VERSION ""

NS_ :

BS_:

BU_: EHR_Spare FEHR_3 PTO_SpeedSelector Dummy_Node_Ch2 FEHR_2 TrailerBrake OffBoardDiagnosticTool1_Ch2 PowerTakeOff_Ch2 Transmission1_Ch2 FEHR_1 REHR_5 REHR_4 REHR_3 REHR_2 REHR_1 InstrumentCluster_Ch2 ManagementComputer_Ch2 GWAY_OnBoardDiagnosticUnit_Ch2 GWAY_OffBoardDiagTool1_VB1_Ch2 GWAY_Engine1_Ch2 GWAY_CabDisplay1_Ch2 AuxiliaryValveControl_Ch2
VAL_TABLE_ _________Vt_StatusFlag5 1 "On" 0 "Off" ;

BO_ 3221225472 VECTOR__INDEPENDENT_SIG_MSG: 0 Vector__XXX
 SG_ TrailerParkBrakeRequest : 0|2@1+ (1,0) [0|3] "" Vector__XXX
 SG_ SteeringBrakeDirection : 0|2@1+ (1,0) [0|3] "" Vector__XXX
 SG_ SecondaryBrakeSwitch : 0|2@1+ (1,0) [0|3] "" Vector__XXX
 SG_ PGN_RQST_F9_4C : 0|24@1+ (1,0) [0|16777200] "" Vector__XXX
 SG_ V5_Ref1 : 0|8@1+ (0.05,0) [0|12.75] "V" Vector__XXX
 SG_ V5_Ref2 : 0|8@1+ (0.05,0) [0|12.75] "V" Vector__XXX
 SG_ SensSupplyV_2Sts : 0|2@1+ (1,0) [0|3] "" Vector__XXX
 SG_ SensSupplyV_1 : 0|12@1+ (0.01,0) [0|40.15] "V" Vector__XXX
 SG_ V_12_VH1 : 0|12@1+ (0.01,0) [0|40.15] "V" Vector__XXX
 SG_ V_12_VF1 : 0|12@1+ (0.01,0) [0|40.15] "V" Vector__XXX
 SG_ CalibrOpMode : 0|4@1+ (1,0) [0|15] "" Vector__XXX
 SG_ CalibrVal : 0|10@1+ (1,0) [0|1000] "" Vector__XXX
 SG_ CalibrErrCod : 0|5@1+ (1,0) [0|31] "" Vector__XXX
 SG_ PrsSwSts : 0|2@1+ (1,0) [0|3] "" Vector__XXX
 SG_ CalibrPnt : 0|4@1+ (1,0) [0|15] "" Vector__XXX
 SG_ XPD_MsgCnt : 0|4@1+ (1,0) [0|15] "" Vector__XXX
 SG_ XPD_MsgChksum : 0|4@1+ (1,0) [0|15] "" Vector__XXX
 SG_ PBrakeActvReq : 0|2@1+ (1,0) [0|3] "" Vector__XXX
 SG_ AuxEquipSupplyPrs : 0|8@1+ (8,0) [0|2000] "kPa" Vector__XXX
 SG_ AirSuspnsnSupplyPrs : 0|8@1+ (8,0) [0|2000] "kPa" Vector__XXX
 SG_ AirComprSts : 0|2@1+ (1,0) [0|3] "" Vector__XXX
 SG_ PwtCircAirSupplyPrs : 0|8@1+ (8,0) [0|2000] "kPa" Vector__XXX
 SG_ EngIdleIncSw : 0|2@1+ (1,0) [0|3] "" Vector__XXX
 SG_ EngIdleDecrSw : 0|2@1+ (1,0) [0|3] "" Vector__XXX
 SG_ EngTestModeSw : 0|2@1+ (1,0) [0|3] "" Vector__XXX
 SG_ EngShutdnOverrideSw : 0|2@1+ (1,0) [0|3] "" Vector__XXX
 SG_ EHR_EvNumParamMux_F1 : 0|8@1+ (1,0) [0|255] "" Vector__XXX
 SG_ EHR_EvNumParamMux_F2 : 0|8@1+ (1,0) [0|255] "" Vector__XXX
 SG_ EHR_EvNumParamMux_F3 : 0|8@1+ (1,0) [0|255] "" Vector__XXX
 SG_ EHR_EvNumParamMux_F4 : 0|8@1+ (1,0) [0|255] "" Vector__XXX
 SG_ BrakeSw : 0|2@1+ (1,0) [0|3] "" Vector__XXX
 SG_ CC_AccelSw : 0|2@1+ (1,0) [0|3] "" Vector__XXX
 SG_ CC_Actv : 0|2@1+ (1,0) [0|3] "" Vector__XXX
 SG_ MsgChksum_2 : 0|4@1+ (1,0) [0|15] "count" Vector__XXX
 SG_ CC_CoastDecelSw : 0|2@1+ (1,0) [0|3] "" Vector__XXX
 SG_ CC_EnaSw : 0|2@1+ (1,0) [0|3] "" Vector__XXX
 SG_ CC_PauseSw : 0|2@1+ (1,0) [0|3] "" Vector__XXX
 SG_ CC_ResumSw : 0|2@1+ (1,0) [0|3] "" Vector__XXX
 SG_ CC_SetSpd : 0|8@1+ (1,0) [0|250] "km/h" Vector__XXX
 SG_ CC_SetSw : 0|2@1+ (1,0) [0|3] "" Vector__XXX
 SG_ CC_Sts : 0|3@1+ (1,0) [0|7] "" Vector__XXX
 SG_ CltchSw : 0|2@1+ (1,0) [0|3] "" Vector__XXX
 SG_ N2SpdAxSw : 0|2@1+ (1,0) [0|3] "" Vector__XXX
 SG_ PBrakeRleasInhReq : 0|2@1+ (1,0) [0|3] "" Vector__XXX
 SG_ PBrakeSw : 0|2@1+ (1,0) [0|3] "" Vector__XXX
 SG_ PTO_GovSts : 0|5@1+ (1,0) [0|31] "" Vector__XXX

BO_ 2565350026 ACKM_8A_22: 8 FEHR_2
 SG_ AddrAccssDeny m2 : 32|8@1+ (1,0) [0|255] ""  AuxiliaryValveControl_Ch2
 SG_ AddrAck m0 : 32|8@1+ (1,0) [0|255] ""  AuxiliaryValveControl_Ch2
 SG_ AddrBusy m3 : 32|8@1+ (1,0) [0|255] ""  AuxiliaryValveControl_Ch2
 SG_ AddrNegAck m1 : 32|8@1+ (1,0) [0|255] ""  AuxiliaryValveControl_Ch2
 SG_ CByteAckm M : 0|8@1+ (1,0) [0|255] ""  AuxiliaryValveControl_Ch2
 SG_ GrpFunctValAck m0 : 8|8@1+ (1,0) [0|255] ""  AuxiliaryValveControl_Ch2
 SG_ GrpFunctValNAck m1 : 8|8@1+ (1,0) [0|255] ""  AuxiliaryValveControl_Ch2
 SG_ GrpFunctValNAckAd m2 : 8|8@1+ (1,0) [0|255] ""  AuxiliaryValveControl_Ch2
 SG_ GrpFunctValNAckBusy m3 : 8|8@1+ (1,0) [0|255] ""  AuxiliaryValveControl_Ch2
 SG_ PGN_Ack m0 : 40|24@1+ (1,0) [0|16777200] ""  AuxiliaryValveControl_Ch2
 SG_ PGN_NAck m1 : 40|24@1+ (1,0) [0|16777200] ""  AuxiliaryValveControl_Ch2
 SG_ PGN_NAckAd m2 : 40|24@1+ (1,0) [0|16777200] ""  AuxiliaryValveControl_Ch2
 SG_ PGN_NAckBusy m3 : 40|24@1+ (1,0) [0|16777200] ""  AuxiliaryValveControl_Ch2

BO_ 2566835082 DM2_8A: 18 FEHR_2
 SG_ AmbrWarnLmp : 2|2@1+ (1,0) [0|3] ""  AuxiliaryValveControl_Ch2
 SG_ DTC_01 : 16|32@1+ (1,0) [0|4294970000] ""  AuxiliaryValveControl_Ch2
 SG_ DTC_02 : 48|32@1+ (1,0) [0|4294970000] ""  AuxiliaryValveControl_Ch2
 SG_ DTC_03 : 80|32@1+ (1,0) [0|4294970000] ""  AuxiliaryValveControl_Ch2
 SG_ DTC_04 : 112|32@1+ (1,0) [0|4294970000] ""  AuxiliaryValveControl_Ch2
 SG_ FlashAmbrWarnLmpAWL : 10|2@1+ (1,0) [0|3] ""  AuxiliaryValveControl_Ch2
 SG_ FlashMIL : 14|2@1+ (1,0) [0|3] ""  AuxiliaryValveControl_Ch2
 SG_ FlashProtLmp : 8|2@1+ (1,0) [0|3] ""  AuxiliaryValveControl_Ch2
 SG_ FlashRedStopLmpRSL : 12|2@1+ (1,0) [0|3] ""  AuxiliaryValveControl_Ch2
 SG_ MIL : 6|2@1+ (1,0) [0|3] ""  AuxiliaryValveControl_Ch2
 SG_ ProtLmp : 0|2@1+ (1,0) [0|3] ""  AuxiliaryValveControl_Ch2
 SG_ RedStopLmp : 4|2@1+ (1,0) [0|3] ""  AuxiliaryValveControl_Ch2

BO_ 2566838922 SOFT_8A: 89 FEHR_2
 SG_ Appl_Id_Byte_24 : 552|8@1+ (1,0) [0|255] ""  AuxiliaryValveControl_Ch2
 SG_ Appl_Id_Byte_25 : 560|8@1+ (1,0) [0|255] ""  AuxiliaryValveControl_Ch2
 SG_ Appl_Id_Byte_26 : 568|8@1+ (1,0) [0|255] ""  AuxiliaryValveControl_Ch2
 SG_ Appl_Id_Byte_27 : 576|8@1+ (1,0) [0|255] ""  AuxiliaryValveControl_Ch2
 SG_ Appl_Id_Byte_28 : 584|8@1+ (1,0) [0|255] ""  AuxiliaryValveControl_Ch2
 SG_ Appl_Id_Byte_29 : 592|8@1+ (1,0) [0|255] ""  AuxiliaryValveControl_Ch2
 SG_ Appl_Id_Byte_30 : 600|8@1+ (1,0) [0|255] ""  AuxiliaryValveControl_Ch2
 SG_ Appl_Id_Byte_31 : 608|8@1+ (1,0) [0|255] ""  AuxiliaryValveControl_Ch2
 SG_ Appl_Id_Byte_32 : 616|8@1+ (1,0) [0|255] ""  AuxiliaryValveControl_Ch2
 SG_ Appl_Id_Byte_33 : 624|8@1+ (1,0) [0|255] ""  AuxiliaryValveControl_Ch2
 SG_ Appl_Id_Byte_34 : 632|8@1+ (1,0) [0|255] ""  AuxiliaryValveControl_Ch2
 SG_ Appl_Id_Byte_35 : 640|8@1+ (1,0) [0|255] ""  AuxiliaryValveControl_Ch2
 SG_ Appl_Id_Byte_36 : 648|8@1+ (1,0) [0|255] ""  AuxiliaryValveControl_Ch2
 SG_ Appl_Id_Byte_37 : 656|8@1+ (1,0) [0|255] ""  AuxiliaryValveControl_Ch2
 SG_ Appl_Id_Byte_38 : 664|8@1+ (1,0) [0|255] ""  AuxiliaryValveControl_Ch2
 SG_ Appl_Id_Byte_39 : 672|8@1+ (1,0) [0|255] ""  AuxiliaryValveControl_Ch2
 SG_ Appl_Id_Enum : 680|24@1+ (1,0) [0|16777215] ""  AuxiliaryValveControl_Ch2
 SG_ Bootloader_Id : 360|8@1+ (1,0) [0|255] ""  AuxiliaryValveControl_Ch2
 SG_ Bootloader_Id_Byte_01 : 16|8@1+ (1,0) [0|255] ""  AuxiliaryValveControl_Ch2
 SG_ Bootloader_Id_Byte_02 : 24|8@1+ (1,0) [0|255] ""  AuxiliaryValveControl_Ch2
 SG_ Bootloader_Id_Byte_03 : 32|8@1+ (1,0) [0|255] ""  AuxiliaryValveControl_Ch2
 SG_ Bootloader_Id_Byte_04 : 40|8@1+ (1,0) [0|255] ""  AuxiliaryValveControl_Ch2
 SG_ Bootloader_Id_Byte_05 : 48|8@1+ (1,0) [0|255] ""  AuxiliaryValveControl_Ch2
 SG_ Bootloader_Id_Byte_06 : 56|8@1+ (1,0) [0|255] ""  AuxiliaryValveControl_Ch2
 SG_ Bootloader_Id_Byte_07 : 64|8@1+ (1,0) [0|255] ""  AuxiliaryValveControl_Ch2
 SG_ Bootloader_Id_Byte_08 : 72|8@1+ (1,0) [0|255] ""  AuxiliaryValveControl_Ch2
 SG_ Bootloader_Id_Byte_09 : 80|8@1+ (1,0) [0|255] ""  AuxiliaryValveControl_Ch2
 SG_ Bootloader_Id_Byte_10 : 88|8@1+ (1,0) [0|255] ""  AuxiliaryValveControl_Ch2
 SG_ Bootloader_Id_Byte_11 : 96|8@1+ (1,0) [0|255] ""  AuxiliaryValveControl_Ch2
 SG_ Bootloader_Id_Byte_12 : 104|8@1+ (1,0) [0|255] ""  AuxiliaryValveControl_Ch2
 SG_ Bootloader_Id_Byte_13 : 112|8@1+ (1,0) [0|255] ""  AuxiliaryValveControl_Ch2
 SG_ Bootloader_Id_Byte_14 : 120|8@1+ (1,0) [0|255] ""  AuxiliaryValveControl_Ch2
 SG_ Bootloader_Id_Byte_15 : 128|8@1+ (1,0) [0|255] ""  AuxiliaryValveControl_Ch2
 SG_ Bootloader_Id_Byte_16 : 136|8@1+ (1,0) [0|255] ""  AuxiliaryValveControl_Ch2
 SG_ Bootloader_Id_Byte_17 : 144|8@1+ (1,0) [0|255] ""  AuxiliaryValveControl_Ch2
 SG_ Bootloader_Id_Byte_18 : 152|8@1+ (1,0) [0|255] ""  AuxiliaryValveControl_Ch2
 SG_ Bootloader_Id_Byte_19 : 160|8@1+ (1,0) [0|255] ""  AuxiliaryValveControl_Ch2
 SG_ Bootloader_Id_Byte_20 : 168|8@1+ (1,0) [0|255] ""  AuxiliaryValveControl_Ch2
 SG_ Bootloader_Id_Byte_21 : 176|8@1+ (1,0) [0|255] ""  AuxiliaryValveControl_Ch2
 SG_ Bootloader_Id_Byte_22 : 184|8@1+ (1,0) [0|255] ""  AuxiliaryValveControl_Ch2
 SG_ Bootloader_Id_Byte_23 : 192|8@1+ (1,0) [0|255] ""  AuxiliaryValveControl_Ch2
 SG_ Bootloader_Id_Byte_24 : 200|8@1+ (1,0) [0|255] ""  AuxiliaryValveControl_Ch2
 SG_ Bootloader_Id_Byte_25 : 208|8@1+ (1,0) [0|255] ""  AuxiliaryValveControl_Ch2
 SG_ Bootloader_Id_Byte_26 : 216|8@1+ (1,0) [0|255] ""  AuxiliaryValveControl_Ch2
 SG_ Bootloader_Id_Byte_27 : 224|8@1+ (1,0) [0|255] ""  AuxiliaryValveControl_Ch2
 SG_ Bootloader_Id_Byte_28 : 232|8@1+ (1,0) [0|255] ""  AuxiliaryValveControl_Ch2
 SG_ Bootloader_Id_Byte_29 : 240|8@1+ (1,0) [0|255] ""  AuxiliaryValveControl_Ch2
 SG_ Bootloader_Id_Byte_30 : 248|8@1+ (1,0) [0|255] ""  AuxiliaryValveControl_Ch2
 SG_ Bootloader_Id_Byte_31 : 256|8@1+ (1,0) [0|255] ""  AuxiliaryValveControl_Ch2
 SG_ Bootloader_Id_Byte_32 : 264|8@1+ (1,0) [0|255] ""  AuxiliaryValveControl_Ch2
 SG_ Bootloader_Id_Byte_33 : 272|8@1+ (1,0) [0|255] ""  AuxiliaryValveControl_Ch2
 SG_ Bootloader_Id_Byte_34 : 280|8@1+ (1,0) [0|255] ""  AuxiliaryValveControl_Ch2
 SG_ Bootloader_Id_Byte_35 : 288|8@1+ (1,0) [0|255] ""  AuxiliaryValveControl_Ch2
 SG_ Bootloader_Id_Byte_36 : 296|8@1+ (1,0) [0|255] ""  AuxiliaryValveControl_Ch2
 SG_ Bootloader_Id_Byte_37 : 304|8@1+ (1,0) [0|255] ""  AuxiliaryValveControl_Ch2
 SG_ Bootloader_Id_Byte_38 : 312|8@1+ (1,0) [0|255] ""  AuxiliaryValveControl_Ch2
 SG_ Bootloader_Id_Byte_39 : 320|8@1+ (1,0) [0|255] ""  AuxiliaryValveControl_Ch2
 SG_ Bootloader_Id_Enum : 328|24@1+ (1,0) [0|16777215] ""  AuxiliaryValveControl_Ch2
 SG_ EndStrng_00 : 352|8@1+ (1,0) [0|255] "per byte"  AuxiliaryValveControl_Ch2
 SG_ EndStrng_01 : 704|8@1+ (1,0) [0|255] "per byte"  AuxiliaryValveControl_Ch2
 SG_ NumSW_IdField : 0|8@1+ (1,0) [0|250] "step"  AuxiliaryValveControl_Ch2
 SG_ Appl_Id : 8|8@1+ (1,0) [0|255] ""  AuxiliaryValveControl_Ch2
 SG_ Appl_Id_Byte_01 : 368|8@1+ (1,0) [0|255] ""  AuxiliaryValveControl_Ch2
 SG_ Appl_Id_Byte_02 : 376|8@1+ (1,0) [0|255] ""  AuxiliaryValveControl_Ch2
 SG_ Appl_Id_Byte_03 : 384|8@1+ (1,0) [0|255] ""  AuxiliaryValveControl_Ch2
 SG_ Appl_Id_Byte_04 : 392|8@1+ (1,0) [0|255] ""  AuxiliaryValveControl_Ch2
 SG_ Appl_Id_Byte_05 : 400|8@1+ (1,0) [0|255] ""  AuxiliaryValveControl_Ch2
 SG_ Appl_Id_Byte_06 : 408|8@1+ (1,0) [0|255] ""  AuxiliaryValveControl_Ch2
 SG_ Appl_Id_Byte_07 : 416|8@1+ (1,0) [0|255] ""  AuxiliaryValveControl_Ch2
 SG_ Appl_Id_Byte_08 : 424|8@1+ (1,0) [0|255] ""  AuxiliaryValveControl_Ch2
 SG_ Appl_Id_Byte_09 : 432|8@1+ (1,0) [0|255] ""  AuxiliaryValveControl_Ch2
 SG_ Appl_Id_Byte_10 : 440|8@1+ (1,0) [0|255] ""  AuxiliaryValveControl_Ch2
 SG_ Appl_Id_Byte_11 : 448|8@1+ (1,0) [0|255] ""  AuxiliaryValveControl_Ch2
 SG_ Appl_Id_Byte_12 : 456|8@1+ (1,0) [0|255] ""  AuxiliaryValveControl_Ch2
 SG_ Appl_Id_Byte_13 : 464|8@1+ (1,0) [0|255] ""  AuxiliaryValveControl_Ch2
 SG_ Appl_Id_Byte_14 : 472|8@1+ (1,0) [0|255] ""  AuxiliaryValveControl_Ch2
 SG_ Appl_Id_Byte_15 : 480|8@1+ (1,0) [0|255] ""  AuxiliaryValveControl_Ch2
 SG_ Appl_Id_Byte_16 : 488|8@1+ (1,0) [0|255] ""  AuxiliaryValveControl_Ch2
 SG_ Appl_Id_Byte_17 : 496|8@1+ (1,0) [0|255] ""  AuxiliaryValveControl_Ch2
 SG_ Appl_Id_Byte_18 : 504|8@1+ (1,0) [0|255] ""  AuxiliaryValveControl_Ch2
 SG_ Appl_Id_Byte_19 : 512|8@1+ (1,0) [0|255] ""  AuxiliaryValveControl_Ch2
 SG_ Appl_Id_Byte_20 : 520|8@1+ (1,0) [0|255] ""  AuxiliaryValveControl_Ch2
 SG_ Appl_Id_Byte_21 : 528|8@1+ (1,0) [0|255] ""  AuxiliaryValveControl_Ch2
 SG_ Appl_Id_Byte_22 : 536|8@1+ (1,0) [0|255] ""  AuxiliaryValveControl_Ch2
 SG_ Appl_Id_Byte_23 : 544|8@1+ (1,0) [0|255] ""  AuxiliaryValveControl_Ch2

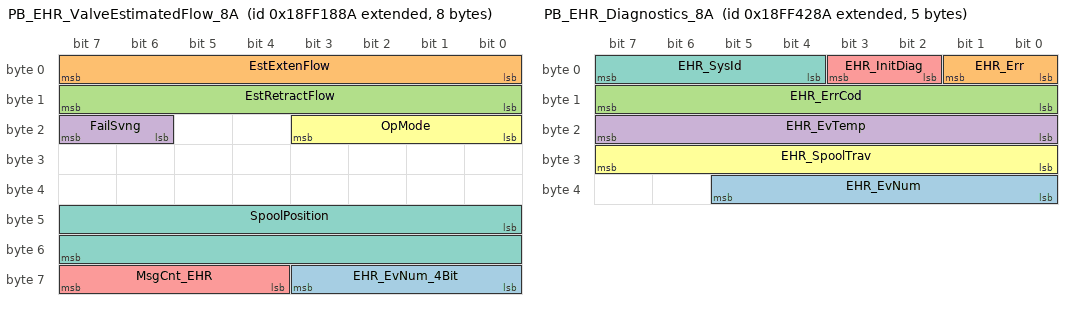
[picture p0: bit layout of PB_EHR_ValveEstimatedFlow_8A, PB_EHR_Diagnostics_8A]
BO_ 2566854794 PB_EHR_ValveEstimatedFlow_8A: 8 FEHR_2
 SG_ EHR_EvNum_4Bit : 56|4@1+ (1,0) [0|15] ""  AuxiliaryValveControl_Ch2
 SG_ EstExtenFlow : 0|8@1+ (0.8,-102.4) [0|100] "%"  AuxiliaryValveControl_Ch2
 SG_ EstRetractFlow : 8|8@1+ (0.8,-102.4) [0|100] "%"  AuxiliaryValveControl_Ch2
 SG_ FailSvng : 22|2@1+ (1,0) [0|3] ""  AuxiliaryValveControl_Ch2
 SG_ MsgCnt_EHR : 60|4@1+ (1,0) [0|12] "count"  AuxiliaryValveControl_Ch2
 SG_ OpMode : 16|4@1+ (1,0) [0|15] ""  AuxiliaryValveControl_Ch2
 SG_ SpoolPosition : 40|16@1+ (1,0) [0|1023] ""  AuxiliaryValveControl_Ch2

BO_ 2566866058 PB_EHR_ParameterStatus_8A: 8 FEHR_2
 SG_ EHR_EvNumParamMux_12 : 24|8@1+ (1,0) [0|255] ""  AuxiliaryValveControl_Ch2
 SG_ EHR_ParamByte_1 : 0|8@1+ (1,0) [0|255] ""  AuxiliaryValveControl_Ch2
 SG_ EHR_ParamStsByte_2 : 8|8@1+ (1,0) [0|255] ""  AuxiliaryValveControl_Ch2
 SG_ EHR_ParamStsByte_3 M : 16|8@1+ (1,0) [0|255] ""  AuxiliaryValveControl_Ch2
 SG_ EHR_RmpRndng m103 : 32|8@1+ (1,0) [0|255] ""  AuxiliaryValveControl_Ch2
 SG_ EHR_ChksumSW m80 : 40|8@1+ (1,0) [0|255] ""  AuxiliaryValveControl_Ch2
 SG_ EHR_ChksumStor m80 : 32|8@1+ (1,0) [0|255] ""  AuxiliaryValveControl_Ch2

BO_ 2566865546 PB_EHR_Diagnostics_8A: 5 FEHR_2
 SG_ EHR_EvNum : 32|6@1+ (1,0) [0|63] ""  AuxiliaryValveControl_Ch2
 SG_ EHR_Err : 0|2@1+ (1,0) [0|3] ""  AuxiliaryValveControl_Ch2
 SG_ EHR_ErrCod : 8|8@1+ (1,0) [0|254] ""  AuxiliaryValveControl_Ch2
 SG_ EHR_EvTemp : 16|8@1+ (1,-80) [-40|120] "Deg C"  AuxiliaryValveControl_Ch2
 SG_ EHR_InitDiag : 2|2@1+ (1,0) [0|3] ""  AuxiliaryValveControl_Ch2
 SG_ EHR_SpoolTrav : 24|8@1+ (1,0) [0|254] ""  AuxiliaryValveControl_Ch2
 SG_ EHR_SysId : 4|4@1+ (1,0) [0|15] ""  AuxiliaryValveControl_Ch2

BO_ 2564487562 ISO15765_Phys_8A_F9: 8 FEHR_2
 SG_ ProtocCntrlInfo M : 4|4@1+ (1,0) [0|3] ""  OffBoardDiagnosticTool1_Ch2
 SG_ SingFrameDataLen m0 : 0|4@1+ (1,0) [0|7] "Byte" Vector__XXX
 SG_ N1FrameDataLen m1 : 3|12@0+ (1,0) [0|4095] "Byte" Vector__XXX
 SG_ FlowSts m3 : 0|4@1+ (1,0) [0|3] "" Vector__XXX
 SG_ BlkSize m3 : 8|8@1+ (1,0) [0|255] "" Vector__XXX
 SG_ SepTime m3 : 16|8@1+ (1,0) [0|255] "ms" Vector__XXX
 SG_ SN m2 : 0|4@1+ (1,0) [0|15] "" Vector__XXX

BO_ 2566843274 CI_8A: 38 FEHR_2
 SG_ UnitNumPwrUnit : 208|8@1+ (1,0) [0|255] "ASCII"  Dummy_Node_Ch2
 SG_ SN_2_Byte_15 : 200|8@1+ (1,0) [0|255] "per byte"  Dummy_Node_Ch2
 SG_ SN_2_Byte_14 : 192|8@1+ (1,0) [0|255] "per byte"  Dummy_Node_Ch2
 SG_ SN_2_Byte_13 : 184|8@1+ (1,0) [0|255] "per byte"  Dummy_Node_Ch2
 SG_ SN_2_Byte_12 : 176|8@1+ (1,0) [0|255] "per byte"  Dummy_Node_Ch2
 SG_ SN_2_Byte_11 : 168|8@1+ (1,0) [0|255] "per byte"  Dummy_Node_Ch2
 SG_ SN_2_Byte_10 : 160|8@1+ (1,0) [0|255] "per byte"  Dummy_Node_Ch2
 SG_ SN_2_Byte_09 : 152|8@1+ (1,0) [0|255] "per byte"  Dummy_Node_Ch2
 SG_ SN_2_Byte_08 : 144|8@1+ (1,0) [0|255] "per byte"  Dummy_Node_Ch2
 SG_ SN_2_Byte_07 : 136|8@1+ (1,0) [0|255] "per byte"  Dummy_Node_Ch2
 SG_ SN_2_Byte_06 : 128|8@1+ (1,0) [0|255] "per byte"  Dummy_Node_Ch2
 SG_ SN_2_Byte_05 : 120|8@1+ (1,0) [0|255] "per byte"  Dummy_Node_Ch2
 SG_ SN_2_Byte_04 : 112|8@1+ (1,0) [0|255] "per byte"  Dummy_Node_Ch2
 SG_ SN_2_Byte_03 : 104|8@1+ (1,0) [0|255] "per byte"  Dummy_Node_Ch2
 SG_ SN_2_Byte_02 : 96|8@1+ (1,0) [0|255] "per byte"  Dummy_Node_Ch2
 SG_ SN_2_Byte_01 : 88|8@1+ (1,0) [0|255] "per byte"  Dummy_Node_Ch2
 SG_ SN_2 : 80|8@1+ (1,0) [0|255] "ASCII"  Dummy_Node_Ch2
 SG_ Mdl_Byte_08 : 72|8@1+ (1,0) [0|255] "ASCII"  Dummy_Node_Ch2
 SG_ Mdl_Byte_07 : 64|8@1+ (1,0) [0|255] "ASCII"  Dummy_Node_Ch2
 SG_ Mdl_Byte_06 : 56|8@1+ (1,0) [0|255] "ASCII"  Dummy_Node_Ch2
 SG_ Mdl_Byte_05 : 48|8@1+ (1,0) [0|255] "ASCII"  Dummy_Node_Ch2
 SG_ Mdl_Byte_04 : 40|8@1+ (1,0) [0|255] "ASCII"  Dummy_Node_Ch2
 SG_ Mdl_Byte_03 : 32|8@1+ (1,0) [0|255] "ASCII"  Dummy_Node_Ch2
 SG_ Mdl_Byte_02 : 24|8@1+ (1,0) [0|255] "ASCII"  Dummy_Node_Ch2
 SG_ Mdl_Byte_01 : 16|8@1+ (1,0) [0|255] "ASCII"  Dummy_Node_Ch2
 SG_ Make : 0|8@1+ (1,0) [0|255] "ASCII"  Dummy_Node_Ch2
 SG_ Mdl : 8|8@1+ (1,0) [0|255] "ASCII"  Dummy_Node_Ch2

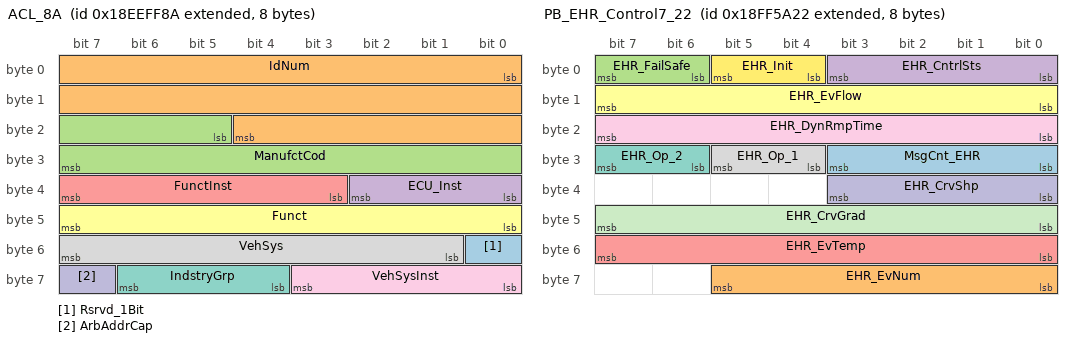
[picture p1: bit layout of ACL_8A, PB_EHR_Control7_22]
BO_ 2565799818 ACL_8A: 8 FEHR_2
 SG_ Rsrvd_1Bit : 48|1@1+ (1,0) [0|1] ""  OffBoardDiagnosticTool1_Ch2,AuxiliaryValveControl_Ch2
 SG_ IdNum : 0|21@1+ (1,0) [0|2097151] ""  OffBoardDiagnosticTool1_Ch2,AuxiliaryValveControl_Ch2
 SG_ ManufctCod : 21|11@1+ (1,0) [0|2047] ""  OffBoardDiagnosticTool1_Ch2,AuxiliaryValveControl_Ch2
 SG_ ECU_Inst : 32|3@1+ (1,0) [0|7] ""  OffBoardDiagnosticTool1_Ch2,AuxiliaryValveControl_Ch2
 SG_ FunctInst : 35|5@1+ (1,0) [0|31] ""  OffBoardDiagnosticTool1_Ch2,AuxiliaryValveControl_Ch2
 SG_ Funct : 40|8@1+ (1,0) [0|255] ""  OffBoardDiagnosticTool1_Ch2,AuxiliaryValveControl_Ch2
 SG_ IndstryGrp : 60|3@1+ (1,0) [0|7] ""  OffBoardDiagnosticTool1_Ch2,AuxiliaryValveControl_Ch2
 SG_ VehSys : 49|7@1+ (1,0) [0|127] ""  OffBoardDiagnosticTool1_Ch2,AuxiliaryValveControl_Ch2
 SG_ VehSysInst : 56|4@1+ (1,0) [0|15] ""  OffBoardDiagnosticTool1_Ch2,AuxiliaryValveControl_Ch2
 SG_ ArbAddrCap : 63|1@1+ (1,0) [0|1] ""  OffBoardDiagnosticTool1_Ch2,AuxiliaryValveControl_Ch2

BO_ 2566871586 PB_EHR_Control7_22: 8 AuxiliaryValveControl_Ch2
 SG_ MsgCnt_EHR : 24|4@1+ (1,0) [0|12] "count"  FEHR_2
 SG_ EHR_EvNum : 56|6@1+ (1,0) [0|63] ""  FEHR_2
 SG_ EHR_FailSafe : 6|2@1+ (1,0) [0|3] ""  FEHR_2
 SG_ EHR_CntrlSts : 0|4@1+ (1,0) [0|15] ""  FEHR_2
 SG_ EHR_EvTemp : 48|8@1+ (1,-80) [-40|120] "Deg C"  FEHR_2
 SG_ EHR_EvFlow : 8|8@1+ (0.3937,0) [0|100] "%"  FEHR_2
 SG_ EHR_Op_2 : 30|2@1+ (1,0) [0|3] ""  FEHR_2
 SG_ EHR_Op_1 : 28|2@1+ (1,0) [0|3] ""  FEHR_2
 SG_ EHR_DynRmpTime : 16|8@1+ (32,0) [0|8128] "ms"  FEHR_2
 SG_ EHR_CrvShp : 32|4@1+ (1,0) [0|15] ""  FEHR_2
 SG_ EHR_CrvGrad : 40|8@1+ (0.3922,0) [0|100] "%"  FEHR_2
 SG_ EHR_Init : 4|2@1+ (1,0) [0|3] ""  FEHR_2

BO_ 2566843265 CI_81: 38 REHR_2
 SG_ UnitNumPwrUnit : 208|8@1+ (1,0) [0|255] "ASCII"  Dummy_Node_Ch2
 SG_ SN_2_Byte_15 : 200|8@1+ (1,0) [0|255] "per byte"  Dummy_Node_Ch2
 SG_ SN_2_Byte_14 : 192|8@1+ (1,0) [0|255] "per byte"  Dummy_Node_Ch2
 SG_ SN_2_Byte_13 : 184|8@1+ (1,0) [0|255] "per byte"  Dummy_Node_Ch2
 SG_ SN_2_Byte_12 : 176|8@1+ (1,0) [0|255] "per byte"  Dummy_Node_Ch2
 SG_ SN_2_Byte_11 : 168|8@1+ (1,0) [0|255] "per byte"  Dummy_Node_Ch2
 SG_ SN_2_Byte_10 : 160|8@1+ (1,0) [0|255] "per byte"  Dummy_Node_Ch2
 SG_ SN_2_Byte_09 : 152|8@1+ (1,0) [0|255] "per byte"  Dummy_Node_Ch2
 SG_ SN_2_Byte_08 : 144|8@1+ (1,0) [0|255] "per byte"  Dummy_Node_Ch2
 SG_ SN_2_Byte_07 : 136|8@1+ (1,0) [0|255] "per byte"  Dummy_Node_Ch2
 SG_ SN_2_Byte_06 : 128|8@1+ (1,0) [0|255] "per byte"  Dummy_Node_Ch2
 SG_ SN_2_Byte_05 : 120|8@1+ (1,0) [0|255] "per byte"  Dummy_Node_Ch2
 SG_ SN_2_Byte_04 : 112|8@1+ (1,0) [0|255] "per byte"  Dummy_Node_Ch2
 SG_ SN_2_Byte_03 : 104|8@1+ (1,0) [0|255] "per byte"  Dummy_Node_Ch2
 SG_ SN_2_Byte_02 : 96|8@1+ (1,0) [0|255] "per byte"  Dummy_Node_Ch2
 SG_ SN_2_Byte_01 : 88|8@1+ (1,0) [0|255] "per byte"  Dummy_Node_Ch2
 SG_ SN_2 : 80|8@1+ (1,0) [0|255] "ASCII"  Dummy_Node_Ch2
 SG_ Mdl_Byte_08 : 72|8@1+ (1,0) [0|255] "ASCII"  Dummy_Node_Ch2
 SG_ Mdl_Byte_07 : 64|8@1+ (1,0) [0|255] "ASCII"  Dummy_Node_Ch2
 SG_ Mdl_Byte_06 : 56|8@1+ (1,0) [0|255] "ASCII"  Dummy_Node_Ch2
 SG_ Mdl_Byte_05 : 48|8@1+ (1,0) [0|255] "ASCII"  Dummy_Node_Ch2
 SG_ Mdl_Byte_04 : 40|8@1+ (1,0) [0|255] "ASCII"  Dummy_Node_Ch2
 SG_ Mdl_Byte_03 : 32|8@1+ (1,0) [0|255] "ASCII"  Dummy_Node_Ch2
 SG_ Mdl_Byte_02 : 24|8@1+ (1,0) [0|255] "ASCII"  Dummy_Node_Ch2
 SG_ Mdl_Byte_01 : 16|8@1+ (1,0) [0|255] "ASCII"  Dummy_Node_Ch2
 SG_ Make : 0|8@1+ (1,0) [0|255] "ASCII"  Dummy_Node_Ch2
 SG_ Mdl : 8|8@1+ (1,0) [0|255] "ASCII"  Dummy_Node_Ch2

BO_ 2564487553 ISO15765_Phys_81_F9: 8 REHR_2
 SG_ SepTime m3 : 16|8@1+ (1,0) [0|255] "ms"  OffBoardDiagnosticTool1_Ch2
 SG_ SingFrameDataLen m0 : 0|4@1+ (1,0) [0|7] "Byte"  OffBoardDiagnosticTool1_Ch2
 SG_ N1FrameDataLen m1 : 3|12@0+ (1,0) [0|4095] "Byte"  OffBoardDiagnosticTool1_Ch2
 SG_ BlkSize m3 : 8|8@1+ (1,0) [0|255] ""  OffBoardDiagnosticTool1_Ch2
 SG_ FlowSts m3 : 0|4@1+ (1,0) [0|3] ""  OffBoardDiagnosticTool1_Ch2
 SG_ SN m2 : 0|4@1+ (1,0) [0|15] ""  OffBoardDiagnosticTool1_Ch2
 SG_ ProtocCntrlInfo M : 4|4@1+ (1,0) [0|3] ""  OffBoardDiagnosticTool1_Ch2

BO_ 2632777721 TPCM_F9: 8 OffBoardDiagnosticTool1_Ch2
 SG_ CByteTPCM M : 0|8@1+ (1,0) [0|255] ""  FEHR_3,FEHR_2,FEHR_1,REHR_5,REHR_4,REHR_3,REHR_2,REHR_1
 SG_ TotMsgSizeTPCM_RTS m16 : 8|16@1+ (1,0) [0|64255] "counts"  FEHR_3,FEHR_2,FEHR_1,REHR_5,REHR_4,REHR_3,REHR_2,REHR_1
 SG_ TotNumPktTPCM_RTS m16 : 24|8@1+ (1,0) [0|255] ""  FEHR_3,FEHR_2,FEHR_1,REHR_5,REHR_4,REHR_3,REHR_2,REHR_1
 SG_ MaxNumPktTPCM_RTS m16 : 32|8@1+ (1,0) [0|255] ""  FEHR_3,FEHR_2,FEHR_1,REHR_5,REHR_4,REHR_3,REHR_2,REHR_1
 SG_ PGN_PktMsgTPCM_RTS m16 : 40|24@1+ (1,0) [0|16777200] ""  FEHR_3,FEHR_2,FEHR_1,REHR_5,REHR_4,REHR_3,REHR_2,REHR_1
 SG_ NumPktSentTPCM_CTS m17 : 8|8@1+ (1,0) [0|255] ""  FEHR_3,FEHR_2,FEHR_1,REHR_5,REHR_4,REHR_3,REHR_2,REHR_1
 SG_ NxtPktNumSentTPCM_CTS m17 : 16|8@1+ (1,0) [0|255] ""  FEHR_3,FEHR_2,FEHR_1,REHR_5,REHR_4,REHR_3,REHR_2,REHR_1
 SG_ ConnAbrtReason m255 : 8|8@1+ (1,0) [0|255] ""  FEHR_3,FEHR_2,FEHR_1,REHR_5,REHR_4,REHR_3,REHR_2,REHR_1
 SG_ TotNumPktBAM m32 : 24|8@1+ (1,0) [0|255] ""  FEHR_3,FEHR_2,FEHR_1,REHR_5,REHR_4,REHR_3,REHR_2,REHR_1
 SG_ TotMsgSizeBAM m32 : 8|16@1+ (1,0) [0|64255] "counts"  FEHR_3,FEHR_2,FEHR_1,REHR_5,REHR_4,REHR_3,REHR_2,REHR_1
 SG_ TotMsgSizeEoMA m19 : 8|16@1+ (1,0) [0|64255] "counts"  FEHR_3,FEHR_2,FEHR_1,REHR_5,REHR_4,REHR_3,REHR_2,REHR_1
 SG_ TotNumPktEoMA m19 : 24|8@1+ (1,0) [0|255] ""  FEHR_3,FEHR_2,FEHR_1,REHR_5,REHR_4,REHR_3,REHR_2,REHR_1
 SG_ PGN_PktMsgTPCM_ConnAbort m255 : 40|24@1+ (1,0) [0|16777200] ""  FEHR_3,FEHR_2,FEHR_1,REHR_5,REHR_4,REHR_3,REHR_2,REHR_1
 SG_ PGN_PktMsgTPCM_BAM m32 : 40|24@1+ (1,0) [0|16777200] ""  FEHR_3,FEHR_2,FEHR_1,REHR_5,REHR_4,REHR_3,REHR_2,REHR_1
 SG_ PGN_PktMsgTPCM_RTS2 m19 : 40|24@1+ (1,0) [0|16777200] ""  FEHR_3,FEHR_2,FEHR_1,REHR_5,REHR_4,REHR_3,REHR_2,REHR_1
 SG_ PGN_PktMsgTPCM_CTS m17 : 40|24@1+ (1,0) [0|16777200] ""  FEHR_3,FEHR_2,FEHR_1,REHR_5,REHR_4,REHR_3,REHR_2,REHR_1

BO_ 2566838521 CA_F9: 9 OffBoardDiagnosticTool1_Ch2
 SG_ NameCmdAddrTarg : 0|64@1+ (1,0) [0|1] ""  FEHR_3,FEHR_2,FEHR_1,REHR_5,REHR_4,REHR_3,REHR_2,REHR_1
 SG_ AddrAssignNewSA : 64|8@1+ (1,0) [0|255] ""  FEHR_3,FEHR_2,FEHR_1,REHR_5,REHR_4,REHR_3,REHR_2,REHR_1

BO_ 2564456697 ISO15765_Phys_F9_80: 8 OffBoardDiagnosticTool1_Ch2
 SG_ BlkSize m3 : 8|8@1+ (1,0) [0|255] ""  REHR_1
 SG_ FlowSts m3 : 0|4@1+ (1,0) [0|3] ""  REHR_1
 SG_ N1FrameDataLen m1 : 3|12@0+ (1,0) [0|4095] "Byte"  REHR_1
 SG_ ProtocCntrlInfo M : 4|4@1+ (1,0) [0|3] ""  REHR_1
 SG_ SepTime m3 : 16|8@1+ (1,0) [0|255] "ms"  REHR_1
 SG_ SingFrameDataLen m0 : 0|4@1+ (1,0) [0|7] "Byte"  REHR_1
 SG_ SN m2 : 0|4@1+ (1,0) [0|15] ""  REHR_1

BO_ 2566843264 CI_80: 38 REHR_1
 SG_ UnitNumPwrUnit : 208|8@1+ (1,0) [0|255] "ASCII"  Dummy_Node_Ch2
 SG_ SN_2_Byte_15 : 200|8@1+ (1,0) [0|255] "per byte"  Dummy_Node_Ch2
 SG_ SN_2_Byte_14 : 192|8@1+ (1,0) [0|255] "per byte"  Dummy_Node_Ch2
 SG_ SN_2_Byte_13 : 184|8@1+ (1,0) [0|255] "per byte"  Dummy_Node_Ch2
 SG_ SN_2_Byte_12 : 176|8@1+ (1,0) [0|255] "per byte"  Dummy_Node_Ch2
 SG_ SN_2_Byte_11 : 168|8@1+ (1,0) [0|255] "per byte"  Dummy_Node_Ch2
 SG_ SN_2_Byte_10 : 160|8@1+ (1,0) [0|255] "per byte"  Dummy_Node_Ch2
 SG_ SN_2_Byte_09 : 152|8@1+ (1,0) [0|255] "per byte"  Dummy_Node_Ch2
 SG_ SN_2_Byte_08 : 144|8@1+ (1,0) [0|255] "per byte"  Dummy_Node_Ch2
 SG_ SN_2_Byte_07 : 136|8@1+ (1,0) [0|255] "per byte"  Dummy_Node_Ch2
 SG_ SN_2_Byte_06 : 128|8@1+ (1,0) [0|255] "per byte"  Dummy_Node_Ch2
 SG_ SN_2_Byte_05 : 120|8@1+ (1,0) [0|255] "per byte"  Dummy_Node_Ch2
 SG_ SN_2_Byte_04 : 112|8@1+ (1,0) [0|255] "per byte"  Dummy_Node_Ch2
 SG_ SN_2_Byte_03 : 104|8@1+ (1,0) [0|255] "per byte"  Dummy_Node_Ch2
 SG_ SN_2_Byte_02 : 96|8@1+ (1,0) [0|255] "per byte"  Dummy_Node_Ch2
 SG_ Mdl_Byte_08 : 72|8@1+ (1,0) [0|255] "ASCII"  Dummy_Node_Ch2
 SG_ Mdl_Byte_07 : 64|8@1+ (1,0) [0|255] "ASCII"  Dummy_Node_Ch2
 SG_ Mdl_Byte_06 : 56|8@1+ (1,0) [0|255] "ASCII"  Dummy_Node_Ch2
 SG_ Mdl_Byte_05 : 48|8@1+ (1,0) [0|255] "ASCII"  Dummy_Node_Ch2
 SG_ Mdl_Byte_04 : 40|8@1+ (1,0) [0|255] "ASCII"  Dummy_Node_Ch2
 SG_ Mdl_Byte_03 : 32|8@1+ (1,0) [0|255] "ASCII"  Dummy_Node_Ch2
 SG_ Mdl_Byte_02 : 24|8@1+ (1,0) [0|255] "ASCII"  Dummy_Node_Ch2
 SG_ Mdl_Byte_01 : 16|8@1+ (1,0) [0|255] "ASCII"  Dummy_Node_Ch2
 SG_ SN_2_Byte_01 : 88|8@1+ (1,0) [0|255] "per byte"  Dummy_Node_Ch2
 SG_ SN_2 : 80|8@1+ (1,0) [0|255] "ASCII"  Dummy_Node_Ch2
 SG_ Make : 0|8@1+ (1,0) [0|255] "ASCII"  Dummy_Node_Ch2
 SG_ Mdl : 8|8@1+ (1,0) [0|255] "ASCII"  Dummy_Node_Ch2

BO_ 2564487552 ISO15765_Phys_80_F9: 8 REHR_1
 SG_ SepTime m3 : 16|8@1+ (1,0) [0|255] "ms"  OffBoardDiagnosticTool1_Ch2
 SG_ SingFrameDataLen m0 : 0|4@1+ (1,0) [0|7] "Byte"  OffBoardDiagnosticTool1_Ch2
 SG_ N1FrameDataLen m1 : 3|12@0+ (1,0) [0|4095] "Byte"  OffBoardDiagnosticTool1_Ch2
 SG_ BlkSize m3 : 8|8@1+ (1,0) [0|255] ""  OffBoardDiagnosticTool1_Ch2
 SG_ FlowSts m3 : 0|4@1+ (1,0) [0|3] ""  OffBoardDiagnosticTool1_Ch2
 SG_ SN m2 : 0|4@1+ (1,0) [0|15] ""  OffBoardDiagnosticTool1_Ch2
 SG_ ProtocCntrlInfo M : 4|4@1+ (1,0) [0|3] ""  OffBoardDiagnosticTool1_Ch2

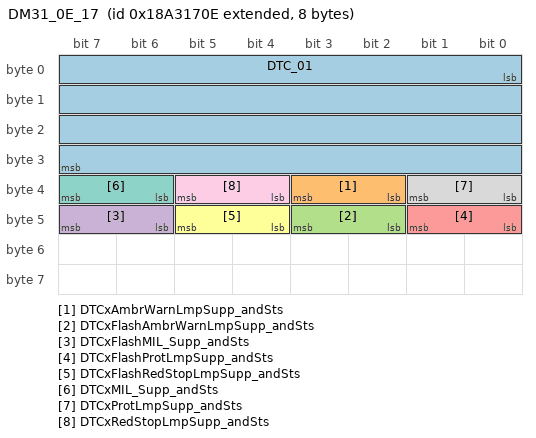
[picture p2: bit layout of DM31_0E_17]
BO_ 2560825102 DM31_0E_17: 8 TrailerBrake
 SG_ DTC_01 : 0|32@1+ (1,0) [0|4294970000] ""  InstrumentCluster_Ch2
 SG_ DTCxAmbrWarnLmpSupp_andSts : 34|2@1+ (1,0) [0|3] ""  InstrumentCluster_Ch2
 SG_ DTCxFlashAmbrWarnLmpSupp_andSts : 42|2@1+ (1,0) [0|3] ""  InstrumentCluster_Ch2
 SG_ DTCxFlashMIL_Supp_andSts : 46|2@1+ (1,0) [0|3] ""  InstrumentCluster_Ch2
 SG_ DTCxFlashProtLmpSupp_andSts : 40|2@1+ (1,0) [0|3] ""  InstrumentCluster_Ch2
 SG_ DTCxFlashRedStopLmpSupp_andSts : 44|2@1+ (1,0) [0|3] ""  InstrumentCluster_Ch2
 SG_ DTCxMIL_Supp_andSts : 38|2@1+ (1,0) [0|3] ""  InstrumentCluster_Ch2
 SG_ DTCxProtLmpSupp_andSts : 32|2@1+ (1,0) [0|3] ""  InstrumentCluster_Ch2
 SG_ DTCxRedStopLmpSupp_andSts : 36|2@1+ (1,0) [0|3] ""  InstrumentCluster_Ch2

BO_ 2632712073 TPDT_89: 8 FEHR_1
 SG_ PktDataTPDT : 8|56@1+ (1,0) [0|7.20575940379279E+16] ""  InstrumentCluster_Ch2
 SG_ SN_TPDT : 0|8@1+ (1,0) [0|255] ""  InstrumentCluster_Ch2

BO_ 2632712074 TPDT_8A: 8 FEHR_2
 SG_ PktDataTPDT : 8|56@1+ (1,0) [0|7.20575940379279E+16] ""  InstrumentCluster_Ch2
 SG_ SN_TPDT : 0|8@1+ (1,0) [0|255] ""  InstrumentCluster_Ch2

BO_ 2632777609 TPCM_89: 8 FEHR_1
 SG_ CByteTPCM M : 0|8@1+ (1,0) [0|255] ""  InstrumentCluster_Ch2
 SG_ ConnAbrtReason m255 : 8|8@1+ (1,0) [0|255] ""  InstrumentCluster_Ch2
 SG_ MaxNumPktTPCM_RTS m16 : 32|8@1+ (1,0) [0|255] ""  InstrumentCluster_Ch2
 SG_ NumPktSentTPCM_CTS m17 : 8|8@1+ (1,0) [0|255] ""  InstrumentCluster_Ch2
 SG_ NxtPktNumSentTPCM_CTS m17 : 16|8@1+ (1,0) [0|255] ""  InstrumentCluster_Ch2
 SG_ PGN_PktMsgTPCM_BAM m32 : 40|24@1+ (1,0) [0|16777200] ""  InstrumentCluster_Ch2
 SG_ PGN_PktMsgTPCM_ConnAbort m255 : 40|24@1+ (1,0) [0|16777200] ""  InstrumentCluster_Ch2
 SG_ PGN_PktMsgTPCM_CTS m17 : 40|24@1+ (1,0) [0|16777200] ""  InstrumentCluster_Ch2
 SG_ PGN_PktMsgTPCM_RTS m16 : 40|24@1+ (1,0) [0|16777200] ""  InstrumentCluster_Ch2
 SG_ PGN_PktMsgTPCM_RTS2 m19 : 40|24@1+ (1,0) [0|16777200] ""  InstrumentCluster_Ch2
 SG_ TotMsgSizeBAM m32 : 8|16@1+ (1,0) [0|64255] "counts"  InstrumentCluster_Ch2
 SG_ TotMsgSizeEoMA m19 : 8|16@1+ (1,0) [0|64255] "counts"  InstrumentCluster_Ch2
 SG_ TotMsgSizeTPCM_RTS m16 : 8|16@1+ (1,0) [0|64255] "counts"  InstrumentCluster_Ch2
 SG_ TotNumPktBAM m32 : 24|8@1+ (1,0) [0|255] ""  InstrumentCluster_Ch2
 SG_ TotNumPktEoMA m19 : 24|8@1+ (1,0) [0|255] ""  InstrumentCluster_Ch2
 SG_ TotNumPktTPCM_RTS m16 : 24|8@1+ (1,0) [0|255] ""  InstrumentCluster_Ch2

CM_ BU_ Dummy_Node_Ch2 "Dummy_Node is not a real node connected to the Network. It's used to receive signals/messages not managed by other ECUs connected to CAN Bus";
CM_ BU_ GWAY_OnBoardDiagnosticUnit_Ch2 "Node inserted to forward Display messages from CAN1 to CAN2.";
CM_ BU_ GWAY_OffBoardDiagTool1_VB1_Ch2 "Node inserted to forward EST messages from CAN1 to CAN2.";
CM_ BU_ GWAY_Engine1_Ch2 "Node inserted to forward Engine messages from CAN1 to CAN2.";
CM_ BU_ GWAY_CabDisplay1_Ch2 "Node inserted to forward Display messages from CAN1 to CAN2.";
CM_ BO_ 3221225472 "This is a message for not used signals, created by Vector CANdb++ DBC OLE DB Provider.";
CM_ SG_ 3221225472 TrailerParkBrakeRequest "Switch signal which indicates drivers demand to activate the trailer park brake.";
CM_ SG_ 3221225472 SteeringBrakeDirection "Switch signal which indicates the direction for steering brake in case only one brake switch signal is used.";
CM_ SG_ 3221225472 SecondaryBrakeSwitch "Switch signal which indicates that the driver operated secondary brake / handbrake is being pressed. Brake demand for secondary brake function in eTCV.";
CM_ SG_ 3221225472 PGN_RQST_F9_4C "PGN superset list which is requested by Request message";
CM_ SG_ 3221225472 CalibrOpMode "A status signal indicating the current calibration status.";
CM_ SG_ 3221225472 CalibrVal "The calibration parameter against each calibration point.";
CM_ SG_ 3221225472 PrsSwSts "A status signal indicating the status of the temporary pressure switch fitted during the EHR on-board calibration process.";
CM_ SG_ 3221225472 CalibrPnt "A status signal indicating which spool calibration point currently under consideration.";
CM_ SG_ 3221225472 XPD_MsgCnt "The XPR message counter is to verify the signal path from the demanding device to the electronic trailer valve controller on electronic brake systems. every following message the counter is incremented by 1 (0 follows 15).";
CM_ SG_ 3221225472 XPD_MsgChksum "The 4 bit XPR msg chksum is calculated with first 7 data bytes, the 4 bit message counter and the bytes of the msg ID. For algorithm refer to SPN 3188 in Digital Annex
";
CM_ SG_ 3221225472 AuxEquipSupplyPrs "The pneumatic pressure in the auxiliary circuit.";
CM_ SG_ 3221225472 AirSuspnsnSupplyPrs "The pneumatic pressure in the circuit for the electronically controlled air suspension system.";
CM_ SG_ 3221225472 AirComprSts "Indicates whether the air compressor is actively compressing air.";
CM_ SG_ 3221225472 PwtCircAirSupplyPrs "Supply pressure to carry the pressure information for the powertrain circuit. This circuit typically would feed powertrain components such as throttles, gearbox actuators and aftertreatment actuators for EGR and SCR systems.";
CM_ SG_ 3221225472 EngIdleIncSw "Not used FFh.";
CM_ SG_ 3221225472 EngIdleDecrSw "Not used FFh.";
CM_ SG_ 3221225472 EngTestModeSw "Not used FFh.";
CM_ SG_ 3221225472 EngShutdnOverrideSw "Not used FFh.";
CM_ SG_ 3221225472 EHR_EvNumParamMux_F1 "A status signal indicating the EHR valve number. Used for front & rear EHR's.";
CM_ SG_ 3221225472 EHR_EvNumParamMux_F2 "A status signal indicating the EHR valve number. Used for front & rear EHR's.";
CM_ SG_ 3221225472 EHR_EvNumParamMux_F3 "A status signal indicating the EHR valve number. Used for front & rear EHR's.";
CM_ SG_ 3221225472 EHR_EvNumParamMux_F4 "A status signal indicating the EHR valve number. Used for front & rear EHR's.";
CM_ SG_ 3221225472 BrakeSw "Switch signal which indicates that the driver operated brake foot pedal is being pressed.  This brake foot pedal is ...";
CM_ SG_ 3221225472 CC_AccelSw "Switch signal of the cruise control activator which indicates that the activator is in the position “accelerate.” ...";
CM_ SG_ 3221225472 CC_Actv "Cruise control is switched on.  It is not ensured that the engine is controlled by cruise control, as in the case of a large ...";
CM_ SG_ 3221225472 MsgChksum_2 "The message checksum is used to verify the signal path from the transmitting device to the receiving device.";
CM_ SG_ 3221225472 CC_CoastDecelSw "Switch signal of the cruise control activator which indicates that the activator is in the position “coast (decelerate).” ...";
CM_ SG_ 3221225472 CC_EnaSw "Switch signal which indicates that it is possible to manage the cruise control function.";
CM_ SG_ 3221225472 CC_PauseSw "Switch signal which indicates the position of the Cruise Control Pause Switch used on Remote Cruise Control ...";
CM_ SG_ 3221225472 CC_ResumSw "Switch signal of the cruise control activator which indicates that the activator is in the position “resume.” ...";
CM_ SG_ 3221225472 CC_SetSpd "Value of set (chosen) velocity of velocity control system.";
CM_ SG_ 3221225472 CC_SetSw "Switch signal of the cruise control activator which indicates that the activator is in the position “set.” ...";
CM_ SG_ 3221225472 CC_Sts "This parameter is used to indicate the current state, or mode, of operation by the cruise control device.  This is a status ...";
CM_ SG_ 3221225472 CltchSw "Switch signal which indicates that the clutch pedal is being pressed. It is necessary for a safe drivetrain behavior that the ...";
CM_ SG_ 3221225472 N2SpdAxSw "Switch signal which indicates the current axle range.";
CM_ SG_ 3221225472 PBrakeRleasInhReq "Park Brake Release Inhibit Request signals the desire that an applied park brake remain applied and limit the ability of the ...";
CM_ SG_ 3221225472 PBrakeSw "Switch signal which indicates when the parking brake is set. In general the switch actuated by the operators park brake ...";
CM_ SG_ 3221225472 PTO_GovSts "This parameter is used to indicate the current state or mode of operation by the power takeoff (PTO) governor.  In lieu of ...";
CM_ BO_ 2565350026 "Acknowledgment Message";
CM_ SG_ 2565350026 GrpFunctValAck "Group Function of PGN being acknowledged. This field identifies for a device the specific group function of a PGN being acknowledged or declined.  This field is not used if the PGN being acknowledged or declined is not a group function PGN.";
CM_ SG_ 2565350026 GrpFunctValNAck "Group Function of PGN being acknowledged. This field identifies for a device the specific group function of a PGN being acknowledged or declined.  This field is not used if the PGN being acknowledged or declined is not a group function PGN.";
CM_ SG_ 2565350026 GrpFunctValNAckAd "Group Function of PGN being acknowledged. This field identifies for a device the specific group function of a PGN being acknowledged or declined.  This field is not used if the PGN being acknowledged or declined is not a group function PGN.";
CM_ SG_ 2565350026 GrpFunctValNAckBusy "Group Function of PGN being acknowledged. This field identifies for a device the specific group function of a PGN being acknowledged or declined.  This field is not used if the PGN being acknowledged or declined is not a group function PGN.";
CM_ SG_ 2565350026 PGN_Ack "PGN which is requested by Request2 message";
CM_ SG_ 2565350026 PGN_NAck "PGN which is requested by Request2 message";
CM_ SG_ 2565350026 PGN_NAckAd "PGN which is requested by Request2 message";
CM_ SG_ 2565350026 PGN_NAckBusy "PGN which is requested by Request2 message";
CM_ BO_ 2566835082 "Previously active diagnostic trouble codes";
CM_ SG_ 2566835082 AmbrWarnLmp "This lamp is used to relay trouble code information that is reporting a problem with the vehicle system but the vehicle need...";
CM_ SG_ 2566835082 DTC_01 "Diagnostic Trouble Code";
CM_ SG_ 2566835082 DTC_02 "Diagnostic Trouble Code";
CM_ SG_ 2566835082 DTC_03 "Diagnostic Trouble Code";
CM_ SG_ 2566835082 DTC_04 "Diagnostic Trouble Code";
CM_ SG_ 2566835082 FlashAmbrWarnLmpAWL "This parameter provides the capability to flash the AWL (SPN 3040).";
CM_ SG_ 2566835082 FlashMIL "This parameter provides the capability to flash the MIL (SPN 3038).";
CM_ SG_ 2566835082 FlashProtLmp "This parameter provides the capability to flash the engine protect lamp (SPN 3041).";
CM_ SG_ 2566835082 FlashRedStopLmpRSL "This parameter provides the capability to flash the RSL (SPN 3039).";
CM_ SG_ 2566835082 MIL "A lamp used to relay only emissions-related trouble code information.";
CM_ SG_ 2566835082 ProtLmp "This lamp is used to relay trouble code informatio that is reporting a problem with a vehicle system that is most...";
CM_ SG_ 2566835082 RedStopLmp "This lamp is used to relay trouble code information that is of a severe enought condition that it warrants stopping the vehicle.";
CM_ BO_ 2566838922 "Software Identification. 'On request'. Variable DLC for Joystick Steering Valve (Danfoss) 11 identification fields (see signals) separated by  '*'";
CM_ SG_ 2566838922 Appl_Id_Byte_24 "Software ID. Set to P826vxx or to P662vxx";
CM_ SG_ 2566838922 Appl_Id_Byte_25 "Software ID. Set to P826vxx or to P662vxx";
CM_ SG_ 2566838922 Appl_Id_Byte_26 "Software ID. Set to P826vxx or to P662vxx";
CM_ SG_ 2566838922 Appl_Id_Byte_27 "Software ID. Set to P826vxx or to P662vxx";
CM_ SG_ 2566838922 Appl_Id_Byte_28 "Software ID. Set to P826vxx or to P662vxx";
CM_ SG_ 2566838922 Appl_Id_Byte_29 "Software ID. Set to P826vxx or to P662vxx";
CM_ SG_ 2566838922 Appl_Id_Byte_30 "Software ID. Set to P826vxx or to P662vxx";
CM_ SG_ 2566838922 Appl_Id_Byte_31 "Software ID. Set to P826vxx or to P662vxx";
CM_ SG_ 2566838922 Appl_Id_Byte_32 "Software ID. Set to P826vxx or to P662vxx";
CM_ SG_ 2566838922 Appl_Id_Byte_33 "Software ID. Set to P826vxx or to P662vxx";
CM_ SG_ 2566838922 Appl_Id_Byte_34 "Software ID. Set to P826vxx or to P662vxx";
CM_ SG_ 2566838922 Appl_Id_Byte_35 "Software ID. Set to P826vxx or to P662vxx";
CM_ SG_ 2566838922 Appl_Id_Byte_36 "Software ID. Set to P826vxx or to P662vxx";
CM_ SG_ 2566838922 Appl_Id_Byte_37 "Software ID. Set to P826vxx or to P662vxx";
CM_ SG_ 2566838922 Appl_Id_Byte_38 "Software ID. Set to P826vxx or to P662vxx";
CM_ SG_ 2566838922 Appl_Id_Byte_39 "Software ID. Set to P826vxx or to P662vxx";
CM_ SG_ 2566838922 Appl_Id_Enum "Software ID.";
CM_ SG_ 2566838922 Bootloader_Id "Software ID.";
CM_ SG_ 2566838922 Bootloader_Id_Byte_01 "Software ID.";
CM_ SG_ 2566838922 Bootloader_Id_Byte_02 "Software ID.";
CM_ SG_ 2566838922 Bootloader_Id_Byte_03 "Software ID.";
CM_ SG_ 2566838922 Bootloader_Id_Byte_04 "Software ID.";
CM_ SG_ 2566838922 Bootloader_Id_Byte_05 "Software ID.";
CM_ SG_ 2566838922 Bootloader_Id_Byte_06 "Software ID.";
CM_ SG_ 2566838922 Bootloader_Id_Byte_07 "Software ID.";
CM_ SG_ 2566838922 Bootloader_Id_Byte_08 "Software ID.";
CM_ SG_ 2566838922 Bootloader_Id_Byte_09 "Software ID.";
CM_ SG_ 2566838922 Bootloader_Id_Byte_10 "Software ID.";
CM_ SG_ 2566838922 Bootloader_Id_Byte_11 "Software ID.";
CM_ SG_ 2566838922 Bootloader_Id_Byte_12 "Software ID.";
CM_ SG_ 2566838922 Bootloader_Id_Byte_13 "Software ID.";
CM_ SG_ 2566838922 Bootloader_Id_Byte_14 "Software ID.";
CM_ SG_ 2566838922 Bootloader_Id_Byte_15 "Software ID.";
CM_ SG_ 2566838922 Bootloader_Id_Byte_16 "Software ID.";
CM_ SG_ 2566838922 Bootloader_Id_Byte_17 "Software ID.";
CM_ SG_ 2566838922 Bootloader_Id_Byte_18 "Software ID.";
CM_ SG_ 2566838922 Bootloader_Id_Byte_19 "Software ID.";
CM_ SG_ 2566838922 Bootloader_Id_Byte_20 "Software ID.";
CM_ SG_ 2566838922 Bootloader_Id_Byte_21 "Software ID.";
CM_ SG_ 2566838922 Bootloader_Id_Byte_22 "Software ID.";
CM_ SG_ 2566838922 Bootloader_Id_Byte_23 "Software ID.";
CM_ SG_ 2566838922 Bootloader_Id_Byte_24 "Software ID.";
CM_ SG_ 2566838922 Bootloader_Id_Byte_25 "Software ID.";
CM_ SG_ 2566838922 Bootloader_Id_Byte_26 "Software ID.";
CM_ SG_ 2566838922 Bootloader_Id_Byte_27 "Software ID.";
CM_ SG_ 2566838922 Bootloader_Id_Byte_28 "Software ID.";
CM_ SG_ 2566838922 Bootloader_Id_Byte_29 "Software ID.";
CM_ SG_ 2566838922 Bootloader_Id_Byte_30 "Software ID.";
CM_ SG_ 2566838922 Bootloader_Id_Byte_31 "Software ID.";
CM_ SG_ 2566838922 Bootloader_Id_Byte_32 "Software ID.";
CM_ SG_ 2566838922 Bootloader_Id_Byte_33 "Software ID.";
CM_ SG_ 2566838922 Bootloader_Id_Byte_34 "Software ID.";
CM_ SG_ 2566838922 Bootloader_Id_Byte_35 "Software ID.";
CM_ SG_ 2566838922 Bootloader_Id_Byte_36 "Software ID.";
CM_ SG_ 2566838922 Bootloader_Id_Byte_37 "Software ID.";
CM_ SG_ 2566838922 Bootloader_Id_Byte_38 "Software ID.";
CM_ SG_ 2566838922 Bootloader_Id_Byte_39 "Software ID.";
CM_ SG_ 2566838922 Bootloader_Id_Enum "Software ID.";
CM_ SG_ 2566838922 EndStrng_00 "Software ID. ";
CM_ SG_ 2566838922 EndStrng_01 "Software ID. ";
CM_ SG_ 2566838922 NumSW_IdField "Number of software identification designators represented in the software identification parameter group.";
CM_ SG_ 2566838922 Appl_Id "Software ID. Set to P826vxx or to P662vxx";
CM_ SG_ 2566838922 Appl_Id_Byte_01 "Software ID. Set to P826vxx or to P662vxx";
CM_ SG_ 2566838922 Appl_Id_Byte_02 "Software ID. Set to P826vxx or to P662vxx";
CM_ SG_ 2566838922 Appl_Id_Byte_03 "Software ID. Set to P826vxx or to P662vxx";
CM_ SG_ 2566838922 Appl_Id_Byte_04 "Software ID. Set to P826vxx or to P662vxx";
CM_ SG_ 2566838922 Appl_Id_Byte_05 "Software ID. Set to P826vxx or to P662vxx";
CM_ SG_ 2566838922 Appl_Id_Byte_06 "Software ID. Set to P826vxx or to P662vxx";
CM_ SG_ 2566838922 Appl_Id_Byte_07 "Software ID. Set to P826vxx or to P662vxx";
CM_ SG_ 2566838922 Appl_Id_Byte_08 "Software ID. Set to P826vxx or to P662vxx";
CM_ SG_ 2566838922 Appl_Id_Byte_09 "Software ID. Set to P826vxx or to P662vxx";
CM_ SG_ 2566838922 Appl_Id_Byte_10 "Software ID. Set to P826vxx or to P662vxx";
CM_ SG_ 2566838922 Appl_Id_Byte_11 "Software ID. Set to P826vxx or to P662vxx";
CM_ SG_ 2566838922 Appl_Id_Byte_12 "Software ID. Set to P826vxx or to P662vxx";
CM_ SG_ 2566838922 Appl_Id_Byte_13 "Software ID. Set to P826vxx or to P662vxx";
CM_ SG_ 2566838922 Appl_Id_Byte_14 "Software ID. Set to P826vxx or to P662vxx";
CM_ SG_ 2566838922 Appl_Id_Byte_15 "Software ID. Set to P826vxx or to P662vxx";
CM_ SG_ 2566838922 Appl_Id_Byte_16 "Software ID. Set to P826vxx or to P662vxx";
CM_ SG_ 2566838922 Appl_Id_Byte_17 "Software ID. Set to P826vxx or to P662vxx";
CM_ SG_ 2566838922 Appl_Id_Byte_18 "Software ID. Set to P826vxx or to P662vxx";
CM_ SG_ 2566838922 Appl_Id_Byte_19 "Software ID. Set to P826vxx or to P662vxx";
CM_ SG_ 2566838922 Appl_Id_Byte_20 "Software ID. Set to P826vxx or to P662vxx";
CM_ SG_ 2566838922 Appl_Id_Byte_21 "Software ID. Set to P826vxx or to P662vxx";
CM_ SG_ 2566838922 Appl_Id_Byte_22 "Software ID. Set to P826vxx or to P662vxx";
CM_ SG_ 2566838922 Appl_Id_Byte_23 "Software ID. Set to P826vxx or to P662vxx";
CM_ SG_ 2566854794 MsgCnt_EHR "Initial Value 12. Counts from 0 to 11 and then back to 0. 12, 13 are reserved, 14 error, 15 NA. Tecnord EHR Only";
CM_ SG_ 2566854794 SpoolPosition "Spool position of the valve (only for Technord EHR).";
CM_ BO_ 2566866058 "The message is used 'On event' to configure the valves. Every byte not used, to be set 0xFF.";
CM_ SG_ 2566866058 EHR_EvNumParamMux_12 "A status signal indicating the EHR valve number. Used for front & rear EHR's.";
CM_ SG_ 2566866058 EHR_ParamStsByte_2 "The signal has a fix value 0x3B";
CM_ SG_ 2566866058 EHR_RmpRndng "A status signal indicating the EHR valve number. Used for front & rear EHR's.";
CM_ SG_ 2566866058 EHR_ChksumSW "Calculated checksum of the application software.";
CM_ BO_ 2566865546 "During engine cranking, all diagnostics checks shall be disabled to avoid reporting of spurious error. Engine cranking is indicated by ‘init’ parameter in Ehr Control message.";
CM_ SG_ 2566865546 EHR_Err "A status signal indicating the EHR fault condition. Sent by both front & rear EHR's.";
CM_ SG_ 2566865546 EHR_ErrCod "A status value to indicate the EHR fault code. Used for front & rear EHR's.";
CM_ SG_ 2566865546 EHR_EvTemp "A measured value to indicate the EHR valve temperature. Used for front & rear EHR's.";
CM_ SG_ 2566865546 EHR_InitDiag "A status signal indicating the EHR fault condition. Sent by both front & rear EHR's.";
CM_ SG_ 2566865546 EHR_SysId "NOT USED";
CM_ BO_ 2564487562 "Reserved for ISO 15765";
CM_ SG_ 2564487562 ProtocCntrlInfo "Part of Network Protocol Control Information (N_PCI) of a ISO 15765 message.";
CM_ BO_ 2566843274 "NOTE - The make, model, serial number and unit number fields in this message are optional and separated by an ASCII 
“*”.  It is not necessary to include all fields; however, the delimiter (“*”) is always required.";
CM_ SG_ 2566843274 UnitNumPwrUnit "Owner assigned unit number for the power unit of the vehicle.";
CM_ SG_ 2566843274 SN_2_Byte_15 "Serial number of the component.";
CM_ SG_ 2566843274 SN_2_Byte_14 "Serial number of the component.";
CM_ SG_ 2566843274 SN_2_Byte_13 "Serial number of the component.";
CM_ SG_ 2566843274 SN_2_Byte_12 "Serial number of the component.";
CM_ SG_ 2566843274 SN_2_Byte_11 "Serial number of the component.";
CM_ SG_ 2566843274 SN_2_Byte_10 "Serial number of the component.";
CM_ SG_ 2566843274 SN_2_Byte_09 "Serial number of the component.";
CM_ SG_ 2566843274 SN_2_Byte_08 "Serial number of the component.";
CM_ SG_ 2566843274 SN_2_Byte_07 "Serial number of the component.";
CM_ SG_ 2566843274 SN_2_Byte_06 "Serial number of the component.";
CM_ SG_ 2566843274 SN_2_Byte_05 "Serial number of the component.";
CM_ SG_ 2566843274 SN_2_Byte_04 "Serial number of the component.";
CM_ SG_ 2566843274 SN_2_Byte_03 "Serial number of the component.";
CM_ SG_ 2566843274 SN_2_Byte_02 "Serial number of the component.";
CM_ SG_ 2566843274 SN_2_Byte_01 "Serial number of the component.";
CM_ SG_ 2566843274 SN_2 "Serial number of the component.";
CM_ SG_ 2566843274 Mdl_Byte_08 "Model of the component.";
CM_ SG_ 2566843274 Mdl_Byte_07 "Model of the component.";
CM_ SG_ 2566843274 Mdl_Byte_06 "Model of the component.";
CM_ SG_ 2566843274 Mdl_Byte_05 "Model of the component.";
CM_ SG_ 2566843274 Mdl_Byte_04 "Model of the component.";
CM_ SG_ 2566843274 Mdl_Byte_03 "Model of the component.";
CM_ SG_ 2566843274 Mdl_Byte_02 "Model of the component.";
CM_ SG_ 2566843274 Mdl_Byte_01 "Model of the component.";
CM_ SG_ 2566843274 Make "Owner assigned unit number for the power unit of the vehicle.";
CM_ SG_ 2566843274 Mdl "Model of the component.";
CM_ BO_ 2565799818 "Address Claimed";
CM_ SG_ 2565799818 Rsrvd_1Bit "Set to 0 for J1939-81";
CM_ SG_ 2566871586 MsgCnt_EHR "Initial Value 12. Counts from 0 to 11 and then back to 0. 12, 13 are reserved, 14 error, 15 NA. Tecnord EHR Only";
CM_ SG_ 2566871586 EHR_FailSafe "The aim of this function is if an internal fault is detected by the valve, then the valve will default to either neutral or float depending on failsave mode set in the Ehr control message.";
CM_ SG_ 2566871586 EHR_EvTemp "A measured value to indicate the EHR valve temperature. Used for front & rear EHR's.";
CM_ SG_ 2566871586 EHR_DynRmpTime "By using time ramps, the dynamics of the valve can be reduced in a well-targeted manner. The time ramp is the time required until the full stroke has been completed (from 0 to 100 % or from 100 to 0 % raising or lowering).";
CM_ SG_ 2566871586 EHR_CrvShp "The characteristic-curve shape allows changes from linear to highly progressive. The fine metering properties of the valve can also be altered in this way, if necessary.";
CM_ SG_ 2566871586 EHR_CrvGrad "The characteristic-curve shape allows changes from linear to highly progressive. The fine metering properties of the valve can also be altered in this way, if necessary.";
CM_ BO_ 2566843265 "NOTE - The make, model, serial number and unit number fields in this message are optional and separated by an ASCII 
“*”.  It is not necessary to include all fields; however, the delimiter (“*”) is always required.";
CM_ SG_ 2566843265 UnitNumPwrUnit "Owner assigned unit number for the power unit of the vehicle.";
CM_ SG_ 2566843265 SN_2_Byte_15 "Serial number of the component.";
CM_ SG_ 2566843265 SN_2_Byte_14 "Serial number of the component.";
CM_ SG_ 2566843265 SN_2_Byte_13 "Serial number of the component.";
CM_ SG_ 2566843265 SN_2_Byte_12 "Serial number of the component.";
CM_ SG_ 2566843265 SN_2_Byte_11 "Serial number of the component.";
CM_ SG_ 2566843265 SN_2_Byte_10 "Serial number of the component.";
CM_ SG_ 2566843265 SN_2_Byte_09 "Serial number of the component.";
CM_ SG_ 2566843265 SN_2_Byte_08 "Serial number of the component.";
CM_ SG_ 2566843265 SN_2_Byte_07 "Serial number of the component.";
CM_ SG_ 2566843265 SN_2_Byte_06 "Serial number of the component.";
CM_ SG_ 2566843265 SN_2_Byte_05 "Serial number of the component.";
CM_ SG_ 2566843265 SN_2_Byte_04 "Serial number of the component.";
CM_ SG_ 2566843265 SN_2_Byte_03 "Serial number of the component.";
CM_ SG_ 2566843265 SN_2_Byte_02 "Serial number of the component.";
CM_ SG_ 2566843265 SN_2_Byte_01 "Serial number of the component.";
CM_ SG_ 2566843265 SN_2 "Serial number of the component.";
CM_ SG_ 2566843265 Mdl_Byte_08 "Model of the component.";
CM_ SG_ 2566843265 Mdl_Byte_07 "Model of the component.";
CM_ SG_ 2566843265 Mdl_Byte_06 "Model of the component.";
CM_ SG_ 2566843265 Mdl_Byte_05 "Model of the component.";
CM_ SG_ 2566843265 Mdl_Byte_04 "Model of the component.";
CM_ SG_ 2566843265 Mdl_Byte_03 "Model of the component.";
CM_ SG_ 2566843265 Mdl_Byte_02 "Model of the component.";
CM_ SG_ 2566843265 Mdl_Byte_01 "Model of the component.";
CM_ SG_ 2566843265 Make "Owner assigned unit number for the power unit of the vehicle.";
CM_ SG_ 2566843265 Mdl "Model of the component.";
CM_ BO_ 2564487553 "Reserved for ISO 15765";
CM_ SG_ 2564487553 ProtocCntrlInfo "Part of Network Protocol Control Information (N_PCI) of a ISO 15765 message.";
CM_ BO_ 2632777721 "Transport Protocol - Connection Management";
CM_ SG_ 2632777721 TotMsgSizeTPCM_RTS "Total message size (in bytes) for BAM message.Total message size (in bytes) for RTS/CTS message.Total message size (in bytes) for RTS/CTS message.";
CM_ SG_ 2632777721 TotNumPktTPCM_RTS "Total number of packets for BAM message.Total number of packets received for RTS/CTS message.Total number of packets for RTS/CTS message.";
CM_ SG_ 2632777721 MaxNumPktTPCM_RTS "Maximum number of packets for RTS/CTS message.";
CM_ SG_ 2632777721 NumPktSentTPCM_CTS "Number of Packets that can be sent (TP.CM_CTS)";
CM_ SG_ 2632777721 NxtPktNumSentTPCM_CTS "Next Packet Number to be sent (TP.CM_CTS)";
CM_ SG_ 2632777721 ConnAbrtReason "Reason for connection abort message.";
CM_ SG_ 2632777721 TotNumPktBAM "Total number of packets for BAM message.Total number of packets received for RTS/CTS message.Total number of packets for RTS/CTS message.";
CM_ SG_ 2632777721 TotMsgSizeBAM "Total message size (in bytes) for BAM message.Total message size (in bytes) for RTS/CTS message.Total message size (in bytes) for RTS/CTS message.";
CM_ SG_ 2632777721 TotMsgSizeEoMA "Total message size (in bytes) for BAM message.Total message size (in bytes) for RTS/CTS message.Total message size (in bytes) for RTS/CTS message.";
CM_ SG_ 2632777721 TotNumPktEoMA "Total number of packets for BAM message.Total number of packets received for RTS/CTS message.Total number of packets for RTS/CTS message.";
CM_ BO_ 2566838521 "Commanded Address";
CM_ SG_ 2566838521 NameCmdAddrTarg "NAME used to identify Controller Application  in a Commanded Address Message to associate the Controller application with an address.";
CM_ SG_ 2566838521 AddrAssignNewSA "The source address that is to be assigned to the CA that has the NAME corresponding to the one conveyed in the first eight bytes of this Commanded Address message.";
CM_ BO_ 2564456697 "Reserved for ISO 15765";
CM_ SG_ 2564456697 ProtocCntrlInfo "Part of Network Protocol Control Information (N_PCI) of a ISO 15765 message.";
CM_ BO_ 2566843264 "NOTE - The make, model, serial number and unit number fields in this message are optional and separated by an ASCII 
“*”.  It is not necessary to include all fields; however, the delimiter (“*”) is always required.";
CM_ SG_ 2566843264 UnitNumPwrUnit "Owner assigned unit number for the power unit of the vehicle.";
CM_ SG_ 2566843264 SN_2_Byte_15 "Serial number of the component.";
CM_ SG_ 2566843264 SN_2_Byte_14 "Serial number of the component.";
CM_ SG_ 2566843264 SN_2_Byte_13 "Serial number of the component.";
CM_ SG_ 2566843264 SN_2_Byte_12 "Serial number of the component.";
CM_ SG_ 2566843264 SN_2_Byte_11 "Serial number of the component.";
CM_ SG_ 2566843264 SN_2_Byte_10 "Serial number of the component.";
CM_ SG_ 2566843264 SN_2_Byte_09 "Serial number of the component.";
CM_ SG_ 2566843264 SN_2_Byte_08 "Serial number of the component.";
CM_ SG_ 2566843264 SN_2_Byte_07 "Serial number of the component.";
CM_ SG_ 2566843264 SN_2_Byte_06 "Serial number of the component.";
CM_ SG_ 2566843264 SN_2_Byte_05 "Serial number of the component.";
CM_ SG_ 2566843264 SN_2_Byte_04 "Serial number of the component.";
CM_ SG_ 2566843264 SN_2_Byte_03 "Serial number of the component.";
CM_ SG_ 2566843264 SN_2_Byte_02 "Serial number of the component.";
CM_ SG_ 2566843264 Mdl_Byte_08 "Model of the component.";
CM_ SG_ 2566843264 Mdl_Byte_07 "Model of the component.";
CM_ SG_ 2566843264 Mdl_Byte_06 "Model of the component.";
CM_ SG_ 2566843264 Mdl_Byte_05 "Model of the component.";
CM_ SG_ 2566843264 Mdl_Byte_04 "Model of the component.";
CM_ SG_ 2566843264 Mdl_Byte_03 "Model of the component.";
CM_ SG_ 2566843264 Mdl_Byte_02 "Model of the component.";
CM_ SG_ 2566843264 Mdl_Byte_01 "Model of the component.";
CM_ SG_ 2566843264 SN_2_Byte_01 "Serial number of the component.";
CM_ SG_ 2566843264 SN_2 "Serial number of the component.";
CM_ SG_ 2566843264 Make "Owner assigned unit number for the power unit of the vehicle.";
CM_ SG_ 2566843264 Mdl "Model of the component.";
CM_ BO_ 2564487552 "Reserved for ISO 15765";
CM_ SG_ 2564487552 ProtocCntrlInfo "Part of Network Protocol Control Information (N_PCI) of a ISO 15765 message.";
CM_ BO_ 2560825102 "This message shall provide the applicable lamp for each individual DTC";
CM_ SG_ 2560825102 DTC_01 "Diagnostic Trouble Code";
CM_ SG_ 2560825102 DTCxAmbrWarnLmpSupp_andSts "Lamp support status";
CM_ SG_ 2560825102 DTCxFlashAmbrWarnLmpSupp_andSts "Lamp support status. Not evaluated by ECM.";
CM_ SG_ 2560825102 DTCxFlashMIL_Supp_andSts "Lamp support status. Not evaluated by ECM.";
CM_ SG_ 2560825102 DTCxFlashProtLmpSupp_andSts "Lamp support status. Not evaluated by ECM.";
CM_ SG_ 2560825102 DTCxFlashRedStopLmpSupp_andSts "Lamp support status. Not evaluated by ECM.";
CM_ SG_ 2560825102 DTCxMIL_Supp_andSts "Lamp support status";
CM_ SG_ 2560825102 DTCxProtLmpSupp_andSts "Lamp support status";
CM_ SG_ 2560825102 DTCxRedStopLmpSupp_andSts "Lamp support status";
CM_ BO_ 2632712073 "Transport Protocol - Data Transfer";
CM_ SG_ 2632712073 PktDataTPDT "Relevant data for this PGNs unique use.";
CM_ BO_ 2632712074 "Transport Protocol - Data Transfer";
CM_ SG_ 2632712074 PktDataTPDT "Relevant data for this PGNs unique use.";
CM_ BO_ 2632777609 "Transport Protocol - Connection Management";
CM_ SG_ 2632777609 ConnAbrtReason "Reason for connection abort message.";
CM_ SG_ 2632777609 MaxNumPktTPCM_RTS "Maximum number of packets for RTS/CTS message.";
CM_ SG_ 2632777609 NumPktSentTPCM_CTS "Number of Packets that can be sent (TP.CM_CTS)";
CM_ SG_ 2632777609 NxtPktNumSentTPCM_CTS "Next Packet Number to be sent (TP.CM_CTS)";
CM_ SG_ 2632777609 TotMsgSizeBAM "Total message size (in bytes) for BAM message.Total message size (in bytes) for RTS/CTS message.Total message size (in bytes) for RTS/CTS message.";
CM_ SG_ 2632777609 TotMsgSizeEoMA "Total message size (in bytes) for BAM message.Total message size (in bytes) for RTS/CTS message.Total message size (in bytes) for RTS/CTS message.";
CM_ SG_ 2632777609 TotMsgSizeTPCM_RTS "Total message size (in bytes) for BAM message.Total message size (in bytes) for RTS/CTS message.Total message size (in bytes) for RTS/CTS message.";
CM_ SG_ 2632777609 TotNumPktBAM "Total number of packets for BAM message.Total number of packets received for RTS/CTS message.Total number of packets for RTS/CTS message.";
CM_ SG_ 2632777609 TotNumPktEoMA "Total number of packets for BAM message.Total number of packets received for RTS/CTS message.Total number of packets for RTS/CTS message.";
CM_ SG_ 2632777609 TotNumPktTPCM_RTS "Total number of packets for BAM message.Total number of packets received for RTS/CTS message.Total number of packets for RTS/CTS message.";
BA_DEF_ SG_  "GenSigReceiveSetting" STRING ;
BA_DEF_ SG_  "GenSigPreSetting" STRING ;
BA_DEF_ SG_  "GenSigPreIfSetting" STRING ;
BA_DEF_ SG_  "GenSigPostSetting" STRING ;
BA_DEF_ SG_  "GenSigPostIfSetting" STRING ;
BA_DEF_ SG_  "GenSigEnvVarType" ENUM  "int","float","undef";
BA_DEF_ SG_  "GenSigConditionalSend" STRING ;
BA_DEF_ SG_  "GenSigAutoGenSnd" ENUM  "No","Yes";
BA_DEF_ SG_  "GenSigAutoGenDsp" ENUM  "No","Yes";
BA_DEF_ SG_  "GenSigAssignSetting" STRING ;
BA_DEF_ SG_  "GenSigAltSetting" STRING ;
BA_DEF_ SG_  "SPN_Definition" STRING ;
BA_DEF_ SG_  "External_Reference_decod" STRING ;
BA_DEF_ SG_  "UtilizationOnNetwork" ENUM  "Used","NOT USED";
BA_DEF_ SG_  "CI_RepetitionNum" ENUM  "1","2";
BA_DEF_ SG_  "CI_RepetitionType" ENUM  "NA","1","2","3","4";
BA_DEF_ SG_  "CI_RepetitionComplemented" ENUM  "0","1","vector_leerstring";
BA_DEF_ SG_  "DDI" INT 0 65535;
BA_DEF_ SG_  "CI_FullName" STRING ;
BA_DEF_ SG_  "GenSigTimeoutTime" INT 0 3600000;
BA_DEF_ SG_  "CI_ParId" STRING ;
BA_DEF_ SG_  "CI_SLOT_Name" STRING ;
BA_DEF_ SG_  "CI_ParVersion" STRING ;
BA_DEF_ SG_  "GenSigSendType" ENUM  "Cyclic","OnWrite","OnWriteWithRepetition","OnChange","OnChangeWithRepetition","IfActive","IfActiveWithRepetition","NoSigSendType";
BA_DEF_ SG_  "GenSigInactiveValue" INT 0 2147483647;
BA_DEF_ SG_  "GenSigStartValue" INT 0 2147483647;
BA_DEF_ SG_  "GenSigEVName" STRING ;
BA_DEF_ SG_  "SPN" INT 0 524287;
BA_DEF_ SG_  "SigType" ENUM  "Default","Range","RangeSigned","ASCII","Discrete","Control","ReferencePGN","DTC","StringDelimiter","StringLength","StringLengthControl";
BA_DEF_ SG_  "GenSigILSupport" ENUM  "Yes","No";
BA_DEF_ BO_  "ShowSignals" INT -1 0;
BA_DEF_ BO_  "GroupSignals" INT 1 100;
BA_DEF_ BO_  "PGN_Definition" STRING ;
BA_DEF_ BO_  "External_Reference" STRING ;
BA_DEF_ BO_  "SingleFrame" INT 0 1;
BA_DEF_ BO_  "CI_AllowedLostMessages" ENUM  "NA","0","1","2","3","4";
BA_DEF_ BO_  "CI_AliveTimeout" INT 0 3600000;
BA_DEF_ BO_  "TpJ1939VarDlc" ENUM  "No","Yes";
BA_DEF_ BO_  "CI_ShowSignals" INT -1 0;
BA_DEF_ BO_  "CI_PgVersion" STRING ;
BA_DEF_ BO_  "CI_GroupSignals" INT 1 100;
BA_DEF_ BO_  "DiagUUDTResponse" ENUM  "No","Yes";
BA_DEF_ BO_  "DiagState" ENUM  "No","Yes";
BA_DEF_ BO_  "DiagResponse" ENUM  "No","Yes";
BA_DEF_ BO_  "DiagRequest" ENUM  "No","Yes";
BA_DEF_ BO_  "DiagConnection" INT 0 65535;
BA_DEF_ BO_  "GenMsgNrOfRepetition" INT 0 1000000;
BA_DEF_ BO_  "GenMsgILSupport" ENUM  "No","Yes";
BA_DEF_ BO_  "GenMsgFastOnStart" INT 0 100000;
BA_DEF_ BO_  "GenMsgCycleTimeFast" INT 0 3600000;
BA_DEF_ BO_  "GenMsgStartDelayTime" INT 0 100000;
BA_DEF_ BO_  "GenMsgDelayTime" INT 0 3600000;
BA_DEF_ BO_  "VFrameFormat" ENUM  "StandardCAN","ExtendedCAN","reserved","J1939PG";
BA_DEF_ BO_  "GenMsgCycleTime" INT 0 3600000;
BA_DEF_ BO_  "GenMsgRequestable" INT 0 1;
BA_DEF_ BO_  "GenMsgSendType" ENUM  "cyclic","reserved","cyclicIfActive","reserved","reserved","reserved","reserved","reserved","noMsgSendType";
BA_DEF_ BU_  "Identity_Number_Type" ENUM  "Static","Dynamic";
BA_DEF_ BU_  "ILUsed" ENUM  "No","Yes";
BA_DEF_ BU_  "CI_Identity_Number_Type" ENUM  "Static","Dynamic";
BA_DEF_ BU_  "NmStationAddress" INT 0 255;
BA_DEF_ BU_  "NmJ1939AAC" INT 0 1;
BA_DEF_ BU_  "NmJ1939ECUInstance" INT 0 7;
BA_DEF_ BU_  "NmJ1939Function" INT 0 255;
BA_DEF_ BU_  "NmJ1939FunctionInstance" INT 0 31;
BA_DEF_ BU_  "NmJ1939IndustryGroup" INT 0 7;
BA_DEF_ BU_  "NmJ1939ManufacturerCode" INT 0 2047;
BA_DEF_ BU_  "NmJ1939System" INT 0 127;
BA_DEF_ BU_  "NmJ1939SystemInstance" INT 0 15;
BA_DEF_ BU_  "ECU" STRING ;
BA_DEF_ BU_  "NodeLayerModules" STRING ;
BA_DEF_ BU_  "NodeOnNetworkConfiguration" ENUM  "Base","Optional";
BA_DEF_  "GenEnvVarPrefix" STRING ;
BA_DEF_  "GenEnvVarEndingSnd" STRING ;
BA_DEF_  "GenEnvVarEndingDsp" STRING ;
BA_DEF_  "NMEA2000_SpecVersion" STRING ;
BA_DEF_  "Baudrate" INT 0 1000000;
BA_DEF_  "DatabaseVersion" STRING ;
BA_DEF_  "ProtocolType" STRING ;
BA_DEF_  "BusType" STRING ;
BA_DEF_  "DBName" STRING ;
BA_DEF_DEF_  "GenSigReceiveSetting" "";
BA_DEF_DEF_  "GenSigPreSetting" "";
BA_DEF_DEF_  "GenSigPreIfSetting" "";
BA_DEF_DEF_  "GenSigPostSetting" "";
BA_DEF_DEF_  "GenSigPostIfSetting" "";
BA_DEF_DEF_  "GenSigEnvVarType" "undef";
BA_DEF_DEF_  "GenSigConditionalSend" "";
BA_DEF_DEF_  "GenSigAutoGenSnd" "";
BA_DEF_DEF_  "GenSigAutoGenDsp" "";
BA_DEF_DEF_  "GenSigAssignSetting" "";
BA_DEF_DEF_  "GenSigAltSetting" "";
BA_DEF_DEF_  "SPN_Definition" "";
BA_DEF_DEF_  "External_Reference_decod" "";
BA_DEF_DEF_  "UtilizationOnNetwork" "Used";
BA_DEF_DEF_  "CI_RepetitionNum" "1";
BA_DEF_DEF_  "CI_RepetitionType" "NA";
BA_DEF_DEF_  "CI_RepetitionComplemented" "0";
BA_DEF_DEF_  "DDI" 0;
BA_DEF_DEF_  "CI_FullName" "";
BA_DEF_DEF_  "GenSigTimeoutTime" 0;
BA_DEF_DEF_  "CI_ParId" "";
BA_DEF_DEF_  "CI_SLOT_Name" "0";
BA_DEF_DEF_  "CI_ParVersion" "0";
BA_DEF_DEF_  "GenSigSendType" "NoSigSendType";
BA_DEF_DEF_  "GenSigInactiveValue" 0;
BA_DEF_DEF_  "GenSigStartValue" 0;
BA_DEF_DEF_  "GenSigEVName" "Env@Nodename_@Signame";
BA_DEF_DEF_  "SPN" 0;
BA_DEF_DEF_  "SigType" "Default";
BA_DEF_DEF_  "GenSigILSupport" "Yes";
BA_DEF_DEF_  "ShowSignals" -1;
BA_DEF_DEF_  "GroupSignals" 1;
BA_DEF_DEF_  "PGN_Definition" "N/A";
BA_DEF_DEF_  "External_Reference" "";
BA_DEF_DEF_  "SingleFrame" 1;
BA_DEF_DEF_  "CI_AllowedLostMessages" "NA";
BA_DEF_DEF_  "CI_AliveTimeout" 0;
BA_DEF_DEF_  "TpJ1939VarDlc" "No";
BA_DEF_DEF_  "CI_ShowSignals" -1;
BA_DEF_DEF_  "CI_PgVersion" "0";
BA_DEF_DEF_  "CI_GroupSignals" 1;
BA_DEF_DEF_  "DiagUUDTResponse" "No";
BA_DEF_DEF_  "DiagState" "No";
BA_DEF_DEF_  "DiagResponse" "No";
BA_DEF_DEF_  "DiagRequest" "No";
BA_DEF_DEF_  "DiagConnection" 0;
BA_DEF_DEF_  "GenMsgNrOfRepetition" 0;
BA_DEF_DEF_  "GenMsgILSupport" "Yes";
BA_DEF_DEF_  "GenMsgFastOnStart" 0;
BA_DEF_DEF_  "GenMsgCycleTimeFast" 0;
BA_DEF_DEF_  "GenMsgStartDelayTime" 0;
BA_DEF_DEF_  "GenMsgDelayTime" 1;
BA_DEF_DEF_  "VFrameFormat" "J1939PG";
BA_DEF_DEF_  "GenMsgCycleTime" 0;
BA_DEF_DEF_  "GenMsgRequestable" 0;
BA_DEF_DEF_  "GenMsgSendType" "noMsgSendType";
BA_DEF_DEF_  "Identity_Number_Type" "Static";
BA_DEF_DEF_  "ILUsed" "Yes";
BA_DEF_DEF_  "CI_Identity_Number_Type" "Static";
BA_DEF_DEF_  "NmStationAddress" 254;
BA_DEF_DEF_  "NmJ1939AAC" 0;
BA_DEF_DEF_  "NmJ1939ECUInstance" 0;
BA_DEF_DEF_  "NmJ1939Function" 0;
BA_DEF_DEF_  "NmJ1939FunctionInstance" 0;
BA_DEF_DEF_  "NmJ1939IndustryGroup" 0;
BA_DEF_DEF_  "NmJ1939ManufacturerCode" 0;
BA_DEF_DEF_  "NmJ1939System" 0;
BA_DEF_DEF_  "NmJ1939SystemInstance" 0;
BA_DEF_DEF_  "ECU" "";
BA_DEF_DEF_  "NodeLayerModules" "J1939_IL.dll";
BA_DEF_DEF_  "NodeOnNetworkConfiguration" "Base";
BA_DEF_DEF_  "GenEnvVarPrefix" "Env";
BA_DEF_DEF_  "GenEnvVarEndingSnd" "_";
BA_DEF_DEF_  "GenEnvVarEndingDsp" "Dsp_";
BA_DEF_DEF_  "NMEA2000_SpecVersion" "-";
BA_DEF_DEF_  "Baudrate" 0;
BA_DEF_DEF_  "DatabaseVersion" "";
BA_DEF_DEF_  "ProtocolType" "J1939";
BA_DEF_DEF_  "BusType" "CAN";
BA_DEF_DEF_  "DBName" "";
BA_ "Baudrate" 500000;
BA_ "DatabaseVersion" "C7";
BA_ "DBName" "VB2";
BA_ "NmStationAddress" BU_ EHR_Spare 143;
BA_ "ECU" BU_ EHR_Spare "EHR_Spare";
BA_ "NodeLayerModules" BU_ EHR_Spare "J1939_IL";
BA_ "NmStationAddress" BU_ FEHR_3 139;
BA_ "NmJ1939Function" BU_ FEHR_3 25;
BA_ "NmJ1939FunctionInstance" BU_ FEHR_3 12;
BA_ "NmJ1939ManufacturerCode" BU_ FEHR_3 51;
BA_ "NmJ1939System" BU_ FEHR_3 13;
BA_ "ECU" BU_ FEHR_3 "FEHR_3";
BA_ "NodeLayerModules" BU_ FEHR_3 "J1939_IL";
BA_ "NmStationAddress" BU_ PTO_SpeedSelector 189;
BA_ "ECU" BU_ PTO_SpeedSelector "PTO_SpeedSelector";
BA_ "NodeLayerModules" BU_ PTO_SpeedSelector "J1939_IL";
BA_ "NmStationAddress" BU_ Dummy_Node_Ch2 247;
BA_ "ECU" BU_ Dummy_Node_Ch2 "Dummy_ECU";
BA_ "NodeLayerModules" BU_ Dummy_Node_Ch2 "J1939_IL";
BA_ "NmStationAddress" BU_ FEHR_2 138;
BA_ "ECU" BU_ FEHR_2 "FEHR_2";
BA_ "NodeLayerModules" BU_ FEHR_2 "J1939_IL";
BA_ "NmStationAddress" BU_ TrailerBrake 14;
BA_ "NmJ1939Function" BU_ TrailerBrake 255;
BA_ "NmJ1939ManufacturerCode" BU_ TrailerBrake 62;
BA_ "ECU" BU_ TrailerBrake "iTVB2.0";
BA_ "NodeLayerModules" BU_ TrailerBrake "J1939_IL";
BA_ "NmStationAddress" BU_ OffBoardDiagnosticTool1_Ch2 249;
BA_ "ECU" BU_ OffBoardDiagnosticTool1_Ch2 "EST";
BA_ "NodeLayerModules" BU_ OffBoardDiagnosticTool1_Ch2 "J1939_IL";
BA_ "NmStationAddress" BU_ PowerTakeOff_Ch2 7;
BA_ "ECU" BU_ PowerTakeOff_Ch2 "DEC";
BA_ "NodeLayerModules" BU_ PowerTakeOff_Ch2 "J1939_IL";
BA_ "NmStationAddress" BU_ Transmission1_Ch2 3;
BA_ "ECU" BU_ Transmission1_Ch2 "DEC";
BA_ "NodeLayerModules" BU_ Transmission1_Ch2 "J1939_IL";
BA_ "NmStationAddress" BU_ FEHR_1 137;
BA_ "NmJ1939Function" BU_ FEHR_1 25;
BA_ "NmJ1939FunctionInstance" BU_ FEHR_1 6;
BA_ "NmJ1939IndustryGroup" BU_ FEHR_1 2;
BA_ "NmJ1939ManufacturerCode" BU_ FEHR_1 51;
BA_ "NmJ1939System" BU_ FEHR_1 13;
BA_ "ECU" BU_ FEHR_1 "FEHR_1";
BA_ "NodeLayerModules" BU_ FEHR_1 "J1939_IL";
BA_ "NmStationAddress" BU_ REHR_5 132;
BA_ "NmJ1939Function" BU_ REHR_5 25;
BA_ "NmJ1939FunctionInstance" BU_ REHR_5 5;
BA_ "NmJ1939IndustryGroup" BU_ REHR_5 2;
BA_ "NmJ1939ManufacturerCode" BU_ REHR_5 51;
BA_ "NmJ1939System" BU_ REHR_5 13;
BA_ "ECU" BU_ REHR_5 "REHR_5";
BA_ "NodeLayerModules" BU_ REHR_5 "J1939_IL";
BA_ "NmStationAddress" BU_ REHR_4 131;
BA_ "NmJ1939Function" BU_ REHR_4 25;
BA_ "NmJ1939FunctionInstance" BU_ REHR_4 4;
BA_ "NmJ1939IndustryGroup" BU_ REHR_4 2;
BA_ "NmJ1939ManufacturerCode" BU_ REHR_4 51;
BA_ "NmJ1939System" BU_ REHR_4 13;
BA_ "ECU" BU_ REHR_4 "REHR_4";
BA_ "NodeLayerModules" BU_ REHR_4 "J1939_IL";
BA_ "NmStationAddress" BU_ REHR_3 130;
BA_ "NmJ1939Function" BU_ REHR_3 25;
BA_ "NmJ1939FunctionInstance" BU_ REHR_3 4;
BA_ "NmJ1939IndustryGroup" BU_ REHR_3 2;
BA_ "NmJ1939ManufacturerCode" BU_ REHR_3 51;
BA_ "NmJ1939System" BU_ REHR_3 13;
BA_ "ECU" BU_ REHR_3 "REHR_3";
BA_ "NodeLayerModules" BU_ REHR_3 "J1939_IL";
BA_ "NmStationAddress" BU_ REHR_2 129;
BA_ "NmJ1939Function" BU_ REHR_2 25;
BA_ "NmJ1939FunctionInstance" BU_ REHR_2 4;
BA_ "NmJ1939IndustryGroup" BU_ REHR_2 2;
BA_ "NmJ1939ManufacturerCode" BU_ REHR_2 51;
BA_ "NmJ1939System" BU_ REHR_2 13;
BA_ "ECU" BU_ REHR_2 "REHR_2";
BA_ "NodeLayerModules" BU_ REHR_2 "J1939_IL";
BA_ "NmStationAddress" BU_ REHR_1 128;
BA_ "NmJ1939Function" BU_ REHR_1 25;
BA_ "NmJ1939FunctionInstance" BU_ REHR_1 3;
BA_ "NmJ1939IndustryGroup" BU_ REHR_1 2;
BA_ "NmJ1939ManufacturerCode" BU_ REHR_1 51;
BA_ "NmJ1939System" BU_ REHR_1 13;
BA_ "ECU" BU_ REHR_1 "REHR_1";
BA_ "NodeLayerModules" BU_ REHR_1 "J1939_IL";
BA_ "NmStationAddress" BU_ InstrumentCluster_Ch2 23;
BA_ "ECU" BU_ InstrumentCluster_Ch2 "IC";
BA_ "NodeLayerModules" BU_ InstrumentCluster_Ch2 "J1939_IL";
BA_ "NmStationAddress" BU_ ManagementComputer_Ch2 39;
BA_ "ECU" BU_ ManagementComputer_Ch2 "UCM";
BA_ "NodeLayerModules" BU_ ManagementComputer_Ch2 "J1939_IL";
BA_ "NmStationAddress" BU_ GWAY_OnBoardDiagnosticUnit_Ch2 43;
BA_ "ECU" BU_ GWAY_OnBoardDiagnosticUnit_Ch2 "UCM";
BA_ "NodeLayerModules" BU_ GWAY_OnBoardDiagnosticUnit_Ch2 "J1939_IL";
BA_ "NmStationAddress" BU_ GWAY_OffBoardDiagTool1_VB1_Ch2 249;
BA_ "ECU" BU_ GWAY_OffBoardDiagTool1_VB1_Ch2 "UCM";
BA_ "NodeLayerModules" BU_ GWAY_OffBoardDiagTool1_VB1_Ch2 "J1939_IL";
BA_ "NmStationAddress" BU_ GWAY_Engine1_Ch2 0;
BA_ "ECU" BU_ GWAY_Engine1_Ch2 "UCM";
BA_ "NodeLayerModules" BU_ GWAY_Engine1_Ch2 "J1939_IL";
BA_ "NmStationAddress" BU_ GWAY_CabDisplay1_Ch2 40;
BA_ "ECU" BU_ GWAY_CabDisplay1_Ch2 "UCM";
BA_ "NodeLayerModules" BU_ GWAY_CabDisplay1_Ch2 "J1939_IL";
BA_ "NmStationAddress" BU_ AuxiliaryValveControl_Ch2 34;
BA_ "ECU" BU_ AuxiliaryValveControl_Ch2 "UCM";
BA_ "NodeLayerModules" BU_ AuxiliaryValveControl_Ch2 "J1939_IL";
BA_ "TpJ1939VarDlc" BO_ 2565350026 1;
BA_ "CI_ShowSignals" BO_ 2565350026 0;
BA_ "GenMsgDelayTime" BO_ 2565350026 0;
BA_ "TpJ1939VarDlc" BO_ 2566835082 1;
BA_ "CI_ShowSignals" BO_ 2566835082 0;
BA_ "GenMsgDelayTime" BO_ 2566835082 0;
BA_ "GenMsgRequestable" BO_ 2566835082 1;
BA_ "PGN_Definition" BO_ 2566838922 "J1939 Standard";
BA_ "CI_ShowSignals" BO_ 2566838922 0;
BA_ "CI_PgVersion" BO_ 2566838922 "-1";
BA_ "CI_GroupSignals" BO_ 2566838922 10;
BA_ "GenMsgRequestable" BO_ 2566838922 1;
BA_ "CI_AllowedLostMessages" BO_ 2566854794 2;
BA_ "CI_AliveTimeout" BO_ 2566854794 400;
BA_ "CI_ShowSignals" BO_ 2566854794 0;
BA_ "GenMsgCycleTime" BO_ 2566854794 100;
BA_ "GenMsgSendType" BO_ 2566854794 0;
BA_ "CI_ShowSignals" BO_ 2566866058 0;
BA_ "CI_AllowedLostMessages" BO_ 2566865546 2;
BA_ "CI_AliveTimeout" BO_ 2566865546 400;
BA_ "CI_ShowSignals" BO_ 2566865546 0;
BA_ "GenMsgCycleTime" BO_ 2566865546 100;
BA_ "GenMsgSendType" BO_ 2566865546 0;
BA_ "TpJ1939VarDlc" BO_ 2564487562 1;
BA_ "CI_ShowSignals" BO_ 2564487562 0;
BA_ "DiagResponse" BO_ 2564487562 1;
BA_ "TpJ1939VarDlc" BO_ 2566843274 1;
BA_ "CI_ShowSignals" BO_ 2566843274 0;
BA_ "PGN_Definition" BO_ 2565799818 "J1939 Standard";
BA_ "CI_ShowSignals" BO_ 2565799818 0;
BA_ "GenMsgDelayTime" BO_ 2565799818 0;
BA_ "GenMsgRequestable" BO_ 2565799818 1;
BA_ "CI_AliveTimeout" BO_ 2566871586 300;
BA_ "GenMsgCycleTime" BO_ 2566871586 100;
BA_ "GenMsgSendType" BO_ 2566871586 0;
BA_ "TpJ1939VarDlc" BO_ 2566843265 1;
BA_ "CI_ShowSignals" BO_ 2566843265 0;
BA_ "TpJ1939VarDlc" BO_ 2564487553 1;
BA_ "CI_ShowSignals" BO_ 2564487553 0;
BA_ "GenMsgDelayTime" BO_ 2564487553 0;
BA_ "TpJ1939VarDlc" BO_ 2632777721 1;
BA_ "CI_ShowSignals" BO_ 2632777721 0;
BA_ "TpJ1939VarDlc" BO_ 2566838521 1;
BA_ "TpJ1939VarDlc" BO_ 2564456697 1;
BA_ "CI_ShowSignals" BO_ 2564456697 0;
BA_ "GenMsgDelayTime" BO_ 2564456697 0;
BA_ "TpJ1939VarDlc" BO_ 2566843264 1;
BA_ "TpJ1939VarDlc" BO_ 2564487552 1;
BA_ "CI_ShowSignals" BO_ 2564487552 0;
BA_ "GenMsgDelayTime" BO_ 2564487552 0;
BA_ "TpJ1939VarDlc" BO_ 2560825102 1;
BA_ "CI_GroupSignals" BO_ 2560825102 2;
BA_ "GenMsgRequestable" BO_ 2560825102 1;
BA_ "TpJ1939VarDlc" BO_ 2632712073 1;
BA_ "CI_ShowSignals" BO_ 2632712073 0;
BA_ "TpJ1939VarDlc" BO_ 2632712074 1;
BA_ "CI_ShowSignals" BO_ 2632712074 0;
BA_ "TpJ1939VarDlc" BO_ 2632777609 1;
BA_ "CI_ShowSignals" BO_ 2632777609 0;
BA_ "GenSigStartValue" SG_ 3221225472 TrailerParkBrakeRequest 3;
BA_ "SigType" SG_ 3221225472 TrailerParkBrakeRequest 5;
BA_ "GenSigStartValue" SG_ 3221225472 SteeringBrakeDirection 3;
BA_ "GenSigStartValue" SG_ 3221225472 SecondaryBrakeSwitch 3;
BA_ "CI_FullName" SG_ 3221225472 PGN_RQST_F9_4C "Parameter Group Number (RQST)";
BA_ "CI_ParId" SG_ 3221225472 PGN_RQST_F9_4C "ESMD_24298";
BA_ "SPN" SG_ 3221225472 PGN_RQST_F9_4C 2540;
BA_ "SigType" SG_ 3221225472 PGN_RQST_F9_4C 6;
BA_ "CI_FullName" SG_ 3221225472 V5_Ref1 "Voltage 5 Reference 1";
BA_ "CI_ParId" SG_ 3221225472 V5_Ref1 "NW_2792";
BA_ "CI_SLOT_Name" SG_ 3221225472 V5_Ref1 "CNHev03";
BA_ "SPN" SG_ 3221225472 V5_Ref1 518844;
BA_ "CI_FullName" SG_ 3221225472 V5_Ref2 "Voltage 5 Reference 1";
BA_ "CI_ParId" SG_ 3221225472 V5_Ref2 "NW_2793";
BA_ "CI_SLOT_Name" SG_ 3221225472 V5_Ref2 "CNHev03";
BA_ "SPN" SG_ 3221225472 V5_Ref2 518845;
BA_ "CI_FullName" SG_ 3221225472 SensSupplyV_2Sts "Sensor Supply Voltage 2 Status";
BA_ "CI_ParId" SG_ 3221225472 SensSupplyV_2Sts "NW_2784";
BA_ "CI_SLOT_Name" SG_ 3221225472 SensSupplyV_2Sts "SAEbs02";
BA_ "SPN" SG_ 3221225472 SensSupplyV_2Sts 520805;
BA_ "CI_FullName" SG_ 3221225472 SensSupplyV_1 "Sensor Supply Voltage 1";
BA_ "CI_ParId" SG_ 3221225472 SensSupplyV_1 "NW_2790";
BA_ "CI_SLOT_Name" SG_ 3221225472 SensSupplyV_1 "CNHev06";
BA_ "SPN" SG_ 3221225472 SensSupplyV_1 3509;
BA_ "CI_FullName" SG_ 3221225472 V_12_VH1 "Voltage 12 VH1";
BA_ "CI_ParId" SG_ 3221225472 V_12_VH1 "NW_2789";
BA_ "CI_SLOT_Name" SG_ 3221225472 V_12_VH1 "CNHev06";
BA_ "SPN" SG_ 3221225472 V_12_VH1 518852;
BA_ "CI_FullName" SG_ 3221225472 V_12_VF1 "Voltage 12 VF1";
BA_ "CI_ParId" SG_ 3221225472 V_12_VF1 "NW_2788";
BA_ "CI_SLOT_Name" SG_ 3221225472 V_12_VF1 "CNHev06";
BA_ "SPN" SG_ 3221225472 V_12_VF1 518847;
BA_ "CI_FullName" SG_ 3221225472 CalibrOpMode "Calibration Operation Mode";
BA_ "CI_ParId" SG_ 3221225472 CalibrOpMode "ESMD_20881";
BA_ "CI_FullName" SG_ 3221225472 CalibrVal "Calibration Value";
BA_ "CI_ParId" SG_ 3221225472 CalibrVal "ESMD_20884";
BA_ "CI_FullName" SG_ 3221225472 CalibrErrCod "Calibration Error Code";
BA_ "CI_ParId" SG_ 3221225472 CalibrErrCod "ESMD_20880";
BA_ "CI_FullName" SG_ 3221225472 PrsSwSts "Pressure Switch Status";
BA_ "CI_ParId" SG_ 3221225472 PrsSwSts "ESMD_20932";
BA_ "CI_FullName" SG_ 3221225472 CalibrPnt "Calibration Point";
BA_ "CI_ParId" SG_ 3221225472 CalibrPnt "ESMD_20883";
BA_ "CI_RepetitionNum" SG_ 3221225472 XPD_MsgCnt 1;
BA_ "CI_RepetitionType" SG_ 3221225472 XPD_MsgCnt 3;
BA_ "CI_FullName" SG_ 3221225472 XPD_MsgCnt "XPD Message Counter";
BA_ "CI_ParId" SG_ 3221225472 XPD_MsgCnt "ESMD_24423";
BA_ "CI_SLOT_Name" SG_ 3221225472 XPD_MsgCnt "SAEct08";
BA_ "SPN" SG_ 3221225472 XPD_MsgCnt 518900;
BA_ "CI_RepetitionNum" SG_ 3221225472 XPD_MsgChksum 1;
BA_ "CI_RepetitionType" SG_ 3221225472 XPD_MsgChksum 3;
BA_ "CI_FullName" SG_ 3221225472 XPD_MsgChksum "XPD Message Checksum";
BA_ "CI_ParId" SG_ 3221225472 XPD_MsgChksum "ESMD_24422";
BA_ "CI_SLOT_Name" SG_ 3221225472 XPD_MsgChksum "SAEct08";
BA_ "SPN" SG_ 3221225472 XPD_MsgChksum 518899;
BA_ "CI_RepetitionNum" SG_ 3221225472 PBrakeActvReq 1;
BA_ "CI_RepetitionType" SG_ 3221225472 PBrakeActvReq 3;
BA_ "CI_FullName" SG_ 3221225472 PBrakeActvReq "Park Brake Activation Request";
BA_ "CI_ParId" SG_ 3221225472 PBrakeActvReq "ESMD_24441";
BA_ "CI_SLOT_Name" SG_ 3221225472 PBrakeActvReq "SAEbs02";
BA_ "SPN" SG_ 3221225472 PBrakeActvReq 518961;
BA_ "CI_FullName" SG_ 3221225472 AuxEquipSupplyPrs "Auxiliary Equipment Supply Pressure";
BA_ "CI_ParId" SG_ 3221225472 AuxEquipSupplyPrs "ESMD_00596";
BA_ "CI_SLOT_Name" SG_ 3221225472 AuxEquipSupplyPrs "SAEpr13";
BA_ "SPN" SG_ 3221225472 AuxEquipSupplyPrs 1089;
BA_ "CI_FullName" SG_ 3221225472 AirSuspnsnSupplyPrs "Air Suspension Supply Pressure";
BA_ "CI_ParId" SG_ 3221225472 AirSuspnsnSupplyPrs "ESMD_00539";
BA_ "CI_SLOT_Name" SG_ 3221225472 AirSuspnsnSupplyPrs "SAEpr13";
BA_ "SPN" SG_ 3221225472 AirSuspnsnSupplyPrs 1090;
BA_ "CI_FullName" SG_ 3221225472 AirComprSts "Air Compressor Status";
BA_ "CI_ParId" SG_ 3221225472 AirComprSts "ESMD_00537";
BA_ "CI_SLOT_Name" SG_ 3221225472 AirComprSts "SAEbs02";
BA_ "SPN" SG_ 3221225472 AirComprSts 1351;
BA_ "CI_FullName" SG_ 3221225472 PwtCircAirSupplyPrs "Powertrain Circuit Air Supply Pressure";
BA_ "CI_ParId" SG_ 3221225472 PwtCircAirSupplyPrs "ESMD_15070";
BA_ "CI_SLOT_Name" SG_ 3221225472 PwtCircAirSupplyPrs "SAEpr13";
BA_ "SPN" SG_ 3221225472 PwtCircAirSupplyPrs 6305;
BA_ "CI_FullName" SG_ 3221225472 EngIdleIncSw "Engine Idle Increment Switch";
BA_ "CI_ParId" SG_ 3221225472 EngIdleIncSw "ESMD_01611";
BA_ "CI_SLOT_Name" SG_ 3221225472 EngIdleIncSw "SAEbs02";
BA_ "SPN" SG_ 3221225472 EngIdleIncSw 968;
BA_ "CI_FullName" SG_ 3221225472 EngIdleDecrSw "Engine Idle Decrement Switch";
BA_ "CI_ParId" SG_ 3221225472 EngIdleDecrSw "ESMD_01610";
BA_ "CI_SLOT_Name" SG_ 3221225472 EngIdleDecrSw "SAEbs02";
BA_ "SPN" SG_ 3221225472 EngIdleDecrSw 967;
BA_ "CI_FullName" SG_ 3221225472 EngTestModeSw "Engine Test Mode Switch";
BA_ "CI_ParId" SG_ 3221225472 EngTestModeSw "ESMD_01812";
BA_ "CI_SLOT_Name" SG_ 3221225472 EngTestModeSw "SAEbs02";
BA_ "SPN" SG_ 3221225472 EngTestModeSw 966;
BA_ "CI_FullName" SG_ 3221225472 EngShutdnOverrideSw "Engine Shutdown Override Switch";
BA_ "CI_ParId" SG_ 3221225472 EngShutdnOverrideSw "ESMD_01764";
BA_ "CI_SLOT_Name" SG_ 3221225472 EngShutdnOverrideSw "SAEbs02";
BA_ "SPN" SG_ 3221225472 EngShutdnOverrideSw 1237;
BA_ "CI_FullName" SG_ 3221225472 EHR_EvNumParamMux_F1 "EHR Valve Number Parameter Multiplex F1";
BA_ "CI_ParId" SG_ 3221225472 EHR_EvNumParamMux_F1 "ESMD_20936";
BA_ "CI_FullName" SG_ 3221225472 EHR_EvNumParamMux_F2 "EHR Valve Number Parameter Multiplex F2";
BA_ "CI_ParId" SG_ 3221225472 EHR_EvNumParamMux_F2 "ESMD_20937";
BA_ "CI_FullName" SG_ 3221225472 EHR_EvNumParamMux_F3 "EHR Valve Number Parameter Multiplex F3";
BA_ "CI_ParId" SG_ 3221225472 EHR_EvNumParamMux_F3 "ESMD_20938";
BA_ "CI_FullName" SG_ 3221225472 EHR_EvNumParamMux_F4 "EHR Valve Number Parameter Multiplex F4";
BA_ "CI_ParId" SG_ 3221225472 EHR_EvNumParamMux_F4 "ESMD_20939";
BA_ "GenSigAutoGenSnd" SG_ 3221225472 BrakeSw 0;
BA_ "GenSigAutoGenDsp" SG_ 3221225472 BrakeSw 0;
BA_ "CI_RepetitionNum" SG_ 3221225472 BrakeSw 1;
BA_ "CI_RepetitionType" SG_ 3221225472 BrakeSw 3;
BA_ "CI_RepetitionComplemented" SG_ 3221225472 BrakeSw 2;
BA_ "CI_FullName" SG_ 3221225472 BrakeSw "Brake Switch";
BA_ "CI_ParId" SG_ 3221225472 BrakeSw "ESMD_00832";
BA_ "CI_SLOT_Name" SG_ 3221225472 BrakeSw "SAEbs02";
BA_ "SPN" SG_ 3221225472 BrakeSw 597;
BA_ "GenSigAutoGenSnd" SG_ 3221225472 CC_AccelSw 0;
BA_ "GenSigAutoGenDsp" SG_ 3221225472 CC_AccelSw 0;
BA_ "CI_RepetitionComplemented" SG_ 3221225472 CC_AccelSw 2;
BA_ "CI_FullName" SG_ 3221225472 CC_AccelSw "Cruise Control Accelerate Switch";
BA_ "CI_ParId" SG_ 3221225472 CC_AccelSw "ESMD_00949";
BA_ "CI_SLOT_Name" SG_ 3221225472 CC_AccelSw "SAEbs02";
BA_ "SPN" SG_ 3221225472 CC_AccelSw 602;
BA_ "GenSigAutoGenSnd" SG_ 3221225472 CC_Actv 0;
BA_ "GenSigAutoGenDsp" SG_ 3221225472 CC_Actv 0;
BA_ "CI_RepetitionComplemented" SG_ 3221225472 CC_Actv 2;
BA_ "CI_FullName" SG_ 3221225472 CC_Actv "Cruise Control Active";
BA_ "CI_ParId" SG_ 3221225472 CC_Actv "ESMD_00950";
BA_ "CI_SLOT_Name" SG_ 3221225472 CC_Actv "SAEbs02";
BA_ "SPN" SG_ 3221225472 CC_Actv 595;
BA_ "CI_FullName" SG_ 3221225472 MsgChksum_2 "Message Checksum 2";
BA_ "CI_ParId" SG_ 3221225472 MsgChksum_2 "ESMD_02698";
BA_ "CI_SLOT_Name" SG_ 3221225472 MsgChksum_2 "SAEct08";
BA_ "SPN" SG_ 3221225472 MsgChksum_2 4207;
BA_ "GenSigAutoGenSnd" SG_ 3221225472 CC_CoastDecelSw 0;
BA_ "GenSigAutoGenDsp" SG_ 3221225472 CC_CoastDecelSw 0;
BA_ "CI_RepetitionComplemented" SG_ 3221225472 CC_CoastDecelSw 2;
BA_ "CI_FullName" SG_ 3221225472 CC_CoastDecelSw "Cruise Control Coast (Decelerate) Switch";
BA_ "CI_ParId" SG_ 3221225472 CC_CoastDecelSw "ESMD_00951";
BA_ "CI_SLOT_Name" SG_ 3221225472 CC_CoastDecelSw "SAEbs02";
BA_ "SPN" SG_ 3221225472 CC_CoastDecelSw 600;
BA_ "GenSigAutoGenSnd" SG_ 3221225472 CC_EnaSw 0;
BA_ "GenSigAutoGenDsp" SG_ 3221225472 CC_EnaSw 0;
BA_ "CI_RepetitionComplemented" SG_ 3221225472 CC_EnaSw 2;
BA_ "CI_FullName" SG_ 3221225472 CC_EnaSw "Cruise Control Enable Switch";
BA_ "CI_ParId" SG_ 3221225472 CC_EnaSw "ESMD_00953";
BA_ "CI_SLOT_Name" SG_ 3221225472 CC_EnaSw "SAEbs02";
BA_ "SPN" SG_ 3221225472 CC_EnaSw 596;
BA_ "CI_FullName" SG_ 3221225472 CC_PauseSw "Cruise Control Pause Switch";
BA_ "CI_ParId" SG_ 3221225472 CC_PauseSw "ESMD_00957";
BA_ "CI_SLOT_Name" SG_ 3221225472 CC_PauseSw "SAEbs02";
BA_ "SPN" SG_ 3221225472 CC_PauseSw 1633;
BA_ "SigType" SG_ 3221225472 CC_PauseSw 4;
BA_ "GenSigAutoGenSnd" SG_ 3221225472 CC_ResumSw 0;
BA_ "GenSigAutoGenDsp" SG_ 3221225472 CC_ResumSw 0;
BA_ "CI_RepetitionComplemented" SG_ 3221225472 CC_ResumSw 2;
BA_ "CI_FullName" SG_ 3221225472 CC_ResumSw "Cruise Control Resume Switch";
BA_ "CI_ParId" SG_ 3221225472 CC_ResumSw "ESMD_00959";
BA_ "CI_SLOT_Name" SG_ 3221225472 CC_ResumSw "SAEbs02";
BA_ "SPN" SG_ 3221225472 CC_ResumSw 601;
BA_ "GenSigAutoGenSnd" SG_ 3221225472 CC_SetSpd 0;
BA_ "GenSigAutoGenDsp" SG_ 3221225472 CC_SetSpd 0;
BA_ "CI_RepetitionComplemented" SG_ 3221225472 CC_SetSpd 2;
BA_ "CI_FullName" SG_ 3221225472 CC_SetSpd "Cruise Control Set Speed";
BA_ "CI_ParId" SG_ 3221225472 CC_SetSpd "ESMD_00960";
BA_ "CI_SLOT_Name" SG_ 3221225472 CC_SetSpd "SAEvl05";
BA_ "SPN" SG_ 3221225472 CC_SetSpd 86;
BA_ "GenSigAutoGenSnd" SG_ 3221225472 CC_SetSw 0;
BA_ "GenSigAutoGenDsp" SG_ 3221225472 CC_SetSw 0;
BA_ "CI_RepetitionComplemented" SG_ 3221225472 CC_SetSw 2;
BA_ "CI_FullName" SG_ 3221225472 CC_SetSw "Cruise Control Set Switch";
BA_ "CI_ParId" SG_ 3221225472 CC_SetSw "ESMD_00961";
BA_ "CI_SLOT_Name" SG_ 3221225472 CC_SetSw "SAEbs02";
BA_ "SPN" SG_ 3221225472 CC_SetSw 599;
BA_ "GenSigAutoGenSnd" SG_ 3221225472 CC_Sts 0;
BA_ "GenSigAutoGenDsp" SG_ 3221225472 CC_Sts 0;
BA_ "CI_RepetitionComplemented" SG_ 3221225472 CC_Sts 2;
BA_ "CI_FullName" SG_ 3221225472 CC_Sts "Cruise Control States";
BA_ "CI_ParId" SG_ 3221225472 CC_Sts "ESMD_00962";
BA_ "CI_SLOT_Name" SG_ 3221225472 CC_Sts "SAEbs03";
BA_ "SPN" SG_ 3221225472 CC_Sts 527;
BA_ "GenSigAutoGenSnd" SG_ 3221225472 CltchSw 0;
BA_ "GenSigAutoGenDsp" SG_ 3221225472 CltchSw 0;
BA_ "CI_RepetitionComplemented" SG_ 3221225472 CltchSw 2;
BA_ "CI_FullName" SG_ 3221225472 CltchSw "Clutch Switch";
BA_ "CI_ParId" SG_ 3221225472 CltchSw "ESMD_00914";
BA_ "CI_SLOT_Name" SG_ 3221225472 CltchSw "SAEbs02";
BA_ "SPN" SG_ 3221225472 CltchSw 598;
BA_ "GenSigAutoGenSnd" SG_ 3221225472 N2SpdAxSw 0;
BA_ "GenSigAutoGenDsp" SG_ 3221225472 N2SpdAxSw 0;
BA_ "CI_RepetitionComplemented" SG_ 3221225472 N2SpdAxSw 2;
BA_ "CI_FullName" SG_ 3221225472 N2SpdAxSw "Two Speed Axle Switch";
BA_ "CI_ParId" SG_ 3221225472 N2SpdAxSw "ESMD_03683";
BA_ "CI_SLOT_Name" SG_ 3221225472 N2SpdAxSw "SAEbs02";
BA_ "SPN" SG_ 3221225472 N2SpdAxSw 69;
BA_ "CI_FullName" SG_ 3221225472 PBrakeRleasInhReq "Park Brake Release Inhibit Request";
BA_ "CI_ParId" SG_ 3221225472 PBrakeRleasInhReq "ESMD_02838";
BA_ "CI_SLOT_Name" SG_ 3221225472 PBrakeRleasInhReq "SAEbs02";
BA_ "SPN" SG_ 3221225472 PBrakeRleasInhReq 3807;
BA_ "SigType" SG_ 3221225472 PBrakeRleasInhReq 4;
BA_ "GenSigAutoGenSnd" SG_ 3221225472 PBrakeSw 0;
BA_ "GenSigAutoGenDsp" SG_ 3221225472 PBrakeSw 0;
BA_ "CI_RepetitionNum" SG_ 3221225472 PBrakeSw 1;
BA_ "CI_RepetitionType" SG_ 3221225472 PBrakeSw 3;
BA_ "CI_RepetitionComplemented" SG_ 3221225472 PBrakeSw 2;
BA_ "CI_FullName" SG_ 3221225472 PBrakeSw "Parking Brake Switch";
BA_ "CI_ParId" SG_ 3221225472 PBrakeSw "ESMD_02845";
BA_ "CI_SLOT_Name" SG_ 3221225472 PBrakeSw "SAEbs02";
BA_ "SPN" SG_ 3221225472 PBrakeSw 70;
BA_ "GenSigAutoGenSnd" SG_ 3221225472 PTO_GovSts 0;
BA_ "GenSigAutoGenDsp" SG_ 3221225472 PTO_GovSts 0;
BA_ "CI_RepetitionComplemented" SG_ 3221225472 PTO_GovSts 2;
BA_ "CI_FullName" SG_ 3221225472 PTO_GovSts "PTO Governor State";
BA_ "CI_ParId" SG_ 3221225472 PTO_GovSts "ESMD_02912";
BA_ "CI_SLOT_Name" SG_ 3221225472 PTO_GovSts "SAEbs05";
BA_ "SPN" SG_ 3221225472 PTO_GovSts 976;
BA_ "GenSigAutoGenSnd" SG_ 2565350026 AddrAccssDeny 0;
BA_ "GenSigAutoGenDsp" SG_ 2565350026 AddrAccssDeny 0;
BA_ "CI_FullName" SG_ 2565350026 AddrAccssDeny "Address Access Denied";
BA_ "CI_ParId" SG_ 2565350026 AddrAccssDeny "ESMD_00040";
BA_ "SPN" SG_ 2565350026 AddrAccssDeny 3292;
BA_ "GenSigAutoGenSnd" SG_ 2565350026 AddrAck 0;
BA_ "GenSigAutoGenDsp" SG_ 2565350026 AddrAck 0;
BA_ "CI_FullName" SG_ 2565350026 AddrAck "Address Acknowledged";
BA_ "CI_ParId" SG_ 2565350026 AddrAck "ESMD_00041";
BA_ "SPN" SG_ 2565350026 AddrAck 3290;
BA_ "GenSigAutoGenSnd" SG_ 2565350026 AddrBusy 0;
BA_ "GenSigAutoGenDsp" SG_ 2565350026 AddrBusy 0;
BA_ "CI_FullName" SG_ 2565350026 AddrBusy "Address Busy";
BA_ "CI_ParId" SG_ 2565350026 AddrBusy "ESMD_00043";
BA_ "SPN" SG_ 2565350026 AddrBusy 3293;
BA_ "GenSigAutoGenSnd" SG_ 2565350026 AddrNegAck 0;
BA_ "GenSigAutoGenDsp" SG_ 2565350026 AddrNegAck 0;
BA_ "CI_FullName" SG_ 2565350026 AddrNegAck "Address Negative Acknowledgement";
BA_ "CI_ParId" SG_ 2565350026 AddrNegAck "ESMD_00044";
BA_ "SPN" SG_ 2565350026 AddrNegAck 3291;
BA_ "GenSigAutoGenSnd" SG_ 2565350026 CByteAckm 0;
BA_ "GenSigAutoGenDsp" SG_ 2565350026 CByteAckm 0;
BA_ "CI_FullName" SG_ 2565350026 CByteAckm "Control Byte (ACKM)";
BA_ "CI_ParId" SG_ 2565350026 CByteAckm "ESMD_00942";
BA_ "SPN" SG_ 2565350026 CByteAckm 2541;
BA_ "SigType" SG_ 2565350026 CByteAckm 1;
BA_ "GenSigAutoGenSnd" SG_ 2565350026 GrpFunctValAck 0;
BA_ "GenSigAutoGenDsp" SG_ 2565350026 GrpFunctValAck 0;
BA_ "CI_RepetitionComplemented" SG_ 2565350026 GrpFunctValAck 2;
BA_ "CI_FullName" SG_ 2565350026 GrpFunctValAck "Group Function Value (ACK)";
BA_ "CI_ParId" SG_ 2565350026 GrpFunctValAck "ESMD_02063";
BA_ "SPN" SG_ 2565350026 GrpFunctValAck 2542;
BA_ "SigType" SG_ 2565350026 GrpFunctValAck 1;
BA_ "CI_FullName" SG_ 2565350026 GrpFunctValNAck "Group Function Value (NACK)";
BA_ "CI_ParId" SG_ 2565350026 GrpFunctValNAck "ESMD_02063";
BA_ "SPN" SG_ 2565350026 GrpFunctValNAck 2542;
BA_ "SigType" SG_ 2565350026 GrpFunctValNAck 1;
BA_ "CI_FullName" SG_ 2565350026 GrpFunctValNAckAd "Group Function Value (Access Denied)";
BA_ "CI_ParId" SG_ 2565350026 GrpFunctValNAckAd "ESMD_02063";
BA_ "SPN" SG_ 2565350026 GrpFunctValNAckAd 2542;
BA_ "SigType" SG_ 2565350026 GrpFunctValNAckAd 1;
BA_ "CI_FullName" SG_ 2565350026 GrpFunctValNAckBusy "Group Function Value (Cannot Respond)";
BA_ "CI_ParId" SG_ 2565350026 GrpFunctValNAckBusy "ESMD_02063";
BA_ "SPN" SG_ 2565350026 GrpFunctValNAckBusy 2542;
BA_ "SigType" SG_ 2565350026 GrpFunctValNAckBusy 1;
BA_ "CI_FullName" SG_ 2565350026 PGN_Ack "Parameter Group Number (RQST2)";
BA_ "CI_ParId" SG_ 2565350026 PGN_Ack "ESMD_02835";
BA_ "SPN" SG_ 2565350026 PGN_Ack 2574;
BA_ "SigType" SG_ 2565350026 PGN_Ack 6;
BA_ "CI_FullName" SG_ 2565350026 PGN_NAck "Parameter Group Number (RQST2)";
BA_ "CI_ParId" SG_ 2565350026 PGN_NAck "ESMD_02835";
BA_ "SPN" SG_ 2565350026 PGN_NAck 2574;
BA_ "SigType" SG_ 2565350026 PGN_NAck 6;
BA_ "CI_FullName" SG_ 2565350026 PGN_NAckAd "Parameter Group Number (RQST2)";
BA_ "CI_ParId" SG_ 2565350026 PGN_NAckAd "ESMD_02835";
BA_ "SPN" SG_ 2565350026 PGN_NAckAd 2574;
BA_ "SigType" SG_ 2565350026 PGN_NAckAd 6;
BA_ "CI_FullName" SG_ 2565350026 PGN_NAckBusy "Parameter Group Number (RQST2)";
BA_ "CI_ParId" SG_ 2565350026 PGN_NAckBusy "ESMD_02835";
BA_ "SPN" SG_ 2565350026 PGN_NAckBusy 2574;
BA_ "SigType" SG_ 2565350026 PGN_NAckBusy 6;
BA_ "CI_FullName" SG_ 2566835082 AmbrWarnLmp "Amber Warning Lamp";
BA_ "CI_ParId" SG_ 2566835082 AmbrWarnLmp "ESMD_00554";
BA_ "CI_SLOT_Name" SG_ 2566835082 AmbrWarnLmp "SAEbs02";
BA_ "SPN" SG_ 2566835082 AmbrWarnLmp 624;
BA_ "CI_FullName" SG_ 2566835082 DTC_01 "Diagnostic Trouble Code 01";
BA_ "CI_ParId" SG_ 2566835082 DTC_01 "ESMD_01142";
BA_ "CI_FullName" SG_ 2566835082 DTC_02 "Diagnostic Trouble Code 02";
BA_ "CI_ParId" SG_ 2566835082 DTC_02 "ESMD_01143";
BA_ "CI_FullName" SG_ 2566835082 DTC_03 "Diagnostic Trouble Code 03";
BA_ "CI_ParId" SG_ 2566835082 DTC_03 "ESMD_01144";
BA_ "CI_FullName" SG_ 2566835082 DTC_04 "Diagnostic Trouble Code 04";
BA_ "CI_ParId" SG_ 2566835082 DTC_04 "ESMD_01145";
BA_ "CI_FullName" SG_ 2566835082 FlashAmbrWarnLmpAWL "Flash Amber Warning Lamp (AWL)";
BA_ "CI_ParId" SG_ 2566835082 FlashAmbrWarnLmpAWL "ESMD_01963";
BA_ "CI_SLOT_Name" SG_ 2566835082 FlashAmbrWarnLmpAWL "SAEbs02";
BA_ "SPN" SG_ 2566835082 FlashAmbrWarnLmpAWL 3040;
BA_ "CI_FullName" SG_ 2566835082 FlashMIL "Flash Malfunction Indicator Lamp";
BA_ "CI_ParId" SG_ 2566835082 FlashMIL "ESMD_01964";
BA_ "CI_SLOT_Name" SG_ 2566835082 FlashMIL "SAEbs02";
BA_ "SPN" SG_ 2566835082 FlashMIL 3038;
BA_ "CI_FullName" SG_ 2566835082 FlashProtLmp "Flash Protect Lamp";
BA_ "CI_ParId" SG_ 2566835082 FlashProtLmp "ESMD_01965";
BA_ "CI_SLOT_Name" SG_ 2566835082 FlashProtLmp "SAEbs02";
BA_ "SPN" SG_ 2566835082 FlashProtLmp 3041;
BA_ "CI_FullName" SG_ 2566835082 FlashRedStopLmpRSL "Flash Red Stop Lamp (RSL)";
BA_ "CI_ParId" SG_ 2566835082 FlashRedStopLmpRSL "ESMD_01966";
BA_ "CI_SLOT_Name" SG_ 2566835082 FlashRedStopLmpRSL "SAEbs02";
BA_ "SPN" SG_ 2566835082 FlashRedStopLmpRSL 3039;
BA_ "CI_FullName" SG_ 2566835082 MIL "Malfunction Indicator Lamp";
BA_ "CI_ParId" SG_ 2566835082 MIL "ESMD_02672";
BA_ "CI_SLOT_Name" SG_ 2566835082 MIL "SAEbs02";
BA_ "SPN" SG_ 2566835082 MIL 1213;
BA_ "CI_FullName" SG_ 2566835082 ProtLmp "Protect Lamp";
BA_ "CI_ParId" SG_ 2566835082 ProtLmp "ESMD_02904";
BA_ "CI_SLOT_Name" SG_ 2566835082 ProtLmp "SAEbs02";
BA_ "SPN" SG_ 2566835082 ProtLmp 987;
BA_ "CI_FullName" SG_ 2566835082 RedStopLmp "Red Stop Lamp";
BA_ "CI_ParId" SG_ 2566835082 RedStopLmp "ESMD_02945";
BA_ "CI_SLOT_Name" SG_ 2566835082 RedStopLmp "SAEbs02";
BA_ "SPN" SG_ 2566835082 RedStopLmp 623;
BA_ "CI_FullName" SG_ 2566838922 Appl_Id_Byte_24 "Software Identification";
BA_ "CI_ParId" SG_ 2566838922 Appl_Id_Byte_24 "ESMD_03139";
BA_ "CI_SLOT_Name" SG_ 2566838922 Appl_Id_Byte_24 "SAEatad0200";
BA_ "SPN" SG_ 2566838922 Appl_Id_Byte_24 234;
BA_ "CI_FullName" SG_ 2566838922 Appl_Id_Byte_25 "Software Identification";
BA_ "CI_ParId" SG_ 2566838922 Appl_Id_Byte_25 "ESMD_03139";
BA_ "CI_SLOT_Name" SG_ 2566838922 Appl_Id_Byte_25 "SAEatad0200";
BA_ "SPN" SG_ 2566838922 Appl_Id_Byte_25 234;
BA_ "CI_FullName" SG_ 2566838922 Appl_Id_Byte_26 "Software Identification";
BA_ "CI_ParId" SG_ 2566838922 Appl_Id_Byte_26 "ESMD_03139";
BA_ "CI_SLOT_Name" SG_ 2566838922 Appl_Id_Byte_26 "SAEatad0200";
BA_ "SPN" SG_ 2566838922 Appl_Id_Byte_26 234;
BA_ "CI_FullName" SG_ 2566838922 Appl_Id_Byte_27 "Software Identification";
BA_ "CI_ParId" SG_ 2566838922 Appl_Id_Byte_27 "ESMD_03139";
BA_ "CI_SLOT_Name" SG_ 2566838922 Appl_Id_Byte_27 "SAEatad0200";
BA_ "SPN" SG_ 2566838922 Appl_Id_Byte_27 234;
BA_ "CI_FullName" SG_ 2566838922 Appl_Id_Byte_28 "Software Identification";
BA_ "CI_ParId" SG_ 2566838922 Appl_Id_Byte_28 "ESMD_03139";
BA_ "CI_SLOT_Name" SG_ 2566838922 Appl_Id_Byte_28 "SAEatad0200";
BA_ "SPN" SG_ 2566838922 Appl_Id_Byte_28 234;
BA_ "CI_FullName" SG_ 2566838922 Appl_Id_Byte_29 "Software Identification";
BA_ "CI_ParId" SG_ 2566838922 Appl_Id_Byte_29 "ESMD_03139";
BA_ "CI_SLOT_Name" SG_ 2566838922 Appl_Id_Byte_29 "SAEatad0200";
BA_ "SPN" SG_ 2566838922 Appl_Id_Byte_29 234;
BA_ "CI_FullName" SG_ 2566838922 Appl_Id_Byte_30 "Software Identification";
BA_ "CI_ParId" SG_ 2566838922 Appl_Id_Byte_30 "ESMD_03139";
BA_ "CI_SLOT_Name" SG_ 2566838922 Appl_Id_Byte_30 "SAEatad0200";
BA_ "SPN" SG_ 2566838922 Appl_Id_Byte_30 234;
BA_ "CI_FullName" SG_ 2566838922 Appl_Id_Byte_31 "Software Identification";
BA_ "CI_ParId" SG_ 2566838922 Appl_Id_Byte_31 "ESMD_03139";
BA_ "CI_SLOT_Name" SG_ 2566838922 Appl_Id_Byte_31 "SAEatad0200";
BA_ "SPN" SG_ 2566838922 Appl_Id_Byte_31 234;
BA_ "CI_FullName" SG_ 2566838922 Appl_Id_Byte_32 "Software Identification";
BA_ "CI_ParId" SG_ 2566838922 Appl_Id_Byte_32 "ESMD_03139";
BA_ "CI_SLOT_Name" SG_ 2566838922 Appl_Id_Byte_32 "SAEatad0200";
BA_ "SPN" SG_ 2566838922 Appl_Id_Byte_32 234;
BA_ "CI_FullName" SG_ 2566838922 Appl_Id_Byte_33 "Software Identification";
BA_ "CI_ParId" SG_ 2566838922 Appl_Id_Byte_33 "ESMD_03139";
BA_ "CI_SLOT_Name" SG_ 2566838922 Appl_Id_Byte_33 "SAEatad0200";
BA_ "SPN" SG_ 2566838922 Appl_Id_Byte_33 234;
BA_ "CI_FullName" SG_ 2566838922 Appl_Id_Byte_34 "Software Identification";
BA_ "CI_ParId" SG_ 2566838922 Appl_Id_Byte_34 "ESMD_03139";
BA_ "CI_SLOT_Name" SG_ 2566838922 Appl_Id_Byte_34 "SAEatad0200";
BA_ "SPN" SG_ 2566838922 Appl_Id_Byte_34 234;
BA_ "CI_FullName" SG_ 2566838922 Appl_Id_Byte_35 "Software Identification";
BA_ "CI_ParId" SG_ 2566838922 Appl_Id_Byte_35 "ESMD_03139";
BA_ "CI_SLOT_Name" SG_ 2566838922 Appl_Id_Byte_35 "SAEatad0200";
BA_ "SPN" SG_ 2566838922 Appl_Id_Byte_35 234;
BA_ "CI_FullName" SG_ 2566838922 Appl_Id_Byte_36 "Software Identification";
BA_ "CI_ParId" SG_ 2566838922 Appl_Id_Byte_36 "ESMD_03139";
BA_ "CI_SLOT_Name" SG_ 2566838922 Appl_Id_Byte_36 "SAEatad0200";
BA_ "SPN" SG_ 2566838922 Appl_Id_Byte_36 234;
BA_ "CI_FullName" SG_ 2566838922 Appl_Id_Byte_37 "Software Identification";
BA_ "CI_ParId" SG_ 2566838922 Appl_Id_Byte_37 "ESMD_03139";
BA_ "CI_SLOT_Name" SG_ 2566838922 Appl_Id_Byte_37 "SAEatad0200";
BA_ "SPN" SG_ 2566838922 Appl_Id_Byte_37 234;
BA_ "CI_FullName" SG_ 2566838922 Appl_Id_Byte_38 "Software Identification";
BA_ "CI_ParId" SG_ 2566838922 Appl_Id_Byte_38 "ESMD_03139";
BA_ "CI_SLOT_Name" SG_ 2566838922 Appl_Id_Byte_38 "SAEatad0200";
BA_ "SPN" SG_ 2566838922 Appl_Id_Byte_38 234;
BA_ "CI_FullName" SG_ 2566838922 Appl_Id_Byte_39 "Software Identification";
BA_ "CI_ParId" SG_ 2566838922 Appl_Id_Byte_39 "ESMD_03139";
BA_ "CI_SLOT_Name" SG_ 2566838922 Appl_Id_Byte_39 "SAEatad0200";
BA_ "SPN" SG_ 2566838922 Appl_Id_Byte_39 234;
BA_ "CI_FullName" SG_ 2566838922 Appl_Id_Enum "Software Identification";
BA_ "CI_ParId" SG_ 2566838922 Appl_Id_Enum "ESMD_03139";
BA_ "CI_SLOT_Name" SG_ 2566838922 Appl_Id_Enum "SAEbs24";
BA_ "SPN" SG_ 2566838922 Appl_Id_Enum 234;
BA_ "CI_FullName" SG_ 2566838922 Bootloader_Id "Software Identification";
BA_ "CI_ParId" SG_ 2566838922 Bootloader_Id "ESMD_03139";
BA_ "CI_SLOT_Name" SG_ 2566838922 Bootloader_Id "SAEatad0200";
BA_ "SPN" SG_ 2566838922 Bootloader_Id 234;
BA_ "CI_FullName" SG_ 2566838922 Bootloader_Id_Byte_01 "Software Identification";
BA_ "CI_ParId" SG_ 2566838922 Bootloader_Id_Byte_01 "ESMD_03139";
BA_ "CI_SLOT_Name" SG_ 2566838922 Bootloader_Id_Byte_01 "SAEatad0200";
BA_ "SPN" SG_ 2566838922 Bootloader_Id_Byte_01 234;
BA_ "CI_FullName" SG_ 2566838922 Bootloader_Id_Byte_02 "Software Identification";
BA_ "CI_ParId" SG_ 2566838922 Bootloader_Id_Byte_02 "ESMD_03139";
BA_ "CI_SLOT_Name" SG_ 2566838922 Bootloader_Id_Byte_02 "SAEatad0200";
BA_ "SPN" SG_ 2566838922 Bootloader_Id_Byte_02 234;
BA_ "CI_FullName" SG_ 2566838922 Bootloader_Id_Byte_03 "Software Identification";
BA_ "CI_ParId" SG_ 2566838922 Bootloader_Id_Byte_03 "ESMD_03139";
BA_ "CI_SLOT_Name" SG_ 2566838922 Bootloader_Id_Byte_03 "SAEatad0200";
BA_ "SPN" SG_ 2566838922 Bootloader_Id_Byte_03 234;
BA_ "CI_FullName" SG_ 2566838922 Bootloader_Id_Byte_04 "Software Identification";
BA_ "CI_ParId" SG_ 2566838922 Bootloader_Id_Byte_04 "ESMD_03139";
BA_ "CI_SLOT_Name" SG_ 2566838922 Bootloader_Id_Byte_04 "SAEatad0200";
BA_ "SPN" SG_ 2566838922 Bootloader_Id_Byte_04 234;
BA_ "CI_FullName" SG_ 2566838922 Bootloader_Id_Byte_05 "Software Identification";
BA_ "CI_ParId" SG_ 2566838922 Bootloader_Id_Byte_05 "ESMD_03139";
BA_ "CI_SLOT_Name" SG_ 2566838922 Bootloader_Id_Byte_05 "SAEatad0200";
BA_ "SPN" SG_ 2566838922 Bootloader_Id_Byte_05 234;
BA_ "CI_FullName" SG_ 2566838922 Bootloader_Id_Byte_06 "Software Identification";
BA_ "CI_ParId" SG_ 2566838922 Bootloader_Id_Byte_06 "ESMD_03139";
BA_ "CI_SLOT_Name" SG_ 2566838922 Bootloader_Id_Byte_06 "SAEatad0200";
BA_ "SPN" SG_ 2566838922 Bootloader_Id_Byte_06 234;
BA_ "CI_FullName" SG_ 2566838922 Bootloader_Id_Byte_07 "Software Identification";
BA_ "CI_ParId" SG_ 2566838922 Bootloader_Id_Byte_07 "ESMD_03139";
BA_ "CI_SLOT_Name" SG_ 2566838922 Bootloader_Id_Byte_07 "SAEatad0200";
BA_ "SPN" SG_ 2566838922 Bootloader_Id_Byte_07 234;
BA_ "CI_FullName" SG_ 2566838922 Bootloader_Id_Byte_08 "Software Identification";
BA_ "CI_ParId" SG_ 2566838922 Bootloader_Id_Byte_08 "ESMD_03139";
BA_ "CI_SLOT_Name" SG_ 2566838922 Bootloader_Id_Byte_08 "SAEatad0200";
BA_ "SPN" SG_ 2566838922 Bootloader_Id_Byte_08 234;
BA_ "CI_FullName" SG_ 2566838922 Bootloader_Id_Byte_09 "Software Identification";
BA_ "CI_ParId" SG_ 2566838922 Bootloader_Id_Byte_09 "ESMD_03139";
BA_ "CI_SLOT_Name" SG_ 2566838922 Bootloader_Id_Byte_09 "SAEatad0200";
BA_ "SPN" SG_ 2566838922 Bootloader_Id_Byte_09 234;
BA_ "CI_FullName" SG_ 2566838922 Bootloader_Id_Byte_10 "Software Identification";
BA_ "CI_ParId" SG_ 2566838922 Bootloader_Id_Byte_10 "ESMD_03139";
BA_ "CI_SLOT_Name" SG_ 2566838922 Bootloader_Id_Byte_10 "SAEatad0200";
BA_ "SPN" SG_ 2566838922 Bootloader_Id_Byte_10 234;
BA_ "CI_FullName" SG_ 2566838922 Bootloader_Id_Byte_11 "Software Identification";
BA_ "CI_ParId" SG_ 2566838922 Bootloader_Id_Byte_11 "ESMD_03139";
BA_ "CI_SLOT_Name" SG_ 2566838922 Bootloader_Id_Byte_11 "SAEatad0200";
BA_ "SPN" SG_ 2566838922 Bootloader_Id_Byte_11 234;
BA_ "CI_FullName" SG_ 2566838922 Bootloader_Id_Byte_12 "Software Identification";
BA_ "CI_ParId" SG_ 2566838922 Bootloader_Id_Byte_12 "ESMD_03139";
BA_ "CI_SLOT_Name" SG_ 2566838922 Bootloader_Id_Byte_12 "SAEatad0200";
BA_ "SPN" SG_ 2566838922 Bootloader_Id_Byte_12 234;
BA_ "CI_FullName" SG_ 2566838922 Bootloader_Id_Byte_13 "Software Identification";
BA_ "CI_ParId" SG_ 2566838922 Bootloader_Id_Byte_13 "ESMD_03139";
BA_ "CI_SLOT_Name" SG_ 2566838922 Bootloader_Id_Byte_13 "SAEatad0200";
BA_ "SPN" SG_ 2566838922 Bootloader_Id_Byte_13 234;
BA_ "CI_FullName" SG_ 2566838922 Bootloader_Id_Byte_14 "Software Identification";
BA_ "CI_ParId" SG_ 2566838922 Bootloader_Id_Byte_14 "ESMD_03139";
BA_ "CI_SLOT_Name" SG_ 2566838922 Bootloader_Id_Byte_14 "SAEatad0200";
BA_ "SPN" SG_ 2566838922 Bootloader_Id_Byte_14 234;
BA_ "CI_FullName" SG_ 2566838922 Bootloader_Id_Byte_15 "Software Identification";
BA_ "CI_ParId" SG_ 2566838922 Bootloader_Id_Byte_15 "ESMD_03139";
BA_ "CI_SLOT_Name" SG_ 2566838922 Bootloader_Id_Byte_15 "SAEatad0200";
BA_ "SPN" SG_ 2566838922 Bootloader_Id_Byte_15 234;
BA_ "CI_FullName" SG_ 2566838922 Bootloader_Id_Byte_16 "Software Identification";
BA_ "CI_ParId" SG_ 2566838922 Bootloader_Id_Byte_16 "ESMD_03139";
BA_ "CI_SLOT_Name" SG_ 2566838922 Bootloader_Id_Byte_16 "SAEatad0200";
BA_ "SPN" SG_ 2566838922 Bootloader_Id_Byte_16 234;
BA_ "CI_FullName" SG_ 2566838922 Bootloader_Id_Byte_17 "Software Identification";
BA_ "CI_ParId" SG_ 2566838922 Bootloader_Id_Byte_17 "ESMD_03139";
BA_ "CI_SLOT_Name" SG_ 2566838922 Bootloader_Id_Byte_17 "SAEatad0200";
BA_ "SPN" SG_ 2566838922 Bootloader_Id_Byte_17 234;
BA_ "CI_FullName" SG_ 2566838922 Bootloader_Id_Byte_18 "Software Identification";
BA_ "CI_ParId" SG_ 2566838922 Bootloader_Id_Byte_18 "ESMD_03139";
BA_ "CI_SLOT_Name" SG_ 2566838922 Bootloader_Id_Byte_18 "SAEatad0200";
BA_ "SPN" SG_ 2566838922 Bootloader_Id_Byte_18 234;
BA_ "CI_FullName" SG_ 2566838922 Bootloader_Id_Byte_19 "Software Identification";
BA_ "CI_ParId" SG_ 2566838922 Bootloader_Id_Byte_19 "ESMD_03139";
BA_ "CI_SLOT_Name" SG_ 2566838922 Bootloader_Id_Byte_19 "SAEatad0200";
BA_ "SPN" SG_ 2566838922 Bootloader_Id_Byte_19 234;
BA_ "CI_FullName" SG_ 2566838922 Bootloader_Id_Byte_20 "Software Identification";
BA_ "CI_ParId" SG_ 2566838922 Bootloader_Id_Byte_20 "ESMD_03139";
BA_ "CI_SLOT_Name" SG_ 2566838922 Bootloader_Id_Byte_20 "SAEatad0200";
BA_ "SPN" SG_ 2566838922 Bootloader_Id_Byte_20 234;
BA_ "CI_FullName" SG_ 2566838922 Bootloader_Id_Byte_21 "Software Identification";
BA_ "CI_ParId" SG_ 2566838922 Bootloader_Id_Byte_21 "ESMD_03139";
BA_ "CI_SLOT_Name" SG_ 2566838922 Bootloader_Id_Byte_21 "SAEatad0200";
BA_ "SPN" SG_ 2566838922 Bootloader_Id_Byte_21 234;
BA_ "CI_FullName" SG_ 2566838922 Bootloader_Id_Byte_22 "Software Identification";
BA_ "CI_ParId" SG_ 2566838922 Bootloader_Id_Byte_22 "ESMD_03139";
BA_ "CI_SLOT_Name" SG_ 2566838922 Bootloader_Id_Byte_22 "SAEatad0200";
BA_ "SPN" SG_ 2566838922 Bootloader_Id_Byte_22 234;
BA_ "CI_FullName" SG_ 2566838922 Bootloader_Id_Byte_23 "Software Identification";
BA_ "CI_ParId" SG_ 2566838922 Bootloader_Id_Byte_23 "ESMD_03139";
BA_ "CI_SLOT_Name" SG_ 2566838922 Bootloader_Id_Byte_23 "SAEatad0200";
BA_ "SPN" SG_ 2566838922 Bootloader_Id_Byte_23 234;
BA_ "CI_FullName" SG_ 2566838922 Bootloader_Id_Byte_24 "Software Identification";
BA_ "CI_ParId" SG_ 2566838922 Bootloader_Id_Byte_24 "ESMD_03139";
BA_ "CI_SLOT_Name" SG_ 2566838922 Bootloader_Id_Byte_24 "SAEatad0200";
BA_ "SPN" SG_ 2566838922 Bootloader_Id_Byte_24 234;
BA_ "CI_FullName" SG_ 2566838922 Bootloader_Id_Byte_25 "Software Identification";
BA_ "CI_ParId" SG_ 2566838922 Bootloader_Id_Byte_25 "ESMD_03139";
BA_ "CI_SLOT_Name" SG_ 2566838922 Bootloader_Id_Byte_25 "SAEatad0200";
BA_ "SPN" SG_ 2566838922 Bootloader_Id_Byte_25 234;
BA_ "CI_FullName" SG_ 2566838922 Bootloader_Id_Byte_26 "Software Identification";
BA_ "CI_ParId" SG_ 2566838922 Bootloader_Id_Byte_26 "ESMD_03139";
BA_ "CI_SLOT_Name" SG_ 2566838922 Bootloader_Id_Byte_26 "SAEatad0200";
BA_ "SPN" SG_ 2566838922 Bootloader_Id_Byte_26 234;
BA_ "CI_FullName" SG_ 2566838922 Bootloader_Id_Byte_27 "Software Identification";
BA_ "CI_ParId" SG_ 2566838922 Bootloader_Id_Byte_27 "ESMD_03139";
BA_ "CI_SLOT_Name" SG_ 2566838922 Bootloader_Id_Byte_27 "SAEatad0200";
BA_ "SPN" SG_ 2566838922 Bootloader_Id_Byte_27 234;
BA_ "CI_FullName" SG_ 2566838922 Bootloader_Id_Byte_28 "Software Identification";
BA_ "CI_ParId" SG_ 2566838922 Bootloader_Id_Byte_28 "ESMD_03139";
BA_ "CI_SLOT_Name" SG_ 2566838922 Bootloader_Id_Byte_28 "SAEatad0200";
BA_ "SPN" SG_ 2566838922 Bootloader_Id_Byte_28 234;
BA_ "CI_FullName" SG_ 2566838922 Bootloader_Id_Byte_29 "Software Identification";
BA_ "CI_ParId" SG_ 2566838922 Bootloader_Id_Byte_29 "ESMD_03139";
BA_ "CI_SLOT_Name" SG_ 2566838922 Bootloader_Id_Byte_29 "SAEatad0200";
BA_ "SPN" SG_ 2566838922 Bootloader_Id_Byte_29 234;
BA_ "CI_FullName" SG_ 2566838922 Bootloader_Id_Byte_30 "Software Identification";
BA_ "CI_ParId" SG_ 2566838922 Bootloader_Id_Byte_30 "ESMD_03139";
BA_ "CI_SLOT_Name" SG_ 2566838922 Bootloader_Id_Byte_30 "SAEatad0200";
BA_ "SPN" SG_ 2566838922 Bootloader_Id_Byte_30 234;
BA_ "CI_FullName" SG_ 2566838922 Bootloader_Id_Byte_31 "Software Identification";
BA_ "CI_ParId" SG_ 2566838922 Bootloader_Id_Byte_31 "ESMD_03139";
BA_ "CI_SLOT_Name" SG_ 2566838922 Bootloader_Id_Byte_31 "SAEatad0200";
BA_ "SPN" SG_ 2566838922 Bootloader_Id_Byte_31 234;
BA_ "CI_FullName" SG_ 2566838922 Bootloader_Id_Byte_32 "Software Identification";
BA_ "CI_ParId" SG_ 2566838922 Bootloader_Id_Byte_32 "ESMD_03139";
BA_ "CI_SLOT_Name" SG_ 2566838922 Bootloader_Id_Byte_32 "SAEatad0200";
BA_ "SPN" SG_ 2566838922 Bootloader_Id_Byte_32 234;
BA_ "CI_FullName" SG_ 2566838922 Bootloader_Id_Byte_33 "Software Identification";
BA_ "CI_ParId" SG_ 2566838922 Bootloader_Id_Byte_33 "ESMD_03139";
BA_ "CI_SLOT_Name" SG_ 2566838922 Bootloader_Id_Byte_33 "SAEatad0200";
BA_ "SPN" SG_ 2566838922 Bootloader_Id_Byte_33 234;
BA_ "CI_FullName" SG_ 2566838922 Bootloader_Id_Byte_34 "Software Identification";
BA_ "CI_ParId" SG_ 2566838922 Bootloader_Id_Byte_34 "ESMD_03139";
BA_ "CI_SLOT_Name" SG_ 2566838922 Bootloader_Id_Byte_34 "SAEatad0200";
BA_ "SPN" SG_ 2566838922 Bootloader_Id_Byte_34 234;
BA_ "CI_FullName" SG_ 2566838922 Bootloader_Id_Byte_35 "Software Identification";
BA_ "CI_ParId" SG_ 2566838922 Bootloader_Id_Byte_35 "ESMD_03139";
BA_ "CI_SLOT_Name" SG_ 2566838922 Bootloader_Id_Byte_35 "SAEatad0200";
BA_ "SPN" SG_ 2566838922 Bootloader_Id_Byte_35 234;
BA_ "CI_FullName" SG_ 2566838922 Bootloader_Id_Byte_36 "Software Identification";
BA_ "CI_ParId" SG_ 2566838922 Bootloader_Id_Byte_36 "ESMD_03139";
BA_ "CI_SLOT_Name" SG_ 2566838922 Bootloader_Id_Byte_36 "SAEatad0200";
BA_ "SPN" SG_ 2566838922 Bootloader_Id_Byte_36 234;
BA_ "CI_FullName" SG_ 2566838922 Bootloader_Id_Byte_37 "Software Identification";
BA_ "CI_ParId" SG_ 2566838922 Bootloader_Id_Byte_37 "ESMD_03139";
BA_ "CI_SLOT_Name" SG_ 2566838922 Bootloader_Id_Byte_37 "SAEatad0200";
BA_ "SPN" SG_ 2566838922 Bootloader_Id_Byte_37 234;
BA_ "CI_FullName" SG_ 2566838922 Bootloader_Id_Byte_38 "Software Identification";
BA_ "CI_ParId" SG_ 2566838922 Bootloader_Id_Byte_38 "ESMD_03139";
BA_ "CI_SLOT_Name" SG_ 2566838922 Bootloader_Id_Byte_38 "SAEatad0200";
BA_ "SPN" SG_ 2566838922 Bootloader_Id_Byte_38 234;
BA_ "CI_FullName" SG_ 2566838922 Bootloader_Id_Byte_39 "Software Identification";
BA_ "CI_ParId" SG_ 2566838922 Bootloader_Id_Byte_39 "ESMD_03139";
BA_ "CI_SLOT_Name" SG_ 2566838922 Bootloader_Id_Byte_39 "SAEatad0200";
BA_ "SPN" SG_ 2566838922 Bootloader_Id_Byte_39 234;
BA_ "CI_FullName" SG_ 2566838922 Bootloader_Id_Enum "Software Identification";
BA_ "CI_ParId" SG_ 2566838922 Bootloader_Id_Enum "ESMD_03139";
BA_ "CI_SLOT_Name" SG_ 2566838922 Bootloader_Id_Enum "SAEbs24";
BA_ "SPN" SG_ 2566838922 Bootloader_Id_Enum 234;
BA_ "CI_FullName" SG_ 2566838922 EndStrng_00 "Software Identification";
BA_ "CI_ParId" SG_ 2566838922 EndStrng_00 "ESMD_21930";
BA_ "CI_SLOT_Name" SG_ 2566838922 EndStrng_00 "SAEatad0200";
BA_ "GenSigStartValue" SG_ 2566838922 EndStrng_00 42;
BA_ "SigType" SG_ 2566838922 EndStrng_00 8;
BA_ "CI_FullName" SG_ 2566838922 EndStrng_01 "Software Identification";
BA_ "CI_ParId" SG_ 2566838922 EndStrng_01 "ESMD_21931";
BA_ "CI_SLOT_Name" SG_ 2566838922 EndStrng_01 "SAEatad0200";
BA_ "GenSigStartValue" SG_ 2566838922 EndStrng_01 42;
BA_ "SigType" SG_ 2566838922 EndStrng_01 8;
BA_ "GenSigAutoGenSnd" SG_ 2566838922 NumSW_IdField 0;
BA_ "GenSigAutoGenDsp" SG_ 2566838922 NumSW_IdField 0;
BA_ "CI_RepetitionComplemented" SG_ 2566838922 NumSW_IdField 2;
BA_ "CI_FullName" SG_ 2566838922 NumSW_IdField "Number of Software Identification Fields";
BA_ "CI_ParId" SG_ 2566838922 NumSW_IdField "ESMD_02746";
BA_ "CI_SLOT_Name" SG_ 2566838922 NumSW_IdField "SAEst01";
BA_ "SPN" SG_ 2566838922 NumSW_IdField 965;
BA_ "SigType" SG_ 2566838922 NumSW_IdField 1;
BA_ "CI_FullName" SG_ 2566838922 Appl_Id "Software Identification";
BA_ "CI_ParId" SG_ 2566838922 Appl_Id "ESMD_03139";
BA_ "CI_SLOT_Name" SG_ 2566838922 Appl_Id "SAEatad0200";
BA_ "SPN" SG_ 2566838922 Appl_Id 234;
BA_ "CI_FullName" SG_ 2566838922 Appl_Id_Byte_01 "Software Identification";
BA_ "CI_ParId" SG_ 2566838922 Appl_Id_Byte_01 "ESMD_03139";
BA_ "CI_SLOT_Name" SG_ 2566838922 Appl_Id_Byte_01 "SAEatad0200";
BA_ "SPN" SG_ 2566838922 Appl_Id_Byte_01 234;
BA_ "CI_FullName" SG_ 2566838922 Appl_Id_Byte_02 "Software Identification";
BA_ "CI_ParId" SG_ 2566838922 Appl_Id_Byte_02 "ESMD_03139";
BA_ "CI_SLOT_Name" SG_ 2566838922 Appl_Id_Byte_02 "SAEatad0200";
BA_ "SPN" SG_ 2566838922 Appl_Id_Byte_02 234;
BA_ "CI_FullName" SG_ 2566838922 Appl_Id_Byte_03 "Software Identification";
BA_ "CI_ParId" SG_ 2566838922 Appl_Id_Byte_03 "ESMD_03139";
BA_ "CI_SLOT_Name" SG_ 2566838922 Appl_Id_Byte_03 "SAEatad0200";
BA_ "SPN" SG_ 2566838922 Appl_Id_Byte_03 234;
BA_ "CI_FullName" SG_ 2566838922 Appl_Id_Byte_04 "Software Identification";
BA_ "CI_ParId" SG_ 2566838922 Appl_Id_Byte_04 "ESMD_03139";
BA_ "CI_SLOT_Name" SG_ 2566838922 Appl_Id_Byte_04 "SAEatad0200";
BA_ "SPN" SG_ 2566838922 Appl_Id_Byte_04 234;
BA_ "CI_FullName" SG_ 2566838922 Appl_Id_Byte_05 "Software Identification";
BA_ "CI_ParId" SG_ 2566838922 Appl_Id_Byte_05 "ESMD_03139";
BA_ "CI_SLOT_Name" SG_ 2566838922 Appl_Id_Byte_05 "SAEatad0200";
BA_ "SPN" SG_ 2566838922 Appl_Id_Byte_05 234;
BA_ "CI_FullName" SG_ 2566838922 Appl_Id_Byte_06 "Software Identification";
BA_ "CI_ParId" SG_ 2566838922 Appl_Id_Byte_06 "ESMD_03139";
BA_ "CI_SLOT_Name" SG_ 2566838922 Appl_Id_Byte_06 "SAEatad0200";
BA_ "SPN" SG_ 2566838922 Appl_Id_Byte_06 234;
BA_ "CI_FullName" SG_ 2566838922 Appl_Id_Byte_07 "Software Identification";
BA_ "CI_ParId" SG_ 2566838922 Appl_Id_Byte_07 "ESMD_03139";
BA_ "CI_SLOT_Name" SG_ 2566838922 Appl_Id_Byte_07 "SAEatad0200";
BA_ "SPN" SG_ 2566838922 Appl_Id_Byte_07 234;
BA_ "CI_FullName" SG_ 2566838922 Appl_Id_Byte_08 "Software Identification";
BA_ "CI_ParId" SG_ 2566838922 Appl_Id_Byte_08 "ESMD_03139";
BA_ "CI_SLOT_Name" SG_ 2566838922 Appl_Id_Byte_08 "SAEatad0200";
BA_ "SPN" SG_ 2566838922 Appl_Id_Byte_08 234;
BA_ "CI_FullName" SG_ 2566838922 Appl_Id_Byte_09 "Software Identification";
BA_ "CI_ParId" SG_ 2566838922 Appl_Id_Byte_09 "ESMD_03139";
BA_ "CI_SLOT_Name" SG_ 2566838922 Appl_Id_Byte_09 "SAEatad0200";
BA_ "SPN" SG_ 2566838922 Appl_Id_Byte_09 234;
BA_ "CI_FullName" SG_ 2566838922 Appl_Id_Byte_10 "Software Identification";
BA_ "CI_ParId" SG_ 2566838922 Appl_Id_Byte_10 "ESMD_03139";
BA_ "CI_SLOT_Name" SG_ 2566838922 Appl_Id_Byte_10 "SAEatad0200";
BA_ "SPN" SG_ 2566838922 Appl_Id_Byte_10 234;
BA_ "CI_FullName" SG_ 2566838922 Appl_Id_Byte_11 "Software Identification";
BA_ "CI_ParId" SG_ 2566838922 Appl_Id_Byte_11 "ESMD_03139";
BA_ "CI_SLOT_Name" SG_ 2566838922 Appl_Id_Byte_11 "SAEatad0200";
BA_ "SPN" SG_ 2566838922 Appl_Id_Byte_11 234;
BA_ "CI_FullName" SG_ 2566838922 Appl_Id_Byte_12 "Software Identification";
BA_ "CI_ParId" SG_ 2566838922 Appl_Id_Byte_12 "ESMD_03139";
BA_ "CI_SLOT_Name" SG_ 2566838922 Appl_Id_Byte_12 "SAEatad0200";
BA_ "SPN" SG_ 2566838922 Appl_Id_Byte_12 234;
BA_ "CI_FullName" SG_ 2566838922 Appl_Id_Byte_13 "Software Identification";
BA_ "CI_ParId" SG_ 2566838922 Appl_Id_Byte_13 "ESMD_03139";
BA_ "CI_SLOT_Name" SG_ 2566838922 Appl_Id_Byte_13 "SAEatad0200";
BA_ "SPN" SG_ 2566838922 Appl_Id_Byte_13 234;
BA_ "CI_FullName" SG_ 2566838922 Appl_Id_Byte_14 "Software Identification";
BA_ "CI_ParId" SG_ 2566838922 Appl_Id_Byte_14 "ESMD_03139";
BA_ "CI_SLOT_Name" SG_ 2566838922 Appl_Id_Byte_14 "SAEatad0200";
BA_ "SPN" SG_ 2566838922 Appl_Id_Byte_14 234;
BA_ "CI_FullName" SG_ 2566838922 Appl_Id_Byte_15 "Software Identification";
BA_ "CI_ParId" SG_ 2566838922 Appl_Id_Byte_15 "ESMD_03139";
BA_ "CI_SLOT_Name" SG_ 2566838922 Appl_Id_Byte_15 "SAEatad0200";
BA_ "SPN" SG_ 2566838922 Appl_Id_Byte_15 234;
BA_ "CI_FullName" SG_ 2566838922 Appl_Id_Byte_16 "Software Identification";
BA_ "CI_ParId" SG_ 2566838922 Appl_Id_Byte_16 "ESMD_03139";
BA_ "CI_SLOT_Name" SG_ 2566838922 Appl_Id_Byte_16 "SAEatad0200";
BA_ "SPN" SG_ 2566838922 Appl_Id_Byte_16 234;
BA_ "CI_FullName" SG_ 2566838922 Appl_Id_Byte_17 "Software Identification";
BA_ "CI_ParId" SG_ 2566838922 Appl_Id_Byte_17 "ESMD_03139";
BA_ "CI_SLOT_Name" SG_ 2566838922 Appl_Id_Byte_17 "SAEatad0200";
BA_ "SPN" SG_ 2566838922 Appl_Id_Byte_17 234;
BA_ "CI_FullName" SG_ 2566838922 Appl_Id_Byte_18 "Software Identification";
BA_ "CI_ParId" SG_ 2566838922 Appl_Id_Byte_18 "ESMD_03139";
BA_ "CI_SLOT_Name" SG_ 2566838922 Appl_Id_Byte_18 "SAEatad0200";
BA_ "SPN" SG_ 2566838922 Appl_Id_Byte_18 234;
BA_ "CI_FullName" SG_ 2566838922 Appl_Id_Byte_19 "Software Identification";
BA_ "CI_ParId" SG_ 2566838922 Appl_Id_Byte_19 "ESMD_03139";
BA_ "CI_SLOT_Name" SG_ 2566838922 Appl_Id_Byte_19 "SAEatad0200";
BA_ "SPN" SG_ 2566838922 Appl_Id_Byte_19 234;
BA_ "CI_FullName" SG_ 2566838922 Appl_Id_Byte_20 "Software Identification";
BA_ "CI_ParId" SG_ 2566838922 Appl_Id_Byte_20 "ESMD_03139";
BA_ "CI_SLOT_Name" SG_ 2566838922 Appl_Id_Byte_20 "SAEatad0200";
BA_ "SPN" SG_ 2566838922 Appl_Id_Byte_20 234;
BA_ "CI_FullName" SG_ 2566838922 Appl_Id_Byte_21 "Software Identification";
BA_ "CI_ParId" SG_ 2566838922 Appl_Id_Byte_21 "ESMD_03139";
BA_ "CI_SLOT_Name" SG_ 2566838922 Appl_Id_Byte_21 "SAEatad0200";
BA_ "SPN" SG_ 2566838922 Appl_Id_Byte_21 234;
BA_ "CI_FullName" SG_ 2566838922 Appl_Id_Byte_22 "Software Identification";
BA_ "CI_ParId" SG_ 2566838922 Appl_Id_Byte_22 "ESMD_03139";
BA_ "CI_SLOT_Name" SG_ 2566838922 Appl_Id_Byte_22 "SAEatad0200";
BA_ "SPN" SG_ 2566838922 Appl_Id_Byte_22 234;
BA_ "CI_FullName" SG_ 2566838922 Appl_Id_Byte_23 "Software Identification";
BA_ "CI_ParId" SG_ 2566838922 Appl_Id_Byte_23 "ESMD_03139";
BA_ "CI_SLOT_Name" SG_ 2566838922 Appl_Id_Byte_23 "SAEatad0200";
BA_ "SPN" SG_ 2566838922 Appl_Id_Byte_23 234;
BA_ "CI_FullName" SG_ 2566854794 EHR_EvNum_4Bit "EHR Valve Number 4 Bit";
BA_ "CI_ParId" SG_ 2566854794 EHR_EvNum_4Bit "ESMD_20935";
BA_ "CI_FullName" SG_ 2566854794 EstExtenFlow "Estimated Extend Flow";
BA_ "CI_ParId" SG_ 2566854794 EstExtenFlow "ESMD_20924";
BA_ "GenSigStartValue" SG_ 2566854794 EstExtenFlow 128;
BA_ "CI_FullName" SG_ 2566854794 EstRetractFlow "Estimated Retract Flow";
BA_ "CI_ParId" SG_ 2566854794 EstRetractFlow "ESMD_20925";
BA_ "GenSigStartValue" SG_ 2566854794 EstRetractFlow 128;
BA_ "CI_FullName" SG_ 2566854794 FailSvng "Fail Saving";
BA_ "CI_ParId" SG_ 2566854794 FailSvng "ESMD_20926";
BA_ "CI_RepetitionNum" SG_ 2566854794 MsgCnt_EHR 1;
BA_ "CI_RepetitionType" SG_ 2566854794 MsgCnt_EHR 3;
BA_ "CI_FullName" SG_ 2566854794 MsgCnt_EHR "Message Counter 2";
BA_ "CI_ParId" SG_ 2566854794 MsgCnt_EHR "ESMD_27907";
BA_ "CI_SLOT_Name" SG_ 2566854794 MsgCnt_EHR "SAEct08";
BA_ "GenSigStartValue" SG_ 2566854794 MsgCnt_EHR 12;
BA_ "SPN" SG_ 2566854794 MsgCnt_EHR 7041;
BA_ "CI_FullName" SG_ 2566854794 OpMode "Operation Mode";
BA_ "CI_ParId" SG_ 2566854794 OpMode "ESMD_20931";
BA_ "SPN_Definition" SG_ 2566854794 SpoolPosition "91";
BA_ "CI_ParId" SG_ 2566854794 SpoolPosition "ESMD_27444";
BA_ "SPN" SG_ 2566854794 SpoolPosition 91;
BA_ "SigType" SG_ 2566854794 SpoolPosition 1;
BA_ "CI_FullName" SG_ 2566866058 EHR_EvNumParamMux_12 "EHR Valve Number Parameter Multiplex 12";
BA_ "CI_ParId" SG_ 2566866058 EHR_EvNumParamMux_12 "ESMD_20916";
BA_ "CI_FullName" SG_ 2566866058 EHR_ParamByte_1 "EHR Parameter Byte 1";
BA_ "CI_ParId" SG_ 2566866058 EHR_ParamByte_1 "ESMD_20901";
BA_ "CI_FullName" SG_ 2566866058 EHR_ParamStsByte_2 "EHR Parameter Status Byte 2";
BA_ "CI_ParId" SG_ 2566866058 EHR_ParamStsByte_2 "ESMD_20903";
BA_ "CI_FullName" SG_ 2566866058 EHR_ParamStsByte_3 "EHR Parameter Status Byte 3";
BA_ "CI_ParId" SG_ 2566866058 EHR_ParamStsByte_3 "ESMD_20904";
BA_ "CI_FullName" SG_ 2566866058 EHR_RmpRndng "EHR Ramp Rounding";
BA_ "CI_ParId" SG_ 2566866058 EHR_RmpRndng "ESMD_20908";
BA_ "CI_FullName" SG_ 2566866058 EHR_ChksumSW "EHR Checksum Software";
BA_ "CI_ParId" SG_ 2566866058 EHR_ChksumSW "ESMD_20886";
BA_ "CI_FullName" SG_ 2566866058 EHR_ChksumStor "EHR Checksum Storage";
BA_ "CI_ParId" SG_ 2566866058 EHR_ChksumStor "ESMD_20887";
BA_ "CI_FullName" SG_ 2566865546 EHR_EvNum "EHR Valve Number";
BA_ "CI_ParId" SG_ 2566865546 EHR_EvNum "ESMD_20914";
BA_ "CI_FullName" SG_ 2566865546 EHR_Err "EHR Fault";
BA_ "CI_ParId" SG_ 2566865546 EHR_Err "ESMD_20893";
BA_ "CI_FullName" SG_ 2566865546 EHR_ErrCod "EHR Fault Code";
BA_ "CI_ParId" SG_ 2566865546 EHR_ErrCod "ESMD_20896";
BA_ "CI_FullName" SG_ 2566865546 EHR_EvTemp "EHR Valve Temperature";
BA_ "CI_ParId" SG_ 2566865546 EHR_EvTemp "ESMD_20923";
BA_ "GenSigStartValue" SG_ 2566865546 EHR_EvTemp 40;
BA_ "CI_FullName" SG_ 2566865546 EHR_InitDiag "EHR Initial Diagnostic";
BA_ "CI_ParId" SG_ 2566865546 EHR_InitDiag "ESMD_20898";
BA_ "CI_FullName" SG_ 2566865546 EHR_SpoolTrav "EHR Spool Travel";
BA_ "CI_ParId" SG_ 2566865546 EHR_SpoolTrav "ESMD_20909";
BA_ "CI_FullName" SG_ 2566865546 EHR_SysId "EHR System Id";
BA_ "CI_ParId" SG_ 2566865546 EHR_SysId "ESMD_20910";
BA_ "GenSigAutoGenSnd" SG_ 2564487562 ProtocCntrlInfo 0;
BA_ "GenSigAutoGenDsp" SG_ 2564487562 ProtocCntrlInfo 0;
BA_ "CI_RepetitionComplemented" SG_ 2564487562 ProtocCntrlInfo 2;
BA_ "CI_FullName" SG_ 2564487562 ProtocCntrlInfo "Protocol Control Information";
BA_ "CI_ParId" SG_ 2564487562 ProtocCntrlInfo "ESMD_02905";
BA_ "GenSigAutoGenSnd" SG_ 2564487562 SingFrameDataLen 0;
BA_ "GenSigAutoGenDsp" SG_ 2564487562 SingFrameDataLen 0;
BA_ "CI_RepetitionComplemented" SG_ 2564487562 SingFrameDataLen 2;
BA_ "CI_FullName" SG_ 2564487562 SingFrameDataLen "Single Frame Data Length";
BA_ "CI_ParId" SG_ 2564487562 SingFrameDataLen "ESMD_03135";
BA_ "GenSigAutoGenSnd" SG_ 2564487562 N1FrameDataLen 0;
BA_ "GenSigAutoGenDsp" SG_ 2564487562 N1FrameDataLen 0;
BA_ "CI_RepetitionComplemented" SG_ 2564487562 N1FrameDataLen 2;
BA_ "CI_FullName" SG_ 2564487562 N1FrameDataLen "First Frame Data Length";
BA_ "CI_ParId" SG_ 2564487562 N1FrameDataLen "ESMD_01962";
BA_ "GenSigAutoGenSnd" SG_ 2564487562 FlowSts 0;
BA_ "GenSigAutoGenDsp" SG_ 2564487562 FlowSts 0;
BA_ "CI_RepetitionComplemented" SG_ 2564487562 FlowSts 2;
BA_ "CI_FullName" SG_ 2564487562 FlowSts "Flow Status";
BA_ "CI_ParId" SG_ 2564487562 FlowSts "ESMD_01968";
BA_ "GenSigAutoGenSnd" SG_ 2564487562 BlkSize 0;
BA_ "GenSigAutoGenDsp" SG_ 2564487562 BlkSize 0;
BA_ "CI_RepetitionComplemented" SG_ 2564487562 BlkSize 2;
BA_ "CI_FullName" SG_ 2564487562 BlkSize "Block Size";
BA_ "CI_ParId" SG_ 2564487562 BlkSize "ESMD_00809";
BA_ "GenSigAutoGenSnd" SG_ 2564487562 SepTime 0;
BA_ "GenSigAutoGenDsp" SG_ 2564487562 SepTime 0;
BA_ "CI_RepetitionComplemented" SG_ 2564487562 SepTime 2;
BA_ "CI_FullName" SG_ 2564487562 SepTime "Separation Time";
BA_ "CI_ParId" SG_ 2564487562 SepTime "ESMD_03113";
BA_ "GenSigAutoGenSnd" SG_ 2564487562 SN 0;
BA_ "GenSigAutoGenDsp" SG_ 2564487562 SN 0;
BA_ "CI_RepetitionComplemented" SG_ 2564487562 SN 2;
BA_ "CI_FullName" SG_ 2564487562 SN "Serial Number";
BA_ "CI_ParId" SG_ 2564487562 SN "ESMD_03138";
BA_ "CI_FullName" SG_ 2566843274 UnitNumPwrUnit "Unit Number (Power Unit)";
BA_ "CI_ParId" SG_ 2566843274 UnitNumPwrUnit "ESMD_03702";
BA_ "CI_SLOT_Name" SG_ 2566843274 UnitNumPwrUnit "SAEatad0200";
BA_ "SPN" SG_ 2566843274 UnitNumPwrUnit 233;
BA_ "CI_FullName" SG_ 2566843274 SN_2_Byte_15 "Serial Number 2";
BA_ "CI_ParId" SG_ 2566843274 SN_2_Byte_15 "ESMD_03115";
BA_ "CI_SLOT_Name" SG_ 2566843274 SN_2_Byte_15 "SAEatad0200";
BA_ "SPN" SG_ 2566843274 SN_2_Byte_15 588;
BA_ "SigType" SG_ 2566843274 SN_2_Byte_15 8;
BA_ "CI_FullName" SG_ 2566843274 SN_2_Byte_14 "Serial Number 2";
BA_ "CI_ParId" SG_ 2566843274 SN_2_Byte_14 "ESMD_03115";
BA_ "CI_SLOT_Name" SG_ 2566843274 SN_2_Byte_14 "SAEatad0200";
BA_ "SPN" SG_ 2566843274 SN_2_Byte_14 588;
BA_ "SigType" SG_ 2566843274 SN_2_Byte_14 8;
BA_ "CI_FullName" SG_ 2566843274 SN_2_Byte_13 "Serial Number 2";
BA_ "CI_ParId" SG_ 2566843274 SN_2_Byte_13 "ESMD_03115";
BA_ "CI_SLOT_Name" SG_ 2566843274 SN_2_Byte_13 "SAEatad0200";
BA_ "SPN" SG_ 2566843274 SN_2_Byte_13 588;
BA_ "SigType" SG_ 2566843274 SN_2_Byte_13 8;
BA_ "CI_FullName" SG_ 2566843274 SN_2_Byte_12 "Serial Number 2";
BA_ "CI_ParId" SG_ 2566843274 SN_2_Byte_12 "ESMD_03115";
BA_ "CI_SLOT_Name" SG_ 2566843274 SN_2_Byte_12 "SAEatad0200";
BA_ "SPN" SG_ 2566843274 SN_2_Byte_12 588;
BA_ "SigType" SG_ 2566843274 SN_2_Byte_12 8;
BA_ "CI_FullName" SG_ 2566843274 SN_2_Byte_11 "Serial Number 2";
BA_ "CI_ParId" SG_ 2566843274 SN_2_Byte_11 "ESMD_03115";
BA_ "CI_SLOT_Name" SG_ 2566843274 SN_2_Byte_11 "SAEatad0200";
BA_ "SPN" SG_ 2566843274 SN_2_Byte_11 588;
BA_ "SigType" SG_ 2566843274 SN_2_Byte_11 8;
BA_ "CI_FullName" SG_ 2566843274 SN_2_Byte_10 "Serial Number 2";
BA_ "CI_ParId" SG_ 2566843274 SN_2_Byte_10 "ESMD_03115";
BA_ "CI_SLOT_Name" SG_ 2566843274 SN_2_Byte_10 "SAEatad0200";
BA_ "SPN" SG_ 2566843274 SN_2_Byte_10 588;
BA_ "SigType" SG_ 2566843274 SN_2_Byte_10 8;
BA_ "CI_FullName" SG_ 2566843274 SN_2_Byte_09 "Serial Number 2";
BA_ "CI_ParId" SG_ 2566843274 SN_2_Byte_09 "ESMD_03115";
BA_ "CI_SLOT_Name" SG_ 2566843274 SN_2_Byte_09 "SAEatad0200";
BA_ "SPN" SG_ 2566843274 SN_2_Byte_09 588;
BA_ "SigType" SG_ 2566843274 SN_2_Byte_09 8;
BA_ "CI_FullName" SG_ 2566843274 SN_2_Byte_08 "Serial Number 2";
BA_ "CI_ParId" SG_ 2566843274 SN_2_Byte_08 "ESMD_03115";
BA_ "CI_SLOT_Name" SG_ 2566843274 SN_2_Byte_08 "SAEatad0200";
BA_ "SPN" SG_ 2566843274 SN_2_Byte_08 588;
BA_ "SigType" SG_ 2566843274 SN_2_Byte_08 8;
BA_ "CI_FullName" SG_ 2566843274 SN_2_Byte_07 "Serial Number 2";
BA_ "CI_ParId" SG_ 2566843274 SN_2_Byte_07 "ESMD_03115";
BA_ "CI_SLOT_Name" SG_ 2566843274 SN_2_Byte_07 "SAEatad0200";
BA_ "SPN" SG_ 2566843274 SN_2_Byte_07 588;
BA_ "SigType" SG_ 2566843274 SN_2_Byte_07 8;
BA_ "CI_FullName" SG_ 2566843274 SN_2_Byte_06 "Serial Number 2";
BA_ "CI_ParId" SG_ 2566843274 SN_2_Byte_06 "ESMD_03115";
BA_ "CI_SLOT_Name" SG_ 2566843274 SN_2_Byte_06 "SAEatad0200";
BA_ "SPN" SG_ 2566843274 SN_2_Byte_06 588;
BA_ "SigType" SG_ 2566843274 SN_2_Byte_06 8;
BA_ "CI_FullName" SG_ 2566843274 SN_2_Byte_05 "Serial Number 2";
BA_ "CI_ParId" SG_ 2566843274 SN_2_Byte_05 "ESMD_03115";
BA_ "CI_SLOT_Name" SG_ 2566843274 SN_2_Byte_05 "SAEatad0200";
BA_ "SPN" SG_ 2566843274 SN_2_Byte_05 588;
BA_ "SigType" SG_ 2566843274 SN_2_Byte_05 8;
BA_ "CI_FullName" SG_ 2566843274 SN_2_Byte_04 "Serial Number 2";
BA_ "CI_ParId" SG_ 2566843274 SN_2_Byte_04 "ESMD_03115";
BA_ "CI_SLOT_Name" SG_ 2566843274 SN_2_Byte_04 "SAEatad0200";
BA_ "SPN" SG_ 2566843274 SN_2_Byte_04 588;
BA_ "SigType" SG_ 2566843274 SN_2_Byte_04 8;
BA_ "CI_FullName" SG_ 2566843274 SN_2_Byte_03 "Serial Number 2";
BA_ "CI_ParId" SG_ 2566843274 SN_2_Byte_03 "ESMD_03115";
BA_ "CI_SLOT_Name" SG_ 2566843274 SN_2_Byte_03 "SAEatad0200";
BA_ "SPN" SG_ 2566843274 SN_2_Byte_03 588;
BA_ "SigType" SG_ 2566843274 SN_2_Byte_03 8;
BA_ "CI_FullName" SG_ 2566843274 SN_2_Byte_02 "Serial Number 2";
BA_ "CI_ParId" SG_ 2566843274 SN_2_Byte_02 "ESMD_03115";
BA_ "CI_SLOT_Name" SG_ 2566843274 SN_2_Byte_02 "SAEatad0200";
BA_ "SPN" SG_ 2566843274 SN_2_Byte_02 588;
BA_ "SigType" SG_ 2566843274 SN_2_Byte_02 8;
BA_ "CI_FullName" SG_ 2566843274 SN_2_Byte_01 "Serial Number 2";
BA_ "CI_ParId" SG_ 2566843274 SN_2_Byte_01 "ESMD_03115";
BA_ "CI_SLOT_Name" SG_ 2566843274 SN_2_Byte_01 "SAEatad0200";
BA_ "SPN" SG_ 2566843274 SN_2_Byte_01 588;
BA_ "SigType" SG_ 2566843274 SN_2_Byte_01 8;
BA_ "CI_FullName" SG_ 2566843274 SN_2 "Serial Number 2";
BA_ "CI_ParId" SG_ 2566843274 SN_2 "ESMD_03115";
BA_ "CI_SLOT_Name" SG_ 2566843274 SN_2 "SAEatad0200";
BA_ "SPN" SG_ 2566843274 SN_2 588;
BA_ "CI_FullName" SG_ 2566843274 Mdl_Byte_08 "Model";
BA_ "CI_ParId" SG_ 2566843274 Mdl_Byte_08 "ESMD_02715";
BA_ "CI_SLOT_Name" SG_ 2566843274 Mdl_Byte_08 "SAEatad0200";
BA_ "SPN" SG_ 2566843274 Mdl_Byte_08 587;
BA_ "SigType" SG_ 2566843274 Mdl_Byte_08 8;
BA_ "CI_FullName" SG_ 2566843274 Mdl_Byte_07 "Model";
BA_ "CI_ParId" SG_ 2566843274 Mdl_Byte_07 "ESMD_02715";
BA_ "CI_SLOT_Name" SG_ 2566843274 Mdl_Byte_07 "SAEatad0200";
BA_ "SPN" SG_ 2566843274 Mdl_Byte_07 587;
BA_ "SigType" SG_ 2566843274 Mdl_Byte_07 8;
BA_ "CI_FullName" SG_ 2566843274 Mdl_Byte_06 "Model";
BA_ "CI_ParId" SG_ 2566843274 Mdl_Byte_06 "ESMD_02715";
BA_ "CI_SLOT_Name" SG_ 2566843274 Mdl_Byte_06 "SAEatad0200";
BA_ "SPN" SG_ 2566843274 Mdl_Byte_06 587;
BA_ "SigType" SG_ 2566843274 Mdl_Byte_06 8;
BA_ "CI_FullName" SG_ 2566843274 Mdl_Byte_05 "Model";
BA_ "CI_ParId" SG_ 2566843274 Mdl_Byte_05 "ESMD_02715";
BA_ "CI_SLOT_Name" SG_ 2566843274 Mdl_Byte_05 "SAEatad0200";
BA_ "SPN" SG_ 2566843274 Mdl_Byte_05 587;
BA_ "SigType" SG_ 2566843274 Mdl_Byte_05 8;
BA_ "CI_FullName" SG_ 2566843274 Mdl_Byte_04 "Model";
BA_ "CI_ParId" SG_ 2566843274 Mdl_Byte_04 "ESMD_02715";
BA_ "CI_SLOT_Name" SG_ 2566843274 Mdl_Byte_04 "SAEatad0200";
BA_ "SPN" SG_ 2566843274 Mdl_Byte_04 587;
BA_ "SigType" SG_ 2566843274 Mdl_Byte_04 8;
BA_ "CI_FullName" SG_ 2566843274 Mdl_Byte_03 "Model";
BA_ "CI_ParId" SG_ 2566843274 Mdl_Byte_03 "ESMD_02715";
BA_ "CI_SLOT_Name" SG_ 2566843274 Mdl_Byte_03 "SAEatad0200";
BA_ "SPN" SG_ 2566843274 Mdl_Byte_03 587;
BA_ "SigType" SG_ 2566843274 Mdl_Byte_03 8;
BA_ "CI_FullName" SG_ 2566843274 Mdl_Byte_02 "Model";
BA_ "CI_ParId" SG_ 2566843274 Mdl_Byte_02 "ESMD_02715";
BA_ "CI_SLOT_Name" SG_ 2566843274 Mdl_Byte_02 "SAEatad0200";
BA_ "SPN" SG_ 2566843274 Mdl_Byte_02 587;
BA_ "SigType" SG_ 2566843274 Mdl_Byte_02 8;
BA_ "CI_FullName" SG_ 2566843274 Mdl_Byte_01 "Model";
BA_ "CI_ParId" SG_ 2566843274 Mdl_Byte_01 "ESMD_02715";
BA_ "CI_SLOT_Name" SG_ 2566843274 Mdl_Byte_01 "SAEatad0200";
BA_ "SPN" SG_ 2566843274 Mdl_Byte_01 587;
BA_ "SigType" SG_ 2566843274 Mdl_Byte_01 8;
BA_ "CI_FullName" SG_ 2566843274 Make "Make";
BA_ "CI_ParId" SG_ 2566843274 Make "ESMD_02671";
BA_ "CI_SLOT_Name" SG_ 2566843274 Make "SAEatad0005";
BA_ "SPN" SG_ 2566843274 Make 586;
BA_ "CI_FullName" SG_ 2566843274 Mdl "Model";
BA_ "CI_ParId" SG_ 2566843274 Mdl "ESMD_02715";
BA_ "CI_SLOT_Name" SG_ 2566843274 Mdl "SAEatad0200";
BA_ "SPN" SG_ 2566843274 Mdl 587;
BA_ "CI_FullName" SG_ 2565799818 Rsrvd_1Bit "Reserved 1 Bit";
BA_ "CI_ParId" SG_ 2565799818 Rsrvd_1Bit "ESMD_23062";
BA_ "GenSigAutoGenSnd" SG_ 2565799818 IdNum 0;
BA_ "GenSigAutoGenDsp" SG_ 2565799818 IdNum 0;
BA_ "CI_RepetitionComplemented" SG_ 2565799818 IdNum 2;
BA_ "CI_FullName" SG_ 2565799818 IdNum "Identity Number";
BA_ "CI_ParId" SG_ 2565799818 IdNum "ESMD_08726";
BA_ "SPN" SG_ 2565799818 IdNum 2837;
BA_ "GenSigAutoGenSnd" SG_ 2565799818 ManufctCod 0;
BA_ "GenSigAutoGenDsp" SG_ 2565799818 ManufctCod 0;
BA_ "CI_RepetitionComplemented" SG_ 2565799818 ManufctCod 2;
BA_ "CI_FullName" SG_ 2565799818 ManufctCod "Manufacturer Code";
BA_ "CI_ParId" SG_ 2565799818 ManufctCod "ESMD_08852";
BA_ "SPN" SG_ 2565799818 ManufctCod 2838;
BA_ "SigType" SG_ 2565799818 ManufctCod 1;
BA_ "GenSigAutoGenSnd" SG_ 2565799818 ECU_Inst 0;
BA_ "GenSigAutoGenDsp" SG_ 2565799818 ECU_Inst 0;
BA_ "CI_RepetitionComplemented" SG_ 2565799818 ECU_Inst 2;
BA_ "CI_FullName" SG_ 2565799818 ECU_Inst "ECU Instance";
BA_ "CI_ParId" SG_ 2565799818 ECU_Inst "ESMD_08387";
BA_ "SPN" SG_ 2565799818 ECU_Inst 2840;
BA_ "GenSigAutoGenSnd" SG_ 2565799818 FunctInst 0;
BA_ "GenSigAutoGenDsp" SG_ 2565799818 FunctInst 0;
BA_ "CI_RepetitionComplemented" SG_ 2565799818 FunctInst 2;
BA_ "CI_FullName" SG_ 2565799818 FunctInst "Function Instance";
BA_ "CI_ParId" SG_ 2565799818 FunctInst "ESMD_08670";
BA_ "SPN" SG_ 2565799818 FunctInst 2839;
BA_ "GenSigAutoGenSnd" SG_ 2565799818 Funct 0;
BA_ "GenSigAutoGenDsp" SG_ 2565799818 Funct 0;
BA_ "CI_RepetitionComplemented" SG_ 2565799818 Funct 2;
BA_ "CI_FullName" SG_ 2565799818 Funct "Function";
BA_ "CI_ParId" SG_ 2565799818 Funct "ESMD_08663";
BA_ "SPN" SG_ 2565799818 Funct 2841;
BA_ "GenSigAutoGenSnd" SG_ 2565799818 IndstryGrp 0;
BA_ "GenSigAutoGenDsp" SG_ 2565799818 IndstryGrp 0;
BA_ "CI_RepetitionComplemented" SG_ 2565799818 IndstryGrp 2;
BA_ "CI_FullName" SG_ 2565799818 IndstryGrp "Industry Group";
BA_ "CI_ParId" SG_ 2565799818 IndstryGrp "ESMD_02136";
BA_ "SPN" SG_ 2565799818 IndstryGrp 2846;
BA_ "GenSigAutoGenSnd" SG_ 2565799818 VehSys 0;
BA_ "GenSigAutoGenDsp" SG_ 2565799818 VehSys 0;
BA_ "CI_RepetitionComplemented" SG_ 2565799818 VehSys 2;
BA_ "CI_FullName" SG_ 2565799818 VehSys "Vehicle system";
BA_ "CI_ParId" SG_ 2565799818 VehSys "ESMD_16375";
BA_ "SPN" SG_ 2565799818 VehSys 2842;
BA_ "GenSigAutoGenSnd" SG_ 2565799818 VehSysInst 0;
BA_ "GenSigAutoGenDsp" SG_ 2565799818 VehSysInst 0;
BA_ "CI_RepetitionComplemented" SG_ 2565799818 VehSysInst 2;
BA_ "CI_FullName" SG_ 2565799818 VehSysInst "Vehicle System Instance";
BA_ "CI_ParId" SG_ 2565799818 VehSysInst "ESMD_09571";
BA_ "SPN" SG_ 2565799818 VehSysInst 2843;
BA_ "GenSigAutoGenSnd" SG_ 2565799818 ArbAddrCap 0;
BA_ "GenSigAutoGenDsp" SG_ 2565799818 ArbAddrCap 0;
BA_ "CI_RepetitionComplemented" SG_ 2565799818 ArbAddrCap 2;
BA_ "CI_FullName" SG_ 2565799818 ArbAddrCap "Arbitrary Address Capable";
BA_ "CI_ParId" SG_ 2565799818 ArbAddrCap "ESMD_08115";
BA_ "SPN" SG_ 2565799818 ArbAddrCap 2844;
BA_ "CI_RepetitionNum" SG_ 2566871586 MsgCnt_EHR 1;
BA_ "CI_RepetitionType" SG_ 2566871586 MsgCnt_EHR 3;
BA_ "CI_FullName" SG_ 2566871586 MsgCnt_EHR "Message Counter 2";
BA_ "CI_ParId" SG_ 2566871586 MsgCnt_EHR "ESMD_27907";
BA_ "CI_SLOT_Name" SG_ 2566871586 MsgCnt_EHR "SAEct08";
BA_ "GenSigStartValue" SG_ 2566871586 MsgCnt_EHR 12;
BA_ "SPN" SG_ 2566871586 MsgCnt_EHR 7041;
BA_ "CI_FullName" SG_ 2566871586 EHR_EvNum "EHR Valve Number";
BA_ "CI_ParId" SG_ 2566871586 EHR_EvNum "ESMD_20914";
BA_ "CI_FullName" SG_ 2566871586 EHR_FailSafe "EHR Fail safe";
BA_ "CI_ParId" SG_ 2566871586 EHR_FailSafe "ESMD_20892";
BA_ "CI_FullName" SG_ 2566871586 EHR_CntrlSts "EHR Control State";
BA_ "CI_ParId" SG_ 2566871586 EHR_CntrlSts "ESMD_20888";
BA_ "CI_FullName" SG_ 2566871586 EHR_EvTemp "EHR Valve Temperature";
BA_ "CI_ParId" SG_ 2566871586 EHR_EvTemp "ESMD_20923";
BA_ "GenSigStartValue" SG_ 2566871586 EHR_EvTemp 40;
BA_ "CI_FullName" SG_ 2566871586 EHR_EvFlow "EHR Valve Flow";
BA_ "CI_ParId" SG_ 2566871586 EHR_EvFlow "ESMD_20911";
BA_ "CI_FullName" SG_ 2566871586 EHR_Op_2 "EHR Operation 2";
BA_ "CI_ParId" SG_ 2566871586 EHR_Op_2 "ESMD_20900";
BA_ "CI_FullName" SG_ 2566871586 EHR_Op_1 "EHR Operation 1";
BA_ "CI_ParId" SG_ 2566871586 EHR_Op_1 "ESMD_20899";
BA_ "CI_FullName" SG_ 2566871586 EHR_DynRmpTime "EHR Dynamic Ramp Time";
BA_ "CI_ParId" SG_ 2566871586 EHR_DynRmpTime "ESMD_20891";
BA_ "CI_FullName" SG_ 2566871586 EHR_CrvShp "EHR Curve Shape";
BA_ "CI_ParId" SG_ 2566871586 EHR_CrvShp "ESMD_20890";
BA_ "CI_FullName" SG_ 2566871586 EHR_CrvGrad "EHR Curve Gradient";
BA_ "CI_ParId" SG_ 2566871586 EHR_CrvGrad "ESMD_20889";
BA_ "CI_FullName" SG_ 2566871586 EHR_Init "EHR Initial";
BA_ "CI_ParId" SG_ 2566871586 EHR_Init "ESMD_20897";
BA_ "CI_FullName" SG_ 2566843265 UnitNumPwrUnit "Unit Number (Power Unit)";
BA_ "CI_ParId" SG_ 2566843265 UnitNumPwrUnit "ESMD_03702";
BA_ "CI_SLOT_Name" SG_ 2566843265 UnitNumPwrUnit "SAEatad0200";
BA_ "SPN" SG_ 2566843265 UnitNumPwrUnit 233;
BA_ "CI_FullName" SG_ 2566843265 SN_2_Byte_15 "Serial Number 2";
BA_ "CI_ParId" SG_ 2566843265 SN_2_Byte_15 "ESMD_03115";
BA_ "CI_SLOT_Name" SG_ 2566843265 SN_2_Byte_15 "SAEatad0200";
BA_ "SPN" SG_ 2566843265 SN_2_Byte_15 588;
BA_ "SigType" SG_ 2566843265 SN_2_Byte_15 8;
BA_ "CI_FullName" SG_ 2566843265 SN_2_Byte_14 "Serial Number 2";
BA_ "CI_ParId" SG_ 2566843265 SN_2_Byte_14 "ESMD_03115";
BA_ "CI_SLOT_Name" SG_ 2566843265 SN_2_Byte_14 "SAEatad0200";
BA_ "SPN" SG_ 2566843265 SN_2_Byte_14 588;
BA_ "SigType" SG_ 2566843265 SN_2_Byte_14 8;
BA_ "CI_FullName" SG_ 2566843265 SN_2_Byte_13 "Serial Number 2";
BA_ "CI_ParId" SG_ 2566843265 SN_2_Byte_13 "ESMD_03115";
BA_ "CI_SLOT_Name" SG_ 2566843265 SN_2_Byte_13 "SAEatad0200";
BA_ "SPN" SG_ 2566843265 SN_2_Byte_13 588;
BA_ "SigType" SG_ 2566843265 SN_2_Byte_13 8;
BA_ "CI_FullName" SG_ 2566843265 SN_2_Byte_12 "Serial Number 2";
BA_ "CI_ParId" SG_ 2566843265 SN_2_Byte_12 "ESMD_03115";
BA_ "CI_SLOT_Name" SG_ 2566843265 SN_2_Byte_12 "SAEatad0200";
BA_ "SPN" SG_ 2566843265 SN_2_Byte_12 588;
BA_ "SigType" SG_ 2566843265 SN_2_Byte_12 8;
BA_ "CI_FullName" SG_ 2566843265 SN_2_Byte_11 "Serial Number 2";
BA_ "CI_ParId" SG_ 2566843265 SN_2_Byte_11 "ESMD_03115";
BA_ "CI_SLOT_Name" SG_ 2566843265 SN_2_Byte_11 "SAEatad0200";
BA_ "SPN" SG_ 2566843265 SN_2_Byte_11 588;
BA_ "SigType" SG_ 2566843265 SN_2_Byte_11 8;
BA_ "CI_FullName" SG_ 2566843265 SN_2_Byte_10 "Serial Number 2";
BA_ "CI_ParId" SG_ 2566843265 SN_2_Byte_10 "ESMD_03115";
BA_ "CI_SLOT_Name" SG_ 2566843265 SN_2_Byte_10 "SAEatad0200";
BA_ "SPN" SG_ 2566843265 SN_2_Byte_10 588;
BA_ "SigType" SG_ 2566843265 SN_2_Byte_10 8;
BA_ "CI_FullName" SG_ 2566843265 SN_2_Byte_09 "Serial Number 2";
BA_ "CI_ParId" SG_ 2566843265 SN_2_Byte_09 "ESMD_03115";
BA_ "CI_SLOT_Name" SG_ 2566843265 SN_2_Byte_09 "SAEatad0200";
BA_ "SPN" SG_ 2566843265 SN_2_Byte_09 588;
BA_ "SigType" SG_ 2566843265 SN_2_Byte_09 8;
BA_ "CI_FullName" SG_ 2566843265 SN_2_Byte_08 "Serial Number 2";
BA_ "CI_ParId" SG_ 2566843265 SN_2_Byte_08 "ESMD_03115";
BA_ "CI_SLOT_Name" SG_ 2566843265 SN_2_Byte_08 "SAEatad0200";
BA_ "SPN" SG_ 2566843265 SN_2_Byte_08 588;
BA_ "SigType" SG_ 2566843265 SN_2_Byte_08 8;
BA_ "CI_FullName" SG_ 2566843265 SN_2_Byte_07 "Serial Number 2";
BA_ "CI_ParId" SG_ 2566843265 SN_2_Byte_07 "ESMD_03115";
BA_ "CI_SLOT_Name" SG_ 2566843265 SN_2_Byte_07 "SAEatad0200";
BA_ "SPN" SG_ 2566843265 SN_2_Byte_07 588;
BA_ "SigType" SG_ 2566843265 SN_2_Byte_07 8;
BA_ "CI_FullName" SG_ 2566843265 SN_2_Byte_06 "Serial Number 2";
BA_ "CI_ParId" SG_ 2566843265 SN_2_Byte_06 "ESMD_03115";
BA_ "CI_SLOT_Name" SG_ 2566843265 SN_2_Byte_06 "SAEatad0200";
BA_ "SPN" SG_ 2566843265 SN_2_Byte_06 588;
BA_ "SigType" SG_ 2566843265 SN_2_Byte_06 8;
BA_ "CI_FullName" SG_ 2566843265 SN_2_Byte_05 "Serial Number 2";
BA_ "CI_ParId" SG_ 2566843265 SN_2_Byte_05 "ESMD_03115";
BA_ "CI_SLOT_Name" SG_ 2566843265 SN_2_Byte_05 "SAEatad0200";
BA_ "SPN" SG_ 2566843265 SN_2_Byte_05 588;
BA_ "SigType" SG_ 2566843265 SN_2_Byte_05 8;
BA_ "CI_FullName" SG_ 2566843265 SN_2_Byte_04 "Serial Number 2";
BA_ "CI_ParId" SG_ 2566843265 SN_2_Byte_04 "ESMD_03115";
BA_ "CI_SLOT_Name" SG_ 2566843265 SN_2_Byte_04 "SAEatad0200";
BA_ "SPN" SG_ 2566843265 SN_2_Byte_04 588;
BA_ "SigType" SG_ 2566843265 SN_2_Byte_04 8;
BA_ "CI_FullName" SG_ 2566843265 SN_2_Byte_03 "Serial Number 2";
BA_ "CI_ParId" SG_ 2566843265 SN_2_Byte_03 "ESMD_03115";
BA_ "CI_SLOT_Name" SG_ 2566843265 SN_2_Byte_03 "SAEatad0200";
BA_ "SPN" SG_ 2566843265 SN_2_Byte_03 588;
BA_ "SigType" SG_ 2566843265 SN_2_Byte_03 8;
BA_ "CI_FullName" SG_ 2566843265 SN_2_Byte_02 "Serial Number 2";
BA_ "CI_ParId" SG_ 2566843265 SN_2_Byte_02 "ESMD_03115";
BA_ "CI_SLOT_Name" SG_ 2566843265 SN_2_Byte_02 "SAEatad0200";
BA_ "SPN" SG_ 2566843265 SN_2_Byte_02 588;
BA_ "SigType" SG_ 2566843265 SN_2_Byte_02 8;
BA_ "CI_FullName" SG_ 2566843265 SN_2_Byte_01 "Serial Number 2";
BA_ "CI_ParId" SG_ 2566843265 SN_2_Byte_01 "ESMD_03115";
BA_ "CI_SLOT_Name" SG_ 2566843265 SN_2_Byte_01 "SAEatad0200";
BA_ "SPN" SG_ 2566843265 SN_2_Byte_01 588;
BA_ "SigType" SG_ 2566843265 SN_2_Byte_01 8;
BA_ "CI_FullName" SG_ 2566843265 SN_2 "Serial Number 2";
BA_ "CI_ParId" SG_ 2566843265 SN_2 "ESMD_03115";
BA_ "CI_SLOT_Name" SG_ 2566843265 SN_2 "SAEatad0200";
BA_ "SPN" SG_ 2566843265 SN_2 588;
BA_ "CI_FullName" SG_ 2566843265 Mdl_Byte_08 "Model";
BA_ "CI_ParId" SG_ 2566843265 Mdl_Byte_08 "ESMD_02715";
BA_ "CI_SLOT_Name" SG_ 2566843265 Mdl_Byte_08 "SAEatad0200";
BA_ "SPN" SG_ 2566843265 Mdl_Byte_08 587;
BA_ "SigType" SG_ 2566843265 Mdl_Byte_08 8;
BA_ "CI_FullName" SG_ 2566843265 Mdl_Byte_07 "Model";
BA_ "CI_ParId" SG_ 2566843265 Mdl_Byte_07 "ESMD_02715";
BA_ "CI_SLOT_Name" SG_ 2566843265 Mdl_Byte_07 "SAEatad0200";
BA_ "SPN" SG_ 2566843265 Mdl_Byte_07 587;
BA_ "SigType" SG_ 2566843265 Mdl_Byte_07 8;
BA_ "CI_FullName" SG_ 2566843265 Mdl_Byte_06 "Model";
BA_ "CI_ParId" SG_ 2566843265 Mdl_Byte_06 "ESMD_02715";
BA_ "CI_SLOT_Name" SG_ 2566843265 Mdl_Byte_06 "SAEatad0200";
BA_ "SPN" SG_ 2566843265 Mdl_Byte_06 587;
BA_ "SigType" SG_ 2566843265 Mdl_Byte_06 8;
BA_ "CI_FullName" SG_ 2566843265 Mdl_Byte_05 "Model";
BA_ "CI_ParId" SG_ 2566843265 Mdl_Byte_05 "ESMD_02715";
BA_ "CI_SLOT_Name" SG_ 2566843265 Mdl_Byte_05 "SAEatad0200";
BA_ "SPN" SG_ 2566843265 Mdl_Byte_05 587;
BA_ "SigType" SG_ 2566843265 Mdl_Byte_05 8;
BA_ "CI_FullName" SG_ 2566843265 Mdl_Byte_04 "Model";
BA_ "CI_ParId" SG_ 2566843265 Mdl_Byte_04 "ESMD_02715";
BA_ "CI_SLOT_Name" SG_ 2566843265 Mdl_Byte_04 "SAEatad0200";
BA_ "SPN" SG_ 2566843265 Mdl_Byte_04 587;
BA_ "SigType" SG_ 2566843265 Mdl_Byte_04 8;
BA_ "CI_FullName" SG_ 2566843265 Mdl_Byte_03 "Model";
BA_ "CI_ParId" SG_ 2566843265 Mdl_Byte_03 "ESMD_02715";
BA_ "CI_SLOT_Name" SG_ 2566843265 Mdl_Byte_03 "SAEatad0200";
BA_ "SPN" SG_ 2566843265 Mdl_Byte_03 587;
BA_ "SigType" SG_ 2566843265 Mdl_Byte_03 8;
BA_ "CI_FullName" SG_ 2566843265 Mdl_Byte_02 "Model";
BA_ "CI_ParId" SG_ 2566843265 Mdl_Byte_02 "ESMD_02715";
BA_ "CI_SLOT_Name" SG_ 2566843265 Mdl_Byte_02 "SAEatad0200";
BA_ "SPN" SG_ 2566843265 Mdl_Byte_02 587;
BA_ "SigType" SG_ 2566843265 Mdl_Byte_02 8;
BA_ "CI_FullName" SG_ 2566843265 Mdl_Byte_01 "Model";
BA_ "CI_ParId" SG_ 2566843265 Mdl_Byte_01 "ESMD_02715";
BA_ "CI_SLOT_Name" SG_ 2566843265 Mdl_Byte_01 "SAEatad0200";
BA_ "SPN" SG_ 2566843265 Mdl_Byte_01 587;
BA_ "SigType" SG_ 2566843265 Mdl_Byte_01 8;
BA_ "CI_FullName" SG_ 2566843265 Make "Make";
BA_ "CI_ParId" SG_ 2566843265 Make "ESMD_02671";
BA_ "CI_SLOT_Name" SG_ 2566843265 Make "SAEatad0005";
BA_ "SPN" SG_ 2566843265 Make 586;
BA_ "CI_FullName" SG_ 2566843265 Mdl "Model";
BA_ "CI_ParId" SG_ 2566843265 Mdl "ESMD_02715";
BA_ "CI_SLOT_Name" SG_ 2566843265 Mdl "SAEatad0200";
BA_ "SPN" SG_ 2566843265 Mdl 587;
BA_ "GenSigAutoGenSnd" SG_ 2564487553 SepTime 0;
BA_ "GenSigAutoGenDsp" SG_ 2564487553 SepTime 0;
BA_ "CI_RepetitionComplemented" SG_ 2564487553 SepTime 2;
BA_ "CI_FullName" SG_ 2564487553 SepTime "Separation Time";
BA_ "CI_ParId" SG_ 2564487553 SepTime "ESMD_03113";
BA_ "GenSigAutoGenSnd" SG_ 2564487553 SingFrameDataLen 0;
BA_ "GenSigAutoGenDsp" SG_ 2564487553 SingFrameDataLen 0;
BA_ "CI_RepetitionComplemented" SG_ 2564487553 SingFrameDataLen 2;
BA_ "CI_FullName" SG_ 2564487553 SingFrameDataLen "Single Frame Data Length";
BA_ "CI_ParId" SG_ 2564487553 SingFrameDataLen "ESMD_03135";
BA_ "GenSigAutoGenSnd" SG_ 2564487553 N1FrameDataLen 0;
BA_ "GenSigAutoGenDsp" SG_ 2564487553 N1FrameDataLen 0;
BA_ "CI_RepetitionComplemented" SG_ 2564487553 N1FrameDataLen 2;
BA_ "CI_FullName" SG_ 2564487553 N1FrameDataLen "First Frame Data Length";
BA_ "CI_ParId" SG_ 2564487553 N1FrameDataLen "ESMD_01962";
BA_ "GenSigAutoGenSnd" SG_ 2564487553 BlkSize 0;
BA_ "GenSigAutoGenDsp" SG_ 2564487553 BlkSize 0;
BA_ "CI_RepetitionComplemented" SG_ 2564487553 BlkSize 2;
BA_ "CI_FullName" SG_ 2564487553 BlkSize "Block Size";
BA_ "CI_ParId" SG_ 2564487553 BlkSize "ESMD_00809";
BA_ "GenSigAutoGenSnd" SG_ 2564487553 FlowSts 0;
BA_ "GenSigAutoGenDsp" SG_ 2564487553 FlowSts 0;
BA_ "CI_RepetitionComplemented" SG_ 2564487553 FlowSts 2;
BA_ "CI_FullName" SG_ 2564487553 FlowSts "Flow Status";
BA_ "CI_ParId" SG_ 2564487553 FlowSts "ESMD_01968";
BA_ "GenSigAutoGenSnd" SG_ 2564487553 SN 0;
BA_ "GenSigAutoGenDsp" SG_ 2564487553 SN 0;
BA_ "CI_RepetitionComplemented" SG_ 2564487553 SN 2;
BA_ "CI_FullName" SG_ 2564487553 SN "Serial Number";
BA_ "CI_ParId" SG_ 2564487553 SN "ESMD_03138";
BA_ "GenSigAutoGenSnd" SG_ 2564487553 ProtocCntrlInfo 0;
BA_ "GenSigAutoGenDsp" SG_ 2564487553 ProtocCntrlInfo 0;
BA_ "CI_RepetitionComplemented" SG_ 2564487553 ProtocCntrlInfo 2;
BA_ "CI_FullName" SG_ 2564487553 ProtocCntrlInfo "Protocol Control Information";
BA_ "CI_ParId" SG_ 2564487553 ProtocCntrlInfo "ESMD_02905";
BA_ "GenSigAutoGenSnd" SG_ 2632777721 CByteTPCM 0;
BA_ "GenSigAutoGenDsp" SG_ 2632777721 CByteTPCM 0;
BA_ "CI_RepetitionComplemented" SG_ 2632777721 CByteTPCM 2;
BA_ "CI_FullName" SG_ 2632777721 CByteTPCM "Control Byte (TP.CM)";
BA_ "CI_ParId" SG_ 2632777721 CByteTPCM "ESMD_00941";
BA_ "SPN" SG_ 2632777721 CByteTPCM 2556;
BA_ "GenSigAutoGenSnd" SG_ 2632777721 TotMsgSizeTPCM_RTS 0;
BA_ "GenSigAutoGenDsp" SG_ 2632777721 TotMsgSizeTPCM_RTS 0;
BA_ "CI_RepetitionComplemented" SG_ 2632777721 TotMsgSizeTPCM_RTS 2;
BA_ "CI_FullName" SG_ 2632777721 TotMsgSizeTPCM_RTS "Total Message Size (TP.CM_RTS)";
BA_ "CI_ParId" SG_ 2632777721 TotMsgSizeTPCM_RTS "ESMD_03431";
BA_ "SPN" SG_ 2632777721 TotMsgSizeTPCM_RTS 2557;
BA_ "GenSigAutoGenSnd" SG_ 2632777721 TotNumPktTPCM_RTS 0;
BA_ "GenSigAutoGenDsp" SG_ 2632777721 TotNumPktTPCM_RTS 0;
BA_ "CI_RepetitionComplemented" SG_ 2632777721 TotNumPktTPCM_RTS 2;
BA_ "CI_FullName" SG_ 2632777721 TotNumPktTPCM_RTS "Total Number of Packets (TP.CM_RTS)";
BA_ "CI_ParId" SG_ 2632777721 TotNumPktTPCM_RTS "ESMD_03434";
BA_ "SPN" SG_ 2632777721 TotNumPktTPCM_RTS 2558;
BA_ "GenSigAutoGenSnd" SG_ 2632777721 MaxNumPktTPCM_RTS 0;
BA_ "GenSigAutoGenDsp" SG_ 2632777721 MaxNumPktTPCM_RTS 0;
BA_ "CI_RepetitionComplemented" SG_ 2632777721 MaxNumPktTPCM_RTS 2;
BA_ "CI_FullName" SG_ 2632777721 MaxNumPktTPCM_RTS "Maximum Number of Packets (TP.CM_RTS)";
BA_ "CI_ParId" SG_ 2632777721 MaxNumPktTPCM_RTS "ESMD_02684";
BA_ "SPN" SG_ 2632777721 MaxNumPktTPCM_RTS 2559;
BA_ "GenSigAutoGenSnd" SG_ 2632777721 PGN_PktMsgTPCM_RTS 0;
BA_ "GenSigAutoGenDsp" SG_ 2632777721 PGN_PktMsgTPCM_RTS 0;
BA_ "CI_RepetitionComplemented" SG_ 2632777721 PGN_PktMsgTPCM_RTS 2;
BA_ "CI_FullName" SG_ 2632777721 PGN_PktMsgTPCM_RTS "Parameter Group Number of the packeted message (TP.CM_RTS)";
BA_ "CI_ParId" SG_ 2632777721 PGN_PktMsgTPCM_RTS "ESMD_02869";
BA_ "SPN" SG_ 2632777721 PGN_PktMsgTPCM_RTS 2560;
BA_ "GenSigAutoGenSnd" SG_ 2632777721 NumPktSentTPCM_CTS 0;
BA_ "GenSigAutoGenDsp" SG_ 2632777721 NumPktSentTPCM_CTS 0;
BA_ "CI_RepetitionComplemented" SG_ 2632777721 NumPktSentTPCM_CTS 2;
BA_ "CI_FullName" SG_ 2632777721 NumPktSentTPCM_CTS "Number of Packets that can be sent (TP.CM_CTS)";
BA_ "CI_ParId" SG_ 2632777721 NumPktSentTPCM_CTS "ESMD_02790";
BA_ "SPN" SG_ 2632777721 NumPktSentTPCM_CTS 2561;
BA_ "GenSigAutoGenSnd" SG_ 2632777721 NxtPktNumSentTPCM_CTS 0;
BA_ "GenSigAutoGenDsp" SG_ 2632777721 NxtPktNumSentTPCM_CTS 0;
BA_ "CI_RepetitionComplemented" SG_ 2632777721 NxtPktNumSentTPCM_CTS 2;
BA_ "CI_FullName" SG_ 2632777721 NxtPktNumSentTPCM_CTS "Next Packet Number to be sent (TP.CM_CTS)";
BA_ "CI_ParId" SG_ 2632777721 NxtPktNumSentTPCM_CTS "ESMD_02740";
BA_ "SPN" SG_ 2632777721 NxtPktNumSentTPCM_CTS 2562;
BA_ "GenSigAutoGenSnd" SG_ 2632777721 ConnAbrtReason 0;
BA_ "GenSigAutoGenDsp" SG_ 2632777721 ConnAbrtReason 0;
BA_ "CI_RepetitionComplemented" SG_ 2632777721 ConnAbrtReason 2;
BA_ "CI_FullName" SG_ 2632777721 ConnAbrtReason "Connection Abort Reason";
BA_ "CI_ParId" SG_ 2632777721 ConnAbrtReason "ESMD_00939";
BA_ "SPN" SG_ 2632777721 ConnAbrtReason 2570;
BA_ "GenSigAutoGenSnd" SG_ 2632777721 TotNumPktBAM 0;
BA_ "GenSigAutoGenDsp" SG_ 2632777721 TotNumPktBAM 0;
BA_ "CI_RepetitionComplemented" SG_ 2632777721 TotNumPktBAM 2;
BA_ "CI_FullName" SG_ 2632777721 TotNumPktBAM "_";
BA_ "CI_ParId" SG_ 2632777721 TotNumPktBAM "ESMD_03435";
BA_ "SPN" SG_ 2632777721 TotNumPktBAM 2568;
BA_ "GenSigAutoGenSnd" SG_ 2632777721 TotMsgSizeBAM 0;
BA_ "GenSigAutoGenDsp" SG_ 2632777721 TotMsgSizeBAM 0;
BA_ "CI_RepetitionComplemented" SG_ 2632777721 TotMsgSizeBAM 2;
BA_ "CI_FullName" SG_ 2632777721 TotMsgSizeBAM "_";
BA_ "CI_ParId" SG_ 2632777721 TotMsgSizeBAM "ESMD_03432";
BA_ "SPN" SG_ 2632777721 TotMsgSizeBAM 2567;
BA_ "GenSigAutoGenSnd" SG_ 2632777721 TotMsgSizeEoMA 0;
BA_ "GenSigAutoGenDsp" SG_ 2632777721 TotMsgSizeEoMA 0;
BA_ "CI_RepetitionComplemented" SG_ 2632777721 TotMsgSizeEoMA 2;
BA_ "CI_FullName" SG_ 2632777721 TotMsgSizeEoMA "_";
BA_ "CI_ParId" SG_ 2632777721 TotMsgSizeEoMA "ESMD_03433";
BA_ "SPN" SG_ 2632777721 TotMsgSizeEoMA 2564;
BA_ "GenSigAutoGenSnd" SG_ 2632777721 TotNumPktEoMA 0;
BA_ "GenSigAutoGenDsp" SG_ 2632777721 TotNumPktEoMA 0;
BA_ "CI_RepetitionComplemented" SG_ 2632777721 TotNumPktEoMA 2;
BA_ "CI_FullName" SG_ 2632777721 TotNumPktEoMA "_";
BA_ "CI_ParId" SG_ 2632777721 TotNumPktEoMA "ESMD_03436";
BA_ "SPN" SG_ 2632777721 TotNumPktEoMA 2565;
BA_ "GenSigAutoGenSnd" SG_ 2632777721 PGN_PktMsgTPCM_ConnAbort 0;
BA_ "GenSigAutoGenDsp" SG_ 2632777721 PGN_PktMsgTPCM_ConnAbort 0;
BA_ "CI_RepetitionComplemented" SG_ 2632777721 PGN_PktMsgTPCM_ConnAbort 2;
BA_ "CI_FullName" SG_ 2632777721 PGN_PktMsgTPCM_ConnAbort "Parameter Group Number of the packeted message (TP.CM_Conn_Abort)";
BA_ "CI_ParId" SG_ 2632777721 PGN_PktMsgTPCM_ConnAbort "ESMD_03862";
BA_ "SPN" SG_ 2632777721 PGN_PktMsgTPCM_ConnAbort 2571;
BA_ "GenSigAutoGenSnd" SG_ 2632777721 PGN_PktMsgTPCM_BAM 0;
BA_ "GenSigAutoGenDsp" SG_ 2632777721 PGN_PktMsgTPCM_BAM 0;
BA_ "CI_RepetitionComplemented" SG_ 2632777721 PGN_PktMsgTPCM_BAM 2;
BA_ "CI_FullName" SG_ 2632777721 PGN_PktMsgTPCM_BAM "Parameter Group Number of the packeted message (TP.CM_BAM)";
BA_ "CI_ParId" SG_ 2632777721 PGN_PktMsgTPCM_BAM "ESMD_03861";
BA_ "SPN" SG_ 2632777721 PGN_PktMsgTPCM_BAM 2569;
BA_ "CI_FullName" SG_ 2632777721 PGN_PktMsgTPCM_RTS2 "Parameter Group Number of the packeted message (TP.CM_RTS) 2";
BA_ "CI_ParId" SG_ 2632777721 PGN_PktMsgTPCM_RTS2 "ESMD_03860";
BA_ "SPN" SG_ 2632777721 PGN_PktMsgTPCM_RTS2 2566;
BA_ "GenSigAutoGenSnd" SG_ 2632777721 PGN_PktMsgTPCM_CTS 0;
BA_ "GenSigAutoGenDsp" SG_ 2632777721 PGN_PktMsgTPCM_CTS 0;
BA_ "CI_RepetitionComplemented" SG_ 2632777721 PGN_PktMsgTPCM_CTS 2;
BA_ "CI_FullName" SG_ 2632777721 PGN_PktMsgTPCM_CTS "Parameter Group Number of the packeted message (TP.CM_CTS)";
BA_ "CI_ParId" SG_ 2632777721 PGN_PktMsgTPCM_CTS "ESMD_03859";
BA_ "SPN" SG_ 2632777721 PGN_PktMsgTPCM_CTS 2563;
BA_ "CI_FullName" SG_ 2566838521 NameCmdAddrTarg "NAME of Commanded Address Target";
BA_ "CI_ParId" SG_ 2566838521 NameCmdAddrTarg "ESMD_15120";
BA_ "SPN" SG_ 2566838521 NameCmdAddrTarg 2849;
BA_ "CI_FullName" SG_ 2566838521 AddrAssignNewSA "Address Assignment (new source address)";
BA_ "CI_ParId" SG_ 2566838521 AddrAssignNewSA "ESMD_00042";
BA_ "SPN" SG_ 2566838521 AddrAssignNewSA 2847;
BA_ "GenSigAutoGenSnd" SG_ 2564456697 BlkSize 0;
BA_ "GenSigAutoGenDsp" SG_ 2564456697 BlkSize 0;
BA_ "CI_RepetitionComplemented" SG_ 2564456697 BlkSize 2;
BA_ "CI_FullName" SG_ 2564456697 BlkSize "Block Size";
BA_ "CI_ParId" SG_ 2564456697 BlkSize "ESMD_00809";
BA_ "GenSigAutoGenSnd" SG_ 2564456697 FlowSts 0;
BA_ "GenSigAutoGenDsp" SG_ 2564456697 FlowSts 0;
BA_ "CI_RepetitionComplemented" SG_ 2564456697 FlowSts 2;
BA_ "CI_FullName" SG_ 2564456697 FlowSts "Flow Status";
BA_ "CI_ParId" SG_ 2564456697 FlowSts "ESMD_01968";
BA_ "GenSigAutoGenSnd" SG_ 2564456697 N1FrameDataLen 0;
BA_ "GenSigAutoGenDsp" SG_ 2564456697 N1FrameDataLen 0;
BA_ "CI_RepetitionComplemented" SG_ 2564456697 N1FrameDataLen 2;
BA_ "CI_FullName" SG_ 2564456697 N1FrameDataLen "First Frame Data Length";
BA_ "CI_ParId" SG_ 2564456697 N1FrameDataLen "ESMD_01962";
BA_ "GenSigAutoGenSnd" SG_ 2564456697 ProtocCntrlInfo 0;
BA_ "GenSigAutoGenDsp" SG_ 2564456697 ProtocCntrlInfo 0;
BA_ "CI_RepetitionComplemented" SG_ 2564456697 ProtocCntrlInfo 2;
BA_ "CI_FullName" SG_ 2564456697 ProtocCntrlInfo "Protocol Control Information";
BA_ "CI_ParId" SG_ 2564456697 ProtocCntrlInfo "ESMD_02905";
BA_ "GenSigAutoGenSnd" SG_ 2564456697 SepTime 0;
BA_ "GenSigAutoGenDsp" SG_ 2564456697 SepTime 0;
BA_ "CI_RepetitionComplemented" SG_ 2564456697 SepTime 2;
BA_ "CI_FullName" SG_ 2564456697 SepTime "Separation Time";
BA_ "CI_ParId" SG_ 2564456697 SepTime "ESMD_03113";
BA_ "GenSigAutoGenSnd" SG_ 2564456697 SingFrameDataLen 0;
BA_ "GenSigAutoGenDsp" SG_ 2564456697 SingFrameDataLen 0;
BA_ "CI_RepetitionComplemented" SG_ 2564456697 SingFrameDataLen 2;
BA_ "CI_FullName" SG_ 2564456697 SingFrameDataLen "Single Frame Data Length";
BA_ "CI_ParId" SG_ 2564456697 SingFrameDataLen "ESMD_03135";
BA_ "GenSigAutoGenSnd" SG_ 2564456697 SN 0;
BA_ "GenSigAutoGenDsp" SG_ 2564456697 SN 0;
BA_ "CI_RepetitionComplemented" SG_ 2564456697 SN 2;
BA_ "CI_FullName" SG_ 2564456697 SN "Serial Number";
BA_ "CI_ParId" SG_ 2564456697 SN "ESMD_03138";
BA_ "CI_FullName" SG_ 2566843264 UnitNumPwrUnit "Unit Number (Power Unit)";
BA_ "CI_ParId" SG_ 2566843264 UnitNumPwrUnit "ESMD_03702";
BA_ "CI_SLOT_Name" SG_ 2566843264 UnitNumPwrUnit "SAEatad0200";
BA_ "SPN" SG_ 2566843264 UnitNumPwrUnit 233;
BA_ "CI_FullName" SG_ 2566843264 SN_2_Byte_15 "Serial Number 2";
BA_ "CI_ParId" SG_ 2566843264 SN_2_Byte_15 "ESMD_03115";
BA_ "CI_SLOT_Name" SG_ 2566843264 SN_2_Byte_15 "SAEatad0200";
BA_ "SPN" SG_ 2566843264 SN_2_Byte_15 588;
BA_ "SigType" SG_ 2566843264 SN_2_Byte_15 8;
BA_ "CI_FullName" SG_ 2566843264 SN_2_Byte_14 "Serial Number 2";
BA_ "CI_ParId" SG_ 2566843264 SN_2_Byte_14 "ESMD_03115";
BA_ "CI_SLOT_Name" SG_ 2566843264 SN_2_Byte_14 "SAEatad0200";
BA_ "SPN" SG_ 2566843264 SN_2_Byte_14 588;
BA_ "SigType" SG_ 2566843264 SN_2_Byte_14 8;
BA_ "CI_FullName" SG_ 2566843264 SN_2_Byte_13 "Serial Number 2";
BA_ "CI_ParId" SG_ 2566843264 SN_2_Byte_13 "ESMD_03115";
BA_ "CI_SLOT_Name" SG_ 2566843264 SN_2_Byte_13 "SAEatad0200";
BA_ "SPN" SG_ 2566843264 SN_2_Byte_13 588;
BA_ "SigType" SG_ 2566843264 SN_2_Byte_13 8;
BA_ "CI_FullName" SG_ 2566843264 SN_2_Byte_12 "Serial Number 2";
BA_ "CI_ParId" SG_ 2566843264 SN_2_Byte_12 "ESMD_03115";
BA_ "CI_SLOT_Name" SG_ 2566843264 SN_2_Byte_12 "SAEatad0200";
BA_ "SPN" SG_ 2566843264 SN_2_Byte_12 588;
BA_ "SigType" SG_ 2566843264 SN_2_Byte_12 8;
BA_ "CI_FullName" SG_ 2566843264 SN_2_Byte_11 "Serial Number 2";
BA_ "CI_ParId" SG_ 2566843264 SN_2_Byte_11 "ESMD_03115";
BA_ "CI_SLOT_Name" SG_ 2566843264 SN_2_Byte_11 "SAEatad0200";
BA_ "SPN" SG_ 2566843264 SN_2_Byte_11 588;
BA_ "SigType" SG_ 2566843264 SN_2_Byte_11 8;
BA_ "CI_FullName" SG_ 2566843264 SN_2_Byte_10 "Serial Number 2";
BA_ "CI_ParId" SG_ 2566843264 SN_2_Byte_10 "ESMD_03115";
BA_ "CI_SLOT_Name" SG_ 2566843264 SN_2_Byte_10 "SAEatad0200";
BA_ "SPN" SG_ 2566843264 SN_2_Byte_10 588;
BA_ "SigType" SG_ 2566843264 SN_2_Byte_10 8;
BA_ "CI_FullName" SG_ 2566843264 SN_2_Byte_09 "Serial Number 2";
BA_ "CI_ParId" SG_ 2566843264 SN_2_Byte_09 "ESMD_03115";
BA_ "CI_SLOT_Name" SG_ 2566843264 SN_2_Byte_09 "SAEatad0200";
BA_ "SPN" SG_ 2566843264 SN_2_Byte_09 588;
BA_ "SigType" SG_ 2566843264 SN_2_Byte_09 8;
BA_ "CI_FullName" SG_ 2566843264 SN_2_Byte_08 "Serial Number 2";
BA_ "CI_ParId" SG_ 2566843264 SN_2_Byte_08 "ESMD_03115";
BA_ "CI_SLOT_Name" SG_ 2566843264 SN_2_Byte_08 "SAEatad0200";
BA_ "SPN" SG_ 2566843264 SN_2_Byte_08 588;
BA_ "SigType" SG_ 2566843264 SN_2_Byte_08 8;
BA_ "CI_FullName" SG_ 2566843264 SN_2_Byte_07 "Serial Number 2";
BA_ "CI_ParId" SG_ 2566843264 SN_2_Byte_07 "ESMD_03115";
BA_ "CI_SLOT_Name" SG_ 2566843264 SN_2_Byte_07 "SAEatad0200";
BA_ "SPN" SG_ 2566843264 SN_2_Byte_07 588;
BA_ "SigType" SG_ 2566843264 SN_2_Byte_07 8;
BA_ "CI_FullName" SG_ 2566843264 SN_2_Byte_06 "Serial Number 2";
BA_ "CI_ParId" SG_ 2566843264 SN_2_Byte_06 "ESMD_03115";
BA_ "CI_SLOT_Name" SG_ 2566843264 SN_2_Byte_06 "SAEatad0200";
BA_ "SPN" SG_ 2566843264 SN_2_Byte_06 588;
BA_ "SigType" SG_ 2566843264 SN_2_Byte_06 8;
BA_ "CI_FullName" SG_ 2566843264 SN_2_Byte_05 "Serial Number 2";
BA_ "CI_ParId" SG_ 2566843264 SN_2_Byte_05 "ESMD_03115";
BA_ "CI_SLOT_Name" SG_ 2566843264 SN_2_Byte_05 "SAEatad0200";
BA_ "SPN" SG_ 2566843264 SN_2_Byte_05 588;
BA_ "SigType" SG_ 2566843264 SN_2_Byte_05 8;
BA_ "CI_FullName" SG_ 2566843264 SN_2_Byte_04 "Serial Number 2";
BA_ "CI_ParId" SG_ 2566843264 SN_2_Byte_04 "ESMD_03115";
BA_ "CI_SLOT_Name" SG_ 2566843264 SN_2_Byte_04 "SAEatad0200";
BA_ "SPN" SG_ 2566843264 SN_2_Byte_04 588;
BA_ "SigType" SG_ 2566843264 SN_2_Byte_04 8;
BA_ "CI_FullName" SG_ 2566843264 SN_2_Byte_03 "Serial Number 2";
BA_ "CI_ParId" SG_ 2566843264 SN_2_Byte_03 "ESMD_03115";
BA_ "CI_SLOT_Name" SG_ 2566843264 SN_2_Byte_03 "SAEatad0200";
BA_ "SPN" SG_ 2566843264 SN_2_Byte_03 588;
BA_ "SigType" SG_ 2566843264 SN_2_Byte_03 8;
BA_ "CI_FullName" SG_ 2566843264 SN_2_Byte_02 "Serial Number 2";
BA_ "CI_ParId" SG_ 2566843264 SN_2_Byte_02 "ESMD_03115";
BA_ "CI_SLOT_Name" SG_ 2566843264 SN_2_Byte_02 "SAEatad0200";
BA_ "SPN" SG_ 2566843264 SN_2_Byte_02 588;
BA_ "SigType" SG_ 2566843264 SN_2_Byte_02 8;
BA_ "CI_FullName" SG_ 2566843264 Mdl_Byte_08 "Model";
BA_ "CI_ParId" SG_ 2566843264 Mdl_Byte_08 "ESMD_02715";
BA_ "CI_SLOT_Name" SG_ 2566843264 Mdl_Byte_08 "SAEatad0200";
BA_ "SPN" SG_ 2566843264 Mdl_Byte_08 587;
BA_ "SigType" SG_ 2566843264 Mdl_Byte_08 8;
BA_ "CI_FullName" SG_ 2566843264 Mdl_Byte_07 "Model";
BA_ "CI_ParId" SG_ 2566843264 Mdl_Byte_07 "ESMD_02715";
BA_ "CI_SLOT_Name" SG_ 2566843264 Mdl_Byte_07 "SAEatad0200";
BA_ "SPN" SG_ 2566843264 Mdl_Byte_07 587;
BA_ "SigType" SG_ 2566843264 Mdl_Byte_07 8;
BA_ "CI_FullName" SG_ 2566843264 Mdl_Byte_06 "Model";
BA_ "CI_ParId" SG_ 2566843264 Mdl_Byte_06 "ESMD_02715";
BA_ "CI_SLOT_Name" SG_ 2566843264 Mdl_Byte_06 "SAEatad0200";
BA_ "SPN" SG_ 2566843264 Mdl_Byte_06 587;
BA_ "SigType" SG_ 2566843264 Mdl_Byte_06 8;
BA_ "CI_FullName" SG_ 2566843264 Mdl_Byte_05 "Model";
BA_ "CI_ParId" SG_ 2566843264 Mdl_Byte_05 "ESMD_02715";
BA_ "CI_SLOT_Name" SG_ 2566843264 Mdl_Byte_05 "SAEatad0200";
BA_ "SPN" SG_ 2566843264 Mdl_Byte_05 587;
BA_ "SigType" SG_ 2566843264 Mdl_Byte_05 8;
BA_ "CI_FullName" SG_ 2566843264 Mdl_Byte_04 "Model";
BA_ "CI_ParId" SG_ 2566843264 Mdl_Byte_04 "ESMD_02715";
BA_ "CI_SLOT_Name" SG_ 2566843264 Mdl_Byte_04 "SAEatad0200";
BA_ "SPN" SG_ 2566843264 Mdl_Byte_04 587;
BA_ "SigType" SG_ 2566843264 Mdl_Byte_04 8;
BA_ "CI_FullName" SG_ 2566843264 Mdl_Byte_03 "Model";
BA_ "CI_ParId" SG_ 2566843264 Mdl_Byte_03 "ESMD_02715";
BA_ "CI_SLOT_Name" SG_ 2566843264 Mdl_Byte_03 "SAEatad0200";
BA_ "SPN" SG_ 2566843264 Mdl_Byte_03 587;
BA_ "SigType" SG_ 2566843264 Mdl_Byte_03 8;
BA_ "CI_FullName" SG_ 2566843264 Mdl_Byte_02 "Model";
BA_ "CI_ParId" SG_ 2566843264 Mdl_Byte_02 "ESMD_02715";
BA_ "CI_SLOT_Name" SG_ 2566843264 Mdl_Byte_02 "SAEatad0200";
BA_ "SPN" SG_ 2566843264 Mdl_Byte_02 587;
BA_ "SigType" SG_ 2566843264 Mdl_Byte_02 8;
BA_ "CI_FullName" SG_ 2566843264 Mdl_Byte_01 "Model";
BA_ "CI_ParId" SG_ 2566843264 Mdl_Byte_01 "ESMD_02715";
BA_ "CI_SLOT_Name" SG_ 2566843264 Mdl_Byte_01 "SAEatad0200";
BA_ "SPN" SG_ 2566843264 Mdl_Byte_01 587;
BA_ "SigType" SG_ 2566843264 Mdl_Byte_01 8;
BA_ "CI_FullName" SG_ 2566843264 SN_2_Byte_01 "Serial Number 2";
BA_ "CI_ParId" SG_ 2566843264 SN_2_Byte_01 "ESMD_03115";
BA_ "CI_SLOT_Name" SG_ 2566843264 SN_2_Byte_01 "SAEatad0200";
BA_ "SPN" SG_ 2566843264 SN_2_Byte_01 588;
BA_ "SigType" SG_ 2566843264 SN_2_Byte_01 8;
BA_ "CI_FullName" SG_ 2566843264 SN_2 "Serial Number 2";
BA_ "CI_ParId" SG_ 2566843264 SN_2 "ESMD_03115";
BA_ "CI_SLOT_Name" SG_ 2566843264 SN_2 "SAEatad0200";
BA_ "SPN" SG_ 2566843264 SN_2 588;
BA_ "CI_FullName" SG_ 2566843264 Make "Make";
BA_ "CI_ParId" SG_ 2566843264 Make "ESMD_02671";
BA_ "CI_SLOT_Name" SG_ 2566843264 Make "SAEatad0005";
BA_ "SPN" SG_ 2566843264 Make 586;
BA_ "CI_FullName" SG_ 2566843264 Mdl "Model";
BA_ "CI_ParId" SG_ 2566843264 Mdl "ESMD_02715";
BA_ "CI_SLOT_Name" SG_ 2566843264 Mdl "SAEatad0200";
BA_ "SPN" SG_ 2566843264 Mdl 587;
BA_ "GenSigAutoGenSnd" SG_ 2564487552 SepTime 0;
BA_ "GenSigAutoGenDsp" SG_ 2564487552 SepTime 0;
BA_ "CI_RepetitionComplemented" SG_ 2564487552 SepTime 2;
BA_ "CI_FullName" SG_ 2564487552 SepTime "Separation Time";
BA_ "CI_ParId" SG_ 2564487552 SepTime "ESMD_03113";
BA_ "GenSigAutoGenSnd" SG_ 2564487552 SingFrameDataLen 0;
BA_ "GenSigAutoGenDsp" SG_ 2564487552 SingFrameDataLen 0;
BA_ "CI_RepetitionComplemented" SG_ 2564487552 SingFrameDataLen 2;
BA_ "CI_FullName" SG_ 2564487552 SingFrameDataLen "Single Frame Data Length";
BA_ "CI_ParId" SG_ 2564487552 SingFrameDataLen "ESMD_03135";
BA_ "GenSigAutoGenSnd" SG_ 2564487552 N1FrameDataLen 0;
BA_ "GenSigAutoGenDsp" SG_ 2564487552 N1FrameDataLen 0;
BA_ "CI_RepetitionComplemented" SG_ 2564487552 N1FrameDataLen 2;
BA_ "CI_FullName" SG_ 2564487552 N1FrameDataLen "First Frame Data Length";
BA_ "CI_ParId" SG_ 2564487552 N1FrameDataLen "ESMD_01962";
BA_ "GenSigAutoGenSnd" SG_ 2564487552 BlkSize 0;
BA_ "GenSigAutoGenDsp" SG_ 2564487552 BlkSize 0;
BA_ "CI_RepetitionComplemented" SG_ 2564487552 BlkSize 2;
BA_ "CI_FullName" SG_ 2564487552 BlkSize "Block Size";
BA_ "CI_ParId" SG_ 2564487552 BlkSize "ESMD_00809";
BA_ "GenSigAutoGenSnd" SG_ 2564487552 FlowSts 0;
BA_ "GenSigAutoGenDsp" SG_ 2564487552 FlowSts 0;
BA_ "CI_RepetitionComplemented" SG_ 2564487552 FlowSts 2;
BA_ "CI_FullName" SG_ 2564487552 FlowSts "Flow Status";
BA_ "CI_ParId" SG_ 2564487552 FlowSts "ESMD_01968";
BA_ "GenSigAutoGenSnd" SG_ 2564487552 SN 0;
BA_ "GenSigAutoGenDsp" SG_ 2564487552 SN 0;
BA_ "CI_RepetitionComplemented" SG_ 2564487552 SN 2;
BA_ "CI_FullName" SG_ 2564487552 SN "Serial Number";
BA_ "CI_ParId" SG_ 2564487552 SN "ESMD_03138";
BA_ "GenSigAutoGenSnd" SG_ 2564487552 ProtocCntrlInfo 0;
BA_ "GenSigAutoGenDsp" SG_ 2564487552 ProtocCntrlInfo 0;
BA_ "CI_RepetitionComplemented" SG_ 2564487552 ProtocCntrlInfo 2;
BA_ "CI_FullName" SG_ 2564487552 ProtocCntrlInfo "Protocol Control Information";
BA_ "CI_ParId" SG_ 2564487552 ProtocCntrlInfo "ESMD_02905";
BA_ "CI_FullName" SG_ 2560825102 DTC_01 "Diagnostic Trouble Code 01";
BA_ "CI_ParId" SG_ 2560825102 DTC_01 "ESMD_01142";
BA_ "CI_FullName" SG_ 2560825102 DTCxAmbrWarnLmpSupp_andSts "DTCx Amber Warning Lamp Support & Status";
BA_ "CI_ParId" SG_ 2560825102 DTCxAmbrWarnLmpSupp_andSts "ESMD_01157";
BA_ "SPN" SG_ 2560825102 DTCxAmbrWarnLmpSupp_andSts 4115;
BA_ "CI_FullName" SG_ 2560825102 DTCxFlashAmbrWarnLmpSupp_andSts "DTCx Flash Amber Warning Lamp Support & Status";
BA_ "CI_ParId" SG_ 2560825102 DTCxFlashAmbrWarnLmpSupp_andSts "ESMD_01156";
BA_ "SPN" SG_ 2560825102 DTCxFlashAmbrWarnLmpSupp_andSts 4119;
BA_ "CI_FullName" SG_ 2560825102 DTCxFlashMIL_Supp_andSts "DTCx Flash Malfunction Indicator Lamp Support & Status";
BA_ "CI_ParId" SG_ 2560825102 DTCxFlashMIL_Supp_andSts "ESMD_01147";
BA_ "SPN" SG_ 2560825102 DTCxFlashMIL_Supp_andSts 4117;
BA_ "CI_FullName" SG_ 2560825102 DTCxFlashProtLmpSupp_andSts "DTCx Flash Protect Lamp Support & Status";
BA_ "CI_ParId" SG_ 2560825102 DTCxFlashProtLmpSupp_andSts "ESMD_01149";
BA_ "SPN" SG_ 2560825102 DTCxFlashProtLmpSupp_andSts 4120;
BA_ "CI_FullName" SG_ 2560825102 DTCxFlashRedStopLmpSupp_andSts "DTCx Flash Red Stop Lamp Support & Status";
BA_ "CI_ParId" SG_ 2560825102 DTCxFlashRedStopLmpSupp_andSts "ESMD_01151";
BA_ "SPN" SG_ 2560825102 DTCxFlashRedStopLmpSupp_andSts 4118;
BA_ "CI_FullName" SG_ 2560825102 DTCxMIL_Supp_andSts "DTCx Malfunction Indicator Lamp Support & Status";
BA_ "CI_ParId" SG_ 2560825102 DTCxMIL_Supp_andSts "ESMD_01148";
BA_ "SPN" SG_ 2560825102 DTCxMIL_Supp_andSts 4113;
BA_ "CI_FullName" SG_ 2560825102 DTCxProtLmpSupp_andSts "DTCx Protect Lamp Support & Status";
BA_ "CI_ParId" SG_ 2560825102 DTCxProtLmpSupp_andSts "ESMD_01150";
BA_ "SPN" SG_ 2560825102 DTCxProtLmpSupp_andSts 4116;
BA_ "CI_FullName" SG_ 2560825102 DTCxRedStopLmpSupp_andSts "DTCx Red Stop Lamp Support & Status";
BA_ "CI_ParId" SG_ 2560825102 DTCxRedStopLmpSupp_andSts "ESMD_01152";
BA_ "SPN" SG_ 2560825102 DTCxRedStopLmpSupp_andSts 4114;
BA_ "CI_FullName" SG_ 2632712073 PktDataTPDT "Packetized Data (TP.DT)";
BA_ "CI_ParId" SG_ 2632712073 PktDataTPDT "ESMD_16027";
BA_ "SPN" SG_ 2632712073 PktDataTPDT 2573;
BA_ "CI_FullName" SG_ 2632712073 SN_TPDT "Sequence Number (TP.DT)";
BA_ "CI_ParId" SG_ 2632712073 SN_TPDT "ESMD_03114";
BA_ "SPN" SG_ 2632712073 SN_TPDT 2572;
BA_ "CI_FullName" SG_ 2632712074 PktDataTPDT "Packetized Data (TP.DT)";
BA_ "CI_ParId" SG_ 2632712074 PktDataTPDT "ESMD_16027";
BA_ "SPN" SG_ 2632712074 PktDataTPDT 2573;
BA_ "CI_FullName" SG_ 2632712074 SN_TPDT "Sequence Number (TP.DT)";
BA_ "CI_ParId" SG_ 2632712074 SN_TPDT "ESMD_03114";
BA_ "SPN" SG_ 2632712074 SN_TPDT 2572;
BA_ "GenSigAutoGenSnd" SG_ 2632777609 CByteTPCM 0;
BA_ "GenSigAutoGenDsp" SG_ 2632777609 CByteTPCM 0;
BA_ "CI_RepetitionComplemented" SG_ 2632777609 CByteTPCM 2;
BA_ "CI_FullName" SG_ 2632777609 CByteTPCM "Control Byte (TP.CM)";
BA_ "CI_ParId" SG_ 2632777609 CByteTPCM "ESMD_00941";
BA_ "SPN" SG_ 2632777609 CByteTPCM 2556;
BA_ "GenSigAutoGenSnd" SG_ 2632777609 ConnAbrtReason 0;
BA_ "GenSigAutoGenDsp" SG_ 2632777609 ConnAbrtReason 0;
BA_ "CI_RepetitionComplemented" SG_ 2632777609 ConnAbrtReason 2;
BA_ "CI_FullName" SG_ 2632777609 ConnAbrtReason "Connection Abort Reason";
BA_ "CI_ParId" SG_ 2632777609 ConnAbrtReason "ESMD_00939";
BA_ "SPN" SG_ 2632777609 ConnAbrtReason 2570;
BA_ "GenSigAutoGenSnd" SG_ 2632777609 MaxNumPktTPCM_RTS 0;
BA_ "GenSigAutoGenDsp" SG_ 2632777609 MaxNumPktTPCM_RTS 0;
BA_ "CI_RepetitionComplemented" SG_ 2632777609 MaxNumPktTPCM_RTS 2;
BA_ "CI_FullName" SG_ 2632777609 MaxNumPktTPCM_RTS "Maximum Number of Packets (TP.CM_RTS)";
BA_ "CI_ParId" SG_ 2632777609 MaxNumPktTPCM_RTS "ESMD_02684";
BA_ "SPN" SG_ 2632777609 MaxNumPktTPCM_RTS 2559;
BA_ "GenSigAutoGenSnd" SG_ 2632777609 NumPktSentTPCM_CTS 0;
BA_ "GenSigAutoGenDsp" SG_ 2632777609 NumPktSentTPCM_CTS 0;
BA_ "CI_RepetitionComplemented" SG_ 2632777609 NumPktSentTPCM_CTS 2;
BA_ "CI_FullName" SG_ 2632777609 NumPktSentTPCM_CTS "Number of Packets that can be sent (TP.CM_CTS)";
BA_ "CI_ParId" SG_ 2632777609 NumPktSentTPCM_CTS "ESMD_02790";
BA_ "SPN" SG_ 2632777609 NumPktSentTPCM_CTS 2561;
BA_ "GenSigAutoGenSnd" SG_ 2632777609 NxtPktNumSentTPCM_CTS 0;
BA_ "GenSigAutoGenDsp" SG_ 2632777609 NxtPktNumSentTPCM_CTS 0;
BA_ "CI_RepetitionComplemented" SG_ 2632777609 NxtPktNumSentTPCM_CTS 2;
BA_ "CI_FullName" SG_ 2632777609 NxtPktNumSentTPCM_CTS "Next Packet Number to be sent (TP.CM_CTS)";
BA_ "CI_ParId" SG_ 2632777609 NxtPktNumSentTPCM_CTS "ESMD_02740";
BA_ "SPN" SG_ 2632777609 NxtPktNumSentTPCM_CTS 2562;
BA_ "GenSigAutoGenSnd" SG_ 2632777609 PGN_PktMsgTPCM_BAM 0;
BA_ "GenSigAutoGenDsp" SG_ 2632777609 PGN_PktMsgTPCM_BAM 0;
BA_ "CI_RepetitionComplemented" SG_ 2632777609 PGN_PktMsgTPCM_BAM 2;
BA_ "CI_FullName" SG_ 2632777609 PGN_PktMsgTPCM_BAM "Parameter Group Number of the packeted message (TP.CM_BAM)";
BA_ "CI_ParId" SG_ 2632777609 PGN_PktMsgTPCM_BAM "ESMD_03861";
BA_ "SPN" SG_ 2632777609 PGN_PktMsgTPCM_BAM 2569;
BA_ "GenSigAutoGenSnd" SG_ 2632777609 PGN_PktMsgTPCM_ConnAbort 0;
BA_ "GenSigAutoGenDsp" SG_ 2632777609 PGN_PktMsgTPCM_ConnAbort 0;
BA_ "CI_RepetitionComplemented" SG_ 2632777609 PGN_PktMsgTPCM_ConnAbort 2;
BA_ "CI_FullName" SG_ 2632777609 PGN_PktMsgTPCM_ConnAbort "Parameter Group Number of the packeted message (TP.CM_Conn_Abort)";
BA_ "CI_ParId" SG_ 2632777609 PGN_PktMsgTPCM_ConnAbort "ESMD_03862";
BA_ "SPN" SG_ 2632777609 PGN_PktMsgTPCM_ConnAbort 2571;
BA_ "GenSigAutoGenSnd" SG_ 2632777609 PGN_PktMsgTPCM_CTS 0;
BA_ "GenSigAutoGenDsp" SG_ 2632777609 PGN_PktMsgTPCM_CTS 0;
BA_ "CI_RepetitionComplemented" SG_ 2632777609 PGN_PktMsgTPCM_CTS 2;
BA_ "CI_FullName" SG_ 2632777609 PGN_PktMsgTPCM_CTS "Parameter Group Number of the packeted message (TP.CM_CTS)";
BA_ "CI_ParId" SG_ 2632777609 PGN_PktMsgTPCM_CTS "ESMD_03859";
BA_ "SPN" SG_ 2632777609 PGN_PktMsgTPCM_CTS 2563;
BA_ "GenSigAutoGenSnd" SG_ 2632777609 PGN_PktMsgTPCM_RTS 0;
BA_ "GenSigAutoGenDsp" SG_ 2632777609 PGN_PktMsgTPCM_RTS 0;
BA_ "CI_RepetitionComplemented" SG_ 2632777609 PGN_PktMsgTPCM_RTS 2;
BA_ "CI_FullName" SG_ 2632777609 PGN_PktMsgTPCM_RTS "Parameter Group Number of the packeted message (TP.CM_RTS)";
BA_ "CI_ParId" SG_ 2632777609 PGN_PktMsgTPCM_RTS "ESMD_02869";
BA_ "SPN" SG_ 2632777609 PGN_PktMsgTPCM_RTS 2560;
BA_ "CI_FullName" SG_ 2632777609 PGN_PktMsgTPCM_RTS2 "Parameter Group Number of the packeted message (TP.CM_RTS) 2";
BA_ "CI_ParId" SG_ 2632777609 PGN_PktMsgTPCM_RTS2 "ESMD_03860";
BA_ "SPN" SG_ 2632777609 PGN_PktMsgTPCM_RTS2 2566;
BA_ "GenSigAutoGenSnd" SG_ 2632777609 TotMsgSizeBAM 0;
BA_ "GenSigAutoGenDsp" SG_ 2632777609 TotMsgSizeBAM 0;
BA_ "CI_RepetitionComplemented" SG_ 2632777609 TotMsgSizeBAM 2;
BA_ "CI_FullName" SG_ 2632777609 TotMsgSizeBAM "_";
BA_ "CI_ParId" SG_ 2632777609 TotMsgSizeBAM "ESMD_03432";
BA_ "SPN" SG_ 2632777609 TotMsgSizeBAM 2567;
BA_ "GenSigAutoGenSnd" SG_ 2632777609 TotMsgSizeEoMA 0;
BA_ "GenSigAutoGenDsp" SG_ 2632777609 TotMsgSizeEoMA 0;
BA_ "CI_RepetitionComplemented" SG_ 2632777609 TotMsgSizeEoMA 2;
BA_ "CI_FullName" SG_ 2632777609 TotMsgSizeEoMA "_";
BA_ "CI_ParId" SG_ 2632777609 TotMsgSizeEoMA "ESMD_03433";
BA_ "SPN" SG_ 2632777609 TotMsgSizeEoMA 2564;
BA_ "GenSigAutoGenSnd" SG_ 2632777609 TotMsgSizeTPCM_RTS 0;
BA_ "GenSigAutoGenDsp" SG_ 2632777609 TotMsgSizeTPCM_RTS 0;
BA_ "CI_RepetitionComplemented" SG_ 2632777609 TotMsgSizeTPCM_RTS 2;
BA_ "CI_FullName" SG_ 2632777609 TotMsgSizeTPCM_RTS "Total Message Size (TP.CM_RTS)";
BA_ "CI_ParId" SG_ 2632777609 TotMsgSizeTPCM_RTS "ESMD_03431";
BA_ "SPN" SG_ 2632777609 TotMsgSizeTPCM_RTS 2557;
BA_ "GenSigAutoGenSnd" SG_ 2632777609 TotNumPktBAM 0;
BA_ "GenSigAutoGenDsp" SG_ 2632777609 TotNumPktBAM 0;
BA_ "CI_RepetitionComplemented" SG_ 2632777609 TotNumPktBAM 2;
BA_ "CI_FullName" SG_ 2632777609 TotNumPktBAM "_";
BA_ "CI_ParId" SG_ 2632777609 TotNumPktBAM "ESMD_03435";
BA_ "SPN" SG_ 2632777609 TotNumPktBAM 2568;
BA_ "GenSigAutoGenSnd" SG_ 2632777609 TotNumPktEoMA 0;
BA_ "GenSigAutoGenDsp" SG_ 2632777609 TotNumPktEoMA 0;
BA_ "CI_RepetitionComplemented" SG_ 2632777609 TotNumPktEoMA 2;
BA_ "CI_FullName" SG_ 2632777609 TotNumPktEoMA "_";
BA_ "CI_ParId" SG_ 2632777609 TotNumPktEoMA "ESMD_03436";
BA_ "SPN" SG_ 2632777609 TotNumPktEoMA 2565;
BA_ "GenSigAutoGenSnd" SG_ 2632777609 TotNumPktTPCM_RTS 0;
BA_ "GenSigAutoGenDsp" SG_ 2632777609 TotNumPktTPCM_RTS 0;
BA_ "CI_RepetitionComplemented" SG_ 2632777609 TotNumPktTPCM_RTS 2;
BA_ "CI_FullName" SG_ 2632777609 TotNumPktTPCM_RTS "Total Number of Packets (TP.CM_RTS)";
BA_ "CI_ParId" SG_ 2632777609 TotNumPktTPCM_RTS "ESMD_03434";
BA_ "SPN" SG_ 2632777609 TotNumPktTPCM_RTS 2558;
VAL_ 3221225472 TrailerParkBrakeRequest 3 "Don't care / Take no action" 2 "Reserved" 1 "ParkBrakeRequested" 0 "ParkBrakeNotRequested" ;
VAL_ 3221225472 SteeringBrakeDirection 3 "Not available" 2 "Right" 1 "Left" 0 "None" ;
VAL_ 3221225472 SecondaryBrakeSwitch 3 "NotAvailable" 2 "Error" 1 "On" 0 "Off" ;
VAL_ 3221225472 PGN_RQST_F9_4C 65254 "TD" 61183 "ACL" 61004 "ACL" 60928 "ACL" ;
VAL_ 3221225472 SensSupplyV_2Sts 3 "N/A" 2 "Error" 1 "Active" 0 "Not Active" ;
VAL_ 3221225472 CalibrOpMode 15 "Reserved/not used" 14 "Reserved/not used" 13 "Reserved/not used" 12 "Reserved/not used" 11 "Reserved/not used" 10 "Reserved/not used" 9 "Adjust zero" 8 "Set default calibration value" 7 "Abort calibration procedure" 6 "Store calibration value" 5 "Write calibration value" 4 "Read calibration value" 3 "Error" 2 "Operation complete" 1 "CAL active" 0 "Standby" ;
VAL_ 3221225472 CalibrErrCod 10 "WRONG_VAL (Wrong calibration values)" 8 "TERM (Procedure terminated)" 6 "TIME (Timout)" 4 "Valve not calibrated" 2 "PS (pressure switch)" 0 "OK (no error)" ;
VAL_ 3221225472 PrsSwSts 3 "Not Available" 2 "Error" 1 "On" 0 "Off" ;
VAL_ 3221225472 CalibrPnt 12 "Reserved/not used" 11 "Reserved/not used" 10 "Reserved/not used" 9 "Reserved/not used" 8 "Reserved/not used" 7 "Reserved/not used" 6 "Reserved/not used" 5 "Max Float" 4 "Max Retract" 3 "Start Retract" 2 "Max Extend" 1 "Start Extend" 0 "Not available" 15 "Reserved/not used" 14 "Spool zero" 13 "Reserved/not used" ;
VAL_ 3221225472 PBrakeActvReq 3 "N/A" 2 "Reserved" 1 "Active" 0 "Inactive" ;
VAL_ 3221225472 AirComprSts 0 "Compressor not active" 1 "Compressor active" 2 "Error indicator" 3 "Not available" ;
VAL_ 3221225472 BrakeSw 3 "NotAvailable" 2 "Error(Plausability)" 1 "PressedAndNotDefective" 0 "NotPressedAndNotDefective" ;
VAL_ 3221225472 CC_AccelSw 0 "Cruise control activator not in the position accelerate" 1 "Cruise control activator in position accelerate" 2 "Error" 3 "Not available" ;
VAL_ 3221225472 CC_Actv 0 "Cruise control switched off" 1 "Cruise control switched on" 2 "Error" 3 "Not available" ;
VAL_ 3221225472 CC_CoastDecelSw 3 "Not available" 0 "Cruise control activator not in the position coast" 1 "Cruise control activator in position coast" 2 "Error" ;
VAL_ 3221225472 CC_EnaSw 0 "Cruise control disabled" 1 "Cruise control enabled" 2 "Error" 3 "Not available" ;
VAL_ 3221225472 CC_PauseSw 0 "Off" 1 "On" 2 "Error Indicator" 3 "Take No Action" ;
VAL_ 3221225472 CC_ResumSw 0 "Cruise control activator not in the position resume" 1 "Cruise control activator in position resume" 2 "Error" 3 "Not available" ;
VAL_ 3221225472 CC_SetSw 0 "Cruise control activator not in the position set" 1 "Cruise control activator in position set" 2 "Error" 3 "Not available" ;
VAL_ 3221225472 CC_Sts 0 "Off/Disabled" 1 "Hold" 2 "Accelerate" 3 "Decelerate" 4 "Resume" 5 "Set" 6 "Accelerator Override" 7 "Not available" ;
VAL_ 3221225472 CltchSw 3 "NotAvailable" 2 "Error" 0 "Clutch Pedal Released" 1 "Clutch Pedal Depressed" ;
VAL_ 3221225472 N2SpdAxSw 0 "Low speed range" 1 "High speed range" 2 "Error" 3 "Not available" ;
VAL_ 3221225472 PBrakeRleasInhReq 0 "ParkBrakeReleaseInhibitNotRqed" 1 "ParkBrakeReleaseInhibitRqed" 2 "SAEReserved" 3 "Unavailable" ;
VAL_ 3221225472 PBrakeSw 3 "N/A" 2 "Error" 1 "Activated" 0 "Not Activated" ;
VAL_ 3221225472 PTO_GovSts 0 "Off/Disabled" 1 "Hold" 2 "Remote Hold" 3 "Standby" 4 "Remote Standby" 5 "Set" 6 "Decelerate/Coast" 7 "Resume" 8 "Accelerate" 9 "Accelerator Override" 10 "Preprogrammed set speed 1" 11 "Preprogrammed set speed 2" 12 "Preprogrammed set speed 3" 13 "Preprogrammed set speed 4" 14 "Preprogrammed set speed 5" 15 "Preprogrammed set speed 6" 16 "Preprogrammed set speed 7" 17 "Preprogrammed set speed 8" 18 "PTO set speed memory 1" 19 "PTO set speed memory 2" 31 "Not available" ;
VAL_ 2565350026 CByteAckm 3 "CannotRespond" 2 "AccessDenied" 1 "NACK" 0 "ACK" ;
VAL_ 2565350026 PGN_Ack 65521 "Dataset Identific-DIS" 65228 "DM3Req" 65257 "FuelConsumption" 65242 "SOFT" 61184 "STOD" 65235 "DM11Req" 65520 "SecurityCheck" 65253 "EngHoursRevolutio" 65227 "DM2Req" ;
VAL_ 2565350026 PGN_NAck 65521 "Dataset Identific-DIS" 65228 "DM3Req" 65257 "FuelConsumption" 65242 "SOFT" 61184 "STOD" 65235 "DM11Req" 65520 "SecurityCheck" 65253 "EngHoursRevolutio" 65227 "DM2Req" ;
VAL_ 2565350026 PGN_NAckAd 65521 "Dataset Identific-DIS" 65228 "DM3Req" 65257 "FuelConsumption" 65242 "SOFT" 61184 "STOD" 65235 "DM11Req" 65520 "SecurityCheck" 65253 "EngHoursRevolutio" 65227 "DM2Req" ;
VAL_ 2565350026 PGN_NAckBusy 65521 "Dataset Identific-DIS" 65228 "DM3Req" 65257 "FuelConsumption" 65242 "SOFT" 61184 "STOD" 65235 "DM11Req" 65520 "SecurityCheck" 65253 "EngHoursRevolutio" 65227 "DM2Req" ;
VAL_ 2566835082 AmbrWarnLmp 2 "flashing" 0 "Lamp off" 1 "Lamp on" 3 "Not available" ;
VAL_ 2566835082 FlashAmbrWarnLmpAWL 0 "Slow Flash" 1 "Fast Flash" 2 "Reserved" 3 "Unavailable / Do Not Flash" ;
VAL_ 2566835082 FlashMIL 0 "Slow Flash" 1 "Fast Flash" 2 "Reserved" 3 "Unavailable / Do Not Flash" ;
VAL_ 2566835082 FlashProtLmp 0 "Slow Flash" 1 "Fast Flash" 2 "Reserved" 3 "Unavailable / Do Not Flash" ;
VAL_ 2566835082 FlashRedStopLmpRSL 0 "Slow Flash" 1 "Fast Flash" 2 "Reserved" 3 "Unavailable / Do Not Flash" ;
VAL_ 2566835082 MIL 0 "Lamp off" 1 "Lamp on" 2 "Reserved" 3 "Not available" ;
VAL_ 2566835082 ProtLmp 0 "Lamp off" 1 "Lamp on" 2 "Reserved" 3 "Not available" ;
VAL_ 2566835082 RedStopLmp 0 "Lamp off" 1 "Lamp on" 3 "Not available" ;
VAL_ 2566854794 FailSvng 3 "Do Not Care" 2 "Error Indication" 1 "Float" 0 "Neutral" ;
VAL_ 2566854794 OpMode 15 "Do Not Care" 14 "Error Indication" 3 "Float/Open Centre" 2 "Retract" 1 "Extend" 0 "Blocked/Neutral" ;
VAL_ 2566866058 EHR_ParamByte_1 127 "EHR Parameter Status" 59 "EHR Parameter Control" ;
VAL_ 2566866058 EHR_ParamStsByte_3 244 "Check status (PTO uses)" 103 "RoundingOfTheTimeRamp" 80 "ReadChecksumOfApplicationSw" ;
VAL_ 2566865546 EHR_Err 0 "Normal Operation" 1 "Fault State" 2 "Error" 3 "Not Available" ;
VAL_ 2566865546 EHR_ErrCod 69 "InternalComponentFailureSevere" 68 "InternalComponentFailureCritical" 61 "Open center position not reached" 59 "Invalid command message" 58 "Command message timeout" 54 "Address claim conflict" 48 "Spool not in neutral at power on" 47 "Open center position not reached" 46 "Spool stuck out of neutral" 44 "Actuator temp above upper limit" 5 "Supply voltage below limit" 4 "Supply voltage above limit" 0 "Initialization failure" 131 "Checksum failure" 23 "No neutral command at power on" 20 "Valve spool not calibrated" 130 "Spool not in neutral at power on" 129 "Spool not responding to commands" 67 "InternalComponentFailureWarning" 66 "D:No neutral cmd, T:intrnl fail" 65 "Supply voltage above limit" 50 "Supply voltage above limit" 49 "Low volts, D: Position error" 38 "Manual operation" 37 "Open center position not reached" 36 "Spool deflection excessive" 35 "Spool deflection too short" 34 "Supply voltage above limit" 33 "D:Init failure, B:Low volt input" 19 "Implausible CAN control message" 17 "No CAN control message received" 22 "EEPROM failure" ;
VAL_ 2566865546 EHR_EvTemp 255 "Error" ;
VAL_ 2566865546 EHR_InitDiag 0 "Normal Operation" 1 "Initialisation State" 2 "Error" 3 "Not Available" ;
VAL_ 2564487562 ProtocCntrlInfo 0 "Single frame" 1 "First frame" 2 "Consecutive frame" 3 "Flow control " ;
VAL_ 2564487562 FlowSts 0 "Continue To Send" 1 "Wait " 2 "Overflow" ;
VAL_ 2565799818 ManufctCod 195 "General Engine Products" 196 "LEMKEN GmbH & Co. KG" 197 "Mechron Power Systems" 198 "Mystic Valley Communications" 199 "Actia Corp." 200 "MGM Brakes" 201 "Disenos y Tecnologia S.A." 202 "Curtis Instruments, Inc." 203 "MILtronik GmbH" 204 "The Morey Corporation" 205 "SmarTire Systems Inc" 206 "port GmbH" 207 "Otto Engineering" 208 "Drew Technologies, Inc." 209 "Bell Equip. Co. SA (PTY) LTD" 210 "Iteris, Inc." 211 "DNA Group" 212 "Sure Power Industries, Inc." 213 "CNH Belgium N.V." 214 "MC elettronica Srl" 215 "Aetna Engineering/Fireboy-Xintex" 216 "Paneltronics Inc." 217 "RM Michaelides Software & Elektronik GmbH" 218 "Gits Manufacturing Company" 219 "Cat OEM Solutions" 220 "Beede Electrical Instrument Company, Inc." 221 "SiE" 222 "Generac Power Systems, Inc." 1850 "Teleflex" 1851 "Raymarine" 1852 "Navionics" 1853 "Japan Radio Co." 1854 "Northstar Technologies" 1855 "Furuno USA" 1856 "Trimble" 1857 "Simrad" 1858 "Litton" 1859 "Kvasar AB" 1860 "MMP" 1861 "Vector CANtech" 1862 "Sanshin" 1863 "Thomas G. Faria Co." 232 "TSD Integrated Controls" 234 "Mondial electronic GmbH" 235 "SailorMade Marine Telemetry - Tetra Technology Ltd." 236 "Norac Systems International Inc" 237 "Agtron Enterprises Inc" 238 "ZF Friedrichshafen AG" 239 "May & Scofield Ltd" 240 "Vanair Mfg" 241 "Schneider Automation SAS " 242 "Kokusandenki Co. Ltd" 243 "eRide, Inc." 244 "Techno-Matic" 245 "Capstan Ag Systems, Inc." 246 "Class 1, Inc" 247 "ePULSE" 248 "Cooper Standard Automotive Active Systems Group" 264 "Autolync" 265 "MTS Sensor Technologie GmbH" 266 "International Thermal Research Ltd" 114 "EControls, Inc." 115 "NACCO Materials Handling Group, Inc." 116 "BEELINE Technologies" 117 "HUSCO International" 118 "Intron GmbH" 119 "IntegriNautics" 120 "RDS Technology Ltd." 121 "HED (Hydro Electronic Devices, Inc.)" 122 "FG Wilson (Engineering) Limited" 123 "Basler Electric" 124 "Hydac Electronic" 125 "Nevada Automotive Test Center" 126 "Driver Tech" 127 "Holland USA" 128 "Gerhard Duecker GmbH & Co. KG" 129 "OMNEX Control Systems, Inc." 130 "Nido - Universal Machines B.V." 131 "ITT Industries" 132 "Mulag-Fahrzeugwerk" 133 "Bucher Schoerling GmbH" 134 "Iris Technology Ltd." 135 "Airmar Technology Corporation" 136 "Komatsu Ltd." 137 "Maretron" 138 "Georg Fritzmeier GmbH & Co. KG" 139 "Caterpillar Trimble Control Technologies (CTCT), LLC" 140 "Lowrance Electronics, Inc." 141 "Thales Navigation Ltd." 142 "TRW Automotive (Commercial Steering Systems)" 143 "W. Gmeiner GmbH & Co." 144 "Mercury Marine" 145 "MurCal Controls" 146 "Maxima Technologies" 147 "Nautibus Electronic GmbH" 148 "Blue Water Data, Inc." 149 "Holset" 150 "Fleetguard" 151 "Raven Industries Inc. - Flow Controls Division" 152 "elobau GmbH & Co. KG" 153 "Woodward, Industrial Controls Division" 154 "Westerbeke Corporation" 155 "Vetronix Corporation" 156 "ITT Industries - Cannon" 157 "ISSPRO Inc." 158 "Firestone Industrial Products Company" 159 "NTech Industries Inc." 160 "Nido" 161 "Offshore Systems (UK) Limited" 162 "Axiomatic Technologies" 163 "BRP Inc." 164 "DaimlerChrysler Off-Highway" 165 "CPAC Systems AB" 166 "Phoenix International" 167 "JLG Industries Inc." 168 "Xantrex" 169 "Marlin Technologies Inc." 170 "Computronics Corporation Ltd." 171 "Wachendorff Elektronik GmbH & Co. KG" 172 "Yanmar Marine USA" 173 "Ryeso, Inc." 174 "AB Volvo Penta" 175 "Veris Technologies, Inc." 176 "Moritz Aerospace" 177 "Diagnostic System Associates" 178 "Siemens VDO Automotive AG" 179 "TeeJet Technologies Denmark" 180 "Smart Power Systems" 181 "Coretronics, Inc." 182 "Vehicle Systems Engineering B.V." 183 "KDS Controls, Inc." 184 "EIA Electronics" 185 "Beede Electrical Instrument Company" 186 "Altronic, Inc." 187 "Air-Weigh" 188 "EMP Corp." 189 "QUALCOMM" 190 "Hella KGaA Hueck & Co." 191 "XRS Corporation" 192 "Floscan" 193 "Nobletec" 194 "TriMark Corporation" 378 "Glendinning Marine Products" 379 "Yamabiko Corporation" 380 "Suntech International Ltd." 382 "National Agricultural and Food Research Organization" 383 "MCL Industries" 384 "Camano Light" 385 "Johnson Outdoor Marine Electronics" 386 "JLG Automation BVBA" 387 "Orscheln Products, LLC" 388 "Innomatix, LLC" 389 "Benchmark Electronics, Minnesota Division" 390 "Partech Inc." 391 "Electronic Design for Industry, Inc" 392 "Tianyuan Technology Co Ltd." 393 "Harvest Tec, Inc" 394 "Capi 2 Nederland BV" 395 "GENTEC S.R.L." 396 "Beyond Measure" 397 "Sanyo-kiki Co Ltd." 398 "Hilite International" 399 "ISEKI & Co., Ltd." 400 "Livorsi Marine" 401 "Torqeedo GmbH" 402 "Simma Software, Inc." 403 "Trackwell ADS, Inc." 404 "Com Nav Marine Ltd" 405 "Wema System AS" 406 "Vecima Networks Inc." 407 "Comtech Mobile Datacom" 408 "Corvus Energy Ltd." 409 "Transfluid S.r.L." 410 "COBO S.p.A. Divisione 3B6" 411 "Hy-Drive Technologies Ltd." 412 "WebTech Wireless Inc." 413 "Datapross Nijbroek bv" 414 "Cattron Group International" 415 "Valid Manufacturing Ltd." 416 "Kubota Corporation" 417 "KZValve" 418 "Intellistick Inc" 419 "Fusion Electronics Ltd" 420 "Vermeer Corporation, ACS Group" 421 "Vertex Standard Co., Ltd" 422 "True Heading AB" 423 "BSM Wireless, Inc." 424 "Odyne LLC" 425 "Methode Electronics Inc, MDI" 426 "Egersund Marine Electronics AS" 427 "em-trak Marine Electronics Ltd" 428 "Mfg_428" 429 "Rota Engineering Ltd." 455 "ADZ NAGANO GmbH" 456 "General Kinetics" 457 "RUSELPROM-ElectricDrive Ltd" 458 "Control Solutions, Inc." 459 "Alltek Marine Electronics Corp" 1098 "Preh GmbH" 593 "Sensata Technologies" 460 "San Giorgio S.E.I.N." 267 "Red Lion Controls, Inc" 268 "Accurate Technologies" 269 "Saft America Inc.,  Space & Defense Division" 270 "Tennant" 271 "Cole Hersee" 312 "Lectronix, Inc." 313 "Ilmor Engineering, Inc" 314 "CSM GmbH" 315 "Icom Incorporated" 316 "ITT Flow Control" 317 "Navtronics Bvba" 318 "SAT Plan" 319 "Cadec Global" 320 "Miedema Landbouwwerktuigenfabriek B.V." 321 "Ultra Electronics, Electrics" 322 "MICHENKA s.r.o." 323 "Mobileye Vision Technologies Ltd." 324 "Snap-on Diagnostics" 325 "ASM Automation Sensorik Messtechnik GmbH" 326 "Akron Brass Company" 327 "Sonceboz SA" 272 "Gross Mechanical Laboratories, Inc" 273 "Active Research Limited" 274 "LTW Technology Co., LTD" 275 "Navico Egersund AS" 276 "Aqua-Hot Heating Systems" 277 "LHP Telematics" 278 "Takata Electronics" 279 "Geometris LP" 280 "Leica Geosystems Pty Ltd" 299 "Rauch Landmaschinen GmbH" 300 "Systron Donner Automotive" 301 "Parker Hannifin (UK) Ltd FDE group" 302 "Nissin Kogyo Co., LTD" 303 "CTS Corporation" 304 "EmpirBus AB" 305 "NovAtel Inc" 306 "Sleipner Motor AB" 307 "MBW Technologies" 308 "Cyntrx" 309 "Krauss-Maffei Wegmann GmbH & Co. KG" 310 "TECNORD srl" 311 "Patrick Power Products" 281 "Precision Governors LLC" 282 "Medallion Instrumentation Systems" 283 "CWF Hamilton & Co Ltd" 284 "Mobile Tech Chile" 285 "Sea Recovery Corp" 286 "Coelmo srl" 287 "NTech Industries, Inc" 288 "Mitsubishi FUSO Truck & Bus Corp." 289 "Watlow" 290 "Kuebler GmbH" 291 "Groeneveld Transport Efficiency BV" 292 "IKUSI - Angel Iglesias S.A." 293 "Spyder Controls Corp." 294 "Grayhill Inc." 295 "BEP Marine" 296 "micro dynamics GmbH" 297 "Zonar Systems Inc" 298 "Holley Performance" 253 "Mobile Control Systems" 254 "GE Sensing" 255 "MEAS France" 256 "Tyco Electronics AMP" 257 "Honda Motor Co., Ltd" 258 "ARAG" 259 "Jetter AG" 260 "Reichhardt GmbH" 261 "Red Dot Corporation" 262 "HydraForce, Inc" 263 "IMMI" 223 "Vaueo Retarder Co., Ltd." 224 "EMMI Network, S.L." 225 "SKF" 226 "Monaco Coach Corporation" 227 "Lykketronic A/S" 228 "ZF Marine Electronics" 229 "Garmin International Inc." 230 "Saucon Technologies" 231 "Topcon Positioning Systems, Inc." 0 "Reserved" 1 "Allied Signal Inc." 2 "Allison Transmission, GMC" 3 "Ametek, US Gauge Division" 4 "Ametek-Dixson" 5 "AMP Inc." 6 "Berifors Electronics AB" 7 "Case Corp." 8 "Caterpillar Inc." 9 "Chrysler Corp." 10 "Cummins Engine Co." 11 "Dearborn Group Inc." 12 "Deere & Company, Precision Farming" 13 "Delco Electronics" 14 "Detroit Diesel Corporation" 15 "Dickey-John Corp." 16 "Eaton Corp." 17 "Eaton Corp. Res & Dev" 18 "Eaton Corp, Transmission Division" 19 "Eaton Corp. Trucking Info Services" 20 "Eaton Ltd" 21 "Echilin Inc., Midland Brake Inc." 22 "Ford Motor Co., Electronic Concepts $ Systems" 23 "Ford Motor Co., Heavy Truck" 24 "Ford Motor Co., Vehicle Controls" 25 "Daimler Trucks North America LLC" 26 "General Motors Corp., Service Technology Group" 27 "GMC" 28 "Grote Ind. Inc." 29 "Hino Motors Ltd." 30 "Isuzu Motors Ltd." 31 "J Pollak Corp." 32 "Jacobs Vehicle Systems" 33 "John Deere" 34 "Kelsey Hayes Co." 35 "Kenworth Truck Co." 36 "Lucas Ltd." 37 "Mack Trucks Inc." 38 "Micro Processor Systems Inc." 39 "Microfirm Inc." 40 "Motorola AIEG Inc." 41 "Motorola Inc." 42 "International Truck and Engine Corp. Engine Electronics" 43 "International Truck and Engine Corp. Vehicle Electronics" 233 "Yacht Monitoring Solutions Inc." 249 "Schaltbau GmbH" 250 "Kuhn Group" 251 "German Agricultural Society" 252 "Sensor-Technik Wiedemann GmbH" 328 "Qwerty Electronik AB" 329 "Deif A/S" 330 "Kidde Aerospace and Defense" 331 "Horton, Inc." 332 "HWH Corporation" 333 "Hadley Products Corporation" 334 "Takata-Petri AG" 335 "Evo Electric Ltd" 336 "APE s.r.o." 337 "Carraro S.p.A." 338 "GRAF-SYTECO" 339 "Competence Center ISOBUS e.V." 340 "Continental AG" 341 "Boning GmbH & Co" 342 "THOMAS MAGNETE GmbH" 343 "Baumer Group" 344 "Parvus Corporation" 345 "Korean Maritime University" 346 "Control Solutions" 347 "Honeywell" 348 "Amazonen Werke H. Dreyer" 349 "Suonentiet" 350 "Noris Marine Systems GmbH & Co KG" 351 "Thrane & Thrane" 352 "SAME DEUTZ-FAHR" 353 "Hegemon Electronics, Inc." 354 "Junkkari OY" 355 "Mastervolt International B.V." 356 "Fischer Panda Generators, Inc" 357 "Hardi International A/S" 358 "Victron Energy BV" 359 "Ludwig Bergmann GmbH" 360 "HJS Emission Technology GmbH & Co KG" 361 "InMach" 362 "Alois Poettinger Maschinenfabrik GmbH" 363 "BEI Duncan" 364 "OEM Controls Inc." 365 "Digi-Star, LLC" 366 "Viewnyx Corp." 367 "Fliegl Agrartechnik" 368 "HANSENHOF_electronic" 369 "Power Torque Engineering Ltd" 370 "Rolls-Royce Marine AS" 371 "Heinzmann GmbH & Co. KG" 373 "Electronic Design Inc." 374 "Northern Lights, Inc." 381 "B&G" 372 "Delphi" 375 "Williams Controls Inc." 376 "Quake Global" 454 "NGK Spark Plug Co. Ltd" 480 "EnerDel, Inc." 481 "Chetco Digital Instruments" 482 "Tricon Electronics" 483 "Valeo" 484 "Headsight Inc." 485 "MATT automotive" 377 "ifm electronic gmbh" 44 "Nippondenso Co. Ltd." 45 "PACCAR" 46 "Noregon Systems, Inc" 47 "Phillips Semiconductor" 48 "Pollak Alphabet" 49 "RE America Inc." 50 "Robert Bosch Corp" 51 "Robert Bosch GmbH" 52 "Meritor Automotive, Inc." 53 "Continental Automotive Systems US, Inc." 54 "Meritor Wabco" 55 "Ryder System Inc." 56 "SAIC" 57 "Sauer-Danfoss Co." 58 "SPX Corporation, OTC Division" 59 "VES Inc." 60 "Volvo Trucks North America Inc." 61 "Volvo Truck Corp." 62 "Wabco" 63 "ZF Industries Inc." 64 "unused" 65 "MAN Nutzfahrzeuge AG" 66 "John Deere Construction Equipment Division" 67 "Funk Manufacturing Company" 68 "Scania" 69 "Trimble Navigation" 70 "Flex-Coil Limited" 71 "Vansco Electronics Ltd." 72 "Sisu Corporation" 73 "LeTourneau, Inc." 74 "Eaton Axle-Brake Division" 75 "Deere & Co. Agricultural Division" 76 "unused" 77 "Deere Power Systems Group" 78 "Frank W. Murphy Manufacturing, Inc." 79 "Daimler Benz AG - Engine Division (PBM)" 80 "Twin Disc, Inc." 81 "Fire Research Corp" 82 "Bobcat/Ingersoll-Rand" 83 "Bendix VORAD Technologies" 84 "New Holland UK Limited" 85 "Kohler Co." 86 "C.E. Niehoff & Company" 87 "J.C. Bamford Excavators Ltd (JCB)" 88 "Satloc Precision GPS" 89 "Kverneland Group, Electronics Division" 90 "Knorr-Bremse SfN GmbH" 91 "BSG Bodensee Steuergeraete GmbH" 92 "Ag-Chem Equipment Co., Inc." 93 "Perkins Engines Company Ltd." 94 "CNH Global N.V." 95 "Pacific Insight Electronics Corp." 96 "Mech@tronic IT GmbH" 97 "Ag Leader Technology, Inc." 98 "Mueller-Elektronik GmbH & Co." 99 "International Transmissions Ltd (ITL)" 100 "VDO Technik AG" 101 "Sensoria" 102 "AGCO GmbH & Co." 103 "CLAAS Agrosystems GmbH & Co. KG" 104 "Claas Selbstfahrende Erntemaschinen GmbH" 105 "Kiepe Elektrik GmbH & Co. KG" 106 "BAE Systems Controls, Inc." 107 "Grimme Landmaschinen GmbH & Co. KG" 108 "WTK-Elecktronik GmbH" 109 "TeeJet Technologies Denmark" 110 "EPIQ Sensor-Nite" 111 "Maschinenfabrik Bernard Krone GmbH" 112 "MECALAC" 113 "Stress-Tek, Inc." 461 "HAWE Hydraulik SE" 462 "IHI Shibaura Machinery Corporation" 463 "PROBOTIQ" 464 "Leach International Corporation" 465 "Ashcroft Inc" 466 "Veethree Electronics and Marine LLC" 467 "Lely Industries N.V." 468 "Tyco Fire Protection Products" 469 "RA Consulting GmbH" 470 "SI-TEX Marine Electronics" 471 "Sea Cross Marine AB" 472 "Tenneco Inc." 473 "Boss Industries, Inc." 474 "Persen Technologies Inc." 475 "GME" 476 "Hummingbird Marine Electronics" 477 "OilQuick AB" 478 "OceanSat BV" 479 "Vapor Bus International" 430 "Auteq Telematica S.A." 431 "Tohatsu Corporation" 432 "S&A Systems, Inc." 433 "Rowe Electronics" 434 "Stored Energy Systems" 435 "Zunhammer GmbH" 436 "Kinze Manufacturing" 437 "Digital Yacht Limited" 438 "Comar Systems Ltd" 439 "Hyundai Heavy Industries" 440 "Cummins Power Generation" 441 "PTG Reifendruckregelsysteme GmbH" 442 "Horsch Maschinen GmbH" 443 "SignalQuest, Inc." 444 "ITT Power Solutions" 445 "KAT MECHATRONIC, Electronic Product Division" 446 "CertTech, L.L.C." 447 "Great Plains Mfg." 448 "Stanadyne Corporation, Electronics Systems" 449 "Polaris Industries Inc" 450 "Dycor Technologies Ltd." 451 "Parker Hannifin Corp" 452 "WIKA Alexander Wiegand SE & Co. KG" 453 "Cooper Bussmann" 486 "Westport Innovations Inc." 487 "DSE Test Solutions A/S" 488 "The Charles Machine Works, Inc." 489 "Appareo Systems" 490 "QuikQ" 491 "Penny and Giles Ltd" 492 "Inergy Automotive Systems" 493 "Watcheye" 494 "Synerject" 495 "HOLMER Maschinenbau GmbH" 496 "W. Gessmann GmbH" 497 "SENTRON Sistemas Embarcados" 498 "Innovative Design Solutions, Inc." 499 "LCJ Capteurs" 500 "Oxbo International Corporation" 501 "Agrotronix S.A." 502 "Attwood Corporation" 503 "Naviop S.R.L." 504 "Vesper Marine" 505 "Yetter Farm Equipment" 506 "IHI STAR Machinery Corporation" 507 "Test Center ISOBUS" 508 "Transtech Innovations" 509 "MOTORTECH GmbH" 510 "Marinesoft Co. Ltd" 511 "Sulky" 512 "Inpower LLC" 513 "FarmscanAg" 514 "DISTek Integration, Inc." 515 "GINAF Trucks Nederland B.V." 516 "AVAT Automation GmbH" 517 "Noland Engineering" 518 "Transas USA Inc." 519 "Peeters Landbouwmachines b.v." 520 "Trapeze" ;
VAL_ 2565799818 Funct 57 "Steering Column Unit" 58 "Fan Drive Control" 59 "Starter" 60 "Cab Display" 61 "File Server/Printer" 62 "On-Board Diagnostic Unit" 63 "Engine Valve Controller" 64 "Endurance Braking" 65 "Gas Flow Measurement" 66 "I/O Controller" 67 "Electrical System Controller" 68 "Aftertreatment system gas measurement" 69 "Engine Emission Aftertreatement System" 30 "Management Computer" 31 "Propulsion Battery Charger" 104 "Reserved" 105 "Reserved" 106 "Reserved" 70 "Auxiliary Regeneration Device" 71 "Transfer Case Control" 72 "Coolant Valve Controller" 73 "Rollover Detection Control" 74 "Lubrication System" 75 "Supplemental Fan" 76 "Temperature Sensor" 77 "Fuel Properties Sensor" 78 "Fire Suppression System" 79 "Reserved" 80 "Reserved" 81 "Reserved" 82 "Reserved" 83 "Reserved" 84 "Reserved" 85 "Reserved" 86 "Reserved" 87 "Reserved" 88 "Reserved" 89 "Reserved" 90 "Reserved" 91 "Reserved" 92 "Reserved" 93 "Reserved" 94 "Reserved" 95 "Reserved" 96 "Reserved" 97 "Reserved" 98 "Reserved" 99 "Reserved" 100 "Reserved" 0 "Engine" 1 "Auxiliary Power Unit (APU)" 2 "Electric Propulsion Control" 3 "Transmission" 4 "Battery Pack Monitor" 5 "Shift Control/Console" 6 "Power TakeOff - (Main or Rear)" 7 "Axle - Steering" 8 "Axle - Drive" 9 "Brakes - System Controller" 10 "Brakes - Steer Axle" 11 "Brakes - Drive Axle" 12 "Retarder - Engine" 13 "Retarder - Driveline" 14 "Cruise Control" 15 "Fuel System" 16 "Steering Controller" 17 "Suspension - Steer Axle" 18 "Suspension - Drive Axle" 19 "Instrument Cluster" 20 "Trip Recorder" 21 "Cab Climate Control" 22 "Aerodynamic Control" 23 "Vehicle Navigation" 24 "Vehicle Security" 107 "Reserved" 108 "Reserved" 109 "Reserved" 110 "Reserved" 111 "Reserved" 112 "Reserved" 113 "Reserved" 114 "Reserved" 115 "Reserved" 116 "Reserved" 117 "Reserved" 118 "Reserved" 119 "Reserved" 120 "Reserved" 121 "Reserved" 122 "Reserved" 123 "Reserved" 124 "Reserved" 125 "Reserved" 126 "Reserved" 127 "Reserved" 25 "Network Interconnect ECU" 26 "Body Controller" 27 "Power TakeOff (Secondary or Front)" 28 "Off Vehicle Gateway" 29 "Virtual Terminal (in cab)" 43 "Transmission Display" 44 "Exhaust Emission Control" 45 "Vehicle Dynamic Stability Control" 46 "Oil Sensor Unit" 47 "Information System Controller" 48 "Ramp Control" 49 "Clutch/Converter Control" 50 "Auxiliary Heater" 51 "Forward-Looking Collision Warning System" 52 "Chassis Controller" 53 "Alternator/Charging System" 54 "Communications Unit, Cellular" 55 "Communications Unit, Satellite" 56 "Communications Unit, Radio" 32 "Headway Controller" 33 "System Monitor" 34 "Hydraulic Pump Controller" 35 "Suspension - System Controller" 36 "Pneumatic - System Controller" 37 "Cab Controller" 38 "Tire Pressure Control" 39 "Ignition Control Module" 40 "Seat Control" 41 "Lighting - Operator Controls" 42 "Water Pump Control" 101 "Reserved" 102 "Reserved" 103 "Reserved" ;
VAL_ 2565799818 IndstryGrp 7 "NotAvailable" 5 "Reserved" 4 "Marine" 3 "Construction" 2 "AgriculturalAndForestry" 1 "OnHighway" 0 "Global" ;
VAL_ 2565799818 ArbAddrCap 0 "No" 1 "Yes" ;
VAL_ 2566871586 EHR_FailSafe 0 "Neutral" 1 "Float" 2 "Reserved" 3 "Don't care" ;
VAL_ 2566871586 EHR_CntrlSts 0 "Block / Neutral" 1 "Extend" 2 "Retract" 3 "Float / open centre" 14 "Reserved" 15 "Don't care" ;
VAL_ 2566871586 EHR_EvTemp 255 "Error" ;
VAL_ 2566871586 EHR_EvFlow 255 "N/A" ;
VAL_ 2566871586 EHR_Op_2 2 "Reserved" 1 "Reserved" 0 "Goto Fialsafe" 3 "Normal Operation" ;
VAL_ 2566871586 EHR_Op_1 0 "Calibration active" 1 "Reserved" 2 "Error" 3 "Normal Operation" ;
VAL_ 2566871586 EHR_DynRmpTime 255 "N/A" ;
VAL_ 2566871586 EHR_CrvShp 0 "Curve Shape 0h" 1 "Curve Shape 1h" 2 "Curve Shape 2h" 3 "Curve Shape 3h" 4 "Curve Shape 4h" 5 "Curve Shape 5h" 6 "Curve Shape 6h" 7 "Curve Shape 7h" 8 "Curve Shape 8h" 9 "Curve Shape 9h" 10 "Curve Shape Ah" 11 "Curve Shape Bh" 12 "Curve Shape Ch" 13 "Curve Shape Dh" 14 "Curve Shape Eh" 15 "Curve Shape Fh" ;
VAL_ 2566871586 EHR_CrvGrad 255 "Error" ;
VAL_ 2566871586 EHR_Init 3 "Reserved" 2 "Reserved" 1 "Cranking" 0 "Operation" ;
VAL_ 2564487553 FlowSts 0 "Continue To Send" 1 "Wait " 2 "Overflow" ;
VAL_ 2564487553 ProtocCntrlInfo 0 "Single frame" 1 "First frame" 2 "Consecutive frame" 3 "Flow control " ;
VAL_ 2632777721 CByteTPCM 16 "RTS" 17 "CTS" 19 "EoMA" 32 "BAM" 255 "Abort" ;
VAL_ 2632777721 PGN_PktMsgTPCM_RTS 255 "NotAvailable" ;
VAL_ 2632777721 ConnAbrtReason 1 "AlreadyInConnManagedSession" 2 "NoFreeSystemResources" 3 "Timeout_CloseSession" 4 "UnexpectedDataTransferPacket" 5 "BadSequenceNumber" 6 "DuplicateSequenceNumber" 7 "AnyOtherError" ;
VAL_ 2632777721 PGN_PktMsgTPCM_ConnAbort 255 "NotAvailable" ;
VAL_ 2632777721 PGN_PktMsgTPCM_BAM 255 "NotAvailable" ;
VAL_ 2632777721 PGN_PktMsgTPCM_RTS2 255 "NotAvailable" ;
VAL_ 2632777721 PGN_PktMsgTPCM_CTS 255 "NotAvailable" ;
VAL_ 2564456697 FlowSts 0 "Continue To Send" 1 "Wait " 2 "Overflow" ;
VAL_ 2564456697 ProtocCntrlInfo 0 "Single frame" 1 "First frame" 2 "Consecutive frame" 3 "Flow control " ;
VAL_ 2564487552 FlowSts 0 "Continue To Send" 1 "Wait " 2 "Overflow" ;
VAL_ 2564487552 ProtocCntrlInfo 0 "Single frame" 1 "First frame" 2 "Consecutive frame" 3 "Flow control " ;
VAL_ 2560825102 DTCxAmbrWarnLmpSupp_andSts 2 "Reserved" 0 "Lamp OFF (Amber lamp supported)" 1 "Lamp ON (Amber lamp supported)" 3 "Amber not supported for SPN/FMI" ;
VAL_ 2560825102 DTCxFlashAmbrWarnLmpSupp_andSts 2 "Reserved" 3 "Unavailable" 0 "SlowFlash" 1 "FastFlash" ;
VAL_ 2560825102 DTCxFlashMIL_Supp_andSts 0 "SlowFlash" 1 "FastFlash" 2 "Class_C_DTC" 3 "Unavailable" ;
VAL_ 2560825102 DTCxFlashProtLmpSupp_andSts 0 "SlowFlash" 1 "FastFlash" 2 "Reserved" 3 "Unavailable" ;
VAL_ 2560825102 DTCxFlashRedStopLmpSupp_andSts 0 "SlowFlash" 1 "FastFlash" 2 "Reserved" 3 "Unavailable" ;
VAL_ 2560825102 DTCxMIL_Supp_andSts 0 "LampOff" 1 "LampOn" 2 "ShortMI" 3 "Unavailable" ;
VAL_ 2560825102 DTCxProtLmpSupp_andSts 2 "Reserved" 3 "Unavailable" 0 "LampOff" 1 "LampOn" ;
VAL_ 2560825102 DTCxRedStopLmpSupp_andSts 2 "Reserved" 0 "Lamp OFF (Red lamp supported)" 1 "Lamp ON (Red lamp supported)" 3 "Red not supported for SPN/FMI" ;
VAL_ 2632712073 SN_TPDT 255 "NoSequenceAvailable" ;
VAL_ 2632712074 SN_TPDT 255 "NoSequenceAvailable" ;
VAL_ 2632777609 CByteTPCM 16 "RTS" 17 "CTS" 19 "EoMA" 32 "BAM" 255 "Abort" ;
VAL_ 2632777609 ConnAbrtReason 1 "AlreadyInConnManagedSession" 2 "NoFreeSystemResources" 3 "Timeout_CloseSession" 4 "UnexpectedDataTransferPacket" 5 "BadSequenceNumber" 6 "DuplicateSequenceNumber" 7 "AnyOtherError" ;
VAL_ 2632777609 PGN_PktMsgTPCM_BAM 255 "NotAvailable" ;
VAL_ 2632777609 PGN_PktMsgTPCM_ConnAbort 255 "NotAvailable" ;
VAL_ 2632777609 PGN_PktMsgTPCM_CTS 255 "NotAvailable" ;
VAL_ 2632777609 PGN_PktMsgTPCM_RTS 255 "NotAvailable" ;
VAL_ 2632777609 PGN_PktMsgTPCM_RTS2 255 "NotAvailable" ;
